VERSION ""

NS_ :

BS_:

BU_: VMCU TECU OBDScanT2 IC3 EMS ECUspare2 ECUspare1 DACU CIOM BBM

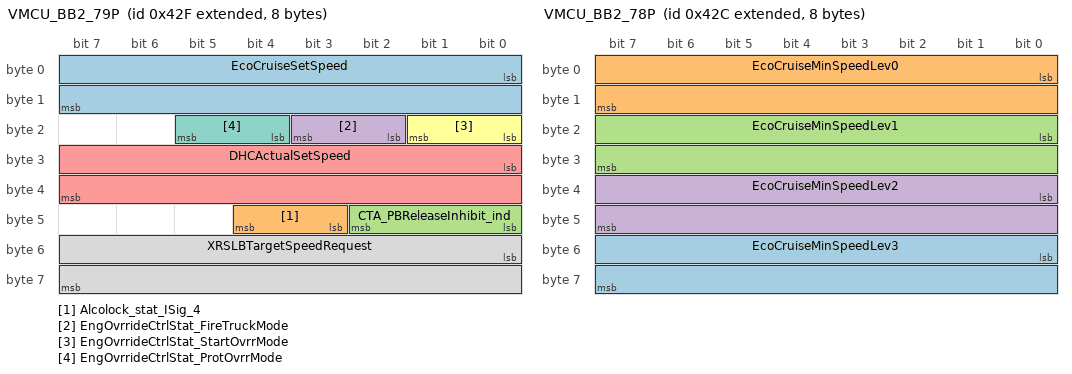
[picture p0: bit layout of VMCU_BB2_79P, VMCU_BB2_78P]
BO_ 2147484719 VMCU_BB2_79P: 8 VMCU
 SG_ EcoCruiseSetSpeed : 0|16@1+ (0.00390625,0) [0|255.99609375] "Km_per_h"  IC3
 SG_ Alcolock_stat_ISig_4 : 43|2@1+ (1,0) [0|0] ""  BBM
 SG_ CTA_PBReleaseInhibit_ind : 40|3@1+ (1,0) [0|0] ""  IC3,BBM
 SG_ EngOvrrideCtrlStat_FireTruckMode : 18|2@1+ (1,0) [0|0] ""  EMS
 SG_ DHCActualSetSpeed : 24|16@1+ (0.00390625,0) [0|255.99609375] "Km_per_h"  IC3
 SG_ EngOvrrideCtrlStat_StartOvrrMode : 16|2@1+ (1,0) [0|0] ""  EMS
 SG_ EngOvrrideCtrlStat_ProtOvrrMode : 20|2@1+ (1,0) [0|0] ""  EMS
 SG_ XRSLBTargetSpeedRequest : 48|16@1+ (0.00390625,0) [0|255.99609375] "Km_per_h"  TECU,EMS

BO_ 2147484716 VMCU_BB2_78P: 8 VMCU
 SG_ EcoCruiseMinSpeedLev3 : 48|16@1+ (0.00390625,0) [0|255.99609375] "Km_per_h"  IC3
 SG_ EcoCruiseMinSpeedLev0 : 0|16@1+ (0.00390625,0) [0|255.99609375] "Km_per_h"  IC3
 SG_ EcoCruiseMinSpeedLev1 : 16|16@1+ (0.00390625,0) [0|255.99609375] "Km_per_h"  IC3
 SG_ EcoCruiseMinSpeedLev2 : 32|16@1+ (0.00390625,0) [0|255.99609375] "Km_per_h"  IC3

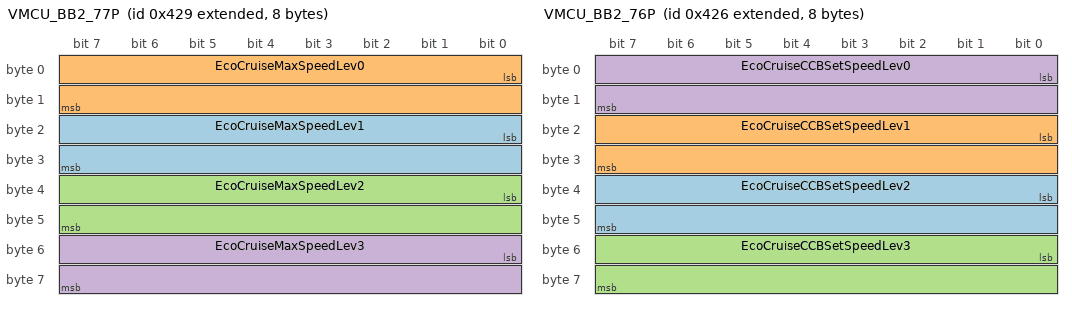
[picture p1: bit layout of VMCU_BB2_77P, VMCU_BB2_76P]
BO_ 2147484713 VMCU_BB2_77P: 8 VMCU
 SG_ EcoCruiseMaxSpeedLev1 : 16|16@1+ (0.00390625,0) [0|255.99609375] "Km_per_h"  IC3
 SG_ EcoCruiseMaxSpeedLev0 : 0|16@1+ (0.00390625,0) [0|255.99609375] "Km_per_h"  IC3
 SG_ EcoCruiseMaxSpeedLev2 : 32|16@1+ (0.00390625,0) [0|255.99609375] "Km_per_h"  IC3
 SG_ EcoCruiseMaxSpeedLev3 : 48|16@1+ (0.00390625,0) [0|255.99609375] "Km_per_h"  IC3

BO_ 2147484710 VMCU_BB2_76P: 8 VMCU
 SG_ EcoCruiseCCBSetSpeedLev2 : 32|16@1+ (0.00390625,0) [0|255.99609375] "Km_per_h"  IC3
 SG_ EcoCruiseCCBSetSpeedLev1 : 16|16@1+ (0.00390625,0) [0|255.99609375] "Km_per_h"  IC3
 SG_ EcoCruiseCCBSetSpeedLev3 : 48|16@1+ (0.00390625,0) [0|255.99609375] "Km_per_h"  IC3
 SG_ EcoCruiseCCBSetSpeedLev0 : 0|16@1+ (0.00390625,0) [0|255.99609375] "Km_per_h"  IC3

BO_ 2147485052 VMCU_BB2_75P: 8 VMCU
 SG_ EngineGreenAreaOutLNG_ISig_4 : 32|32@1+ (0.01,0) [0|42949672.95] "kg"  IC3
 SG_ EngineGreenAreaLNG_ISig_4 : 0|32@1+ (0.01,0) [0|42949672.95] "kg"  IC3

BO_ 2147484683 VMCU_BB2_74P: 8 VMCU
 SG_ BatteryTempAlert_rqst_ISig_4 : 4|3@1+ (1,0) [0|0] ""  IC3
 SG_ APM_TrailerCircPressureStatus_IS : 52|2@1+ (1,0) [0|0] ""  IC3
 SG_ BatteryCapacity_ISig_4 : 0|4@1+ (1,0) [0|0] ""  IC3
 SG_ Hazard_rqst_ISig_4 : 54|2@1+ (1,0) [0|0] ""  IC3
 SG_ CollisionSituationAliveStatus : 44|4@1+ (1,0) [0|15] "Count"  DACU
 SG_ BatterySOCact_ISig_4 : 8|8@1+ (0.5,0) [0|127.5] "Percent"  IC3
 SG_ Trailer1TPMLostCom_ISig_4 : 35|2@1+ (1,0) [0|0] ""  IC3
 SG_ BatterySOCactCriticalAlert_ISig_ : 16|8@1+ (0.5,0) [0|127.5] "Percent"  IC3
 SG_ BatteryTempAlertRawData_rqst_ISi : 32|3@1+ (1,0) [0|0] ""  IC3
 SG_ FPBRMMIStat_FPBRChangeAck_ISig_4 : 50|2@1+ (1,0) [0|0] ""  CIOM
 SG_ Trailer2TPMLostCom_UB_ISig_4 : 39|1@1+ (1,0) [0|0] ""  IC3
 SG_ LivBatteryCharging_stat_ISig_4 : 56|2@1+ (1,0) [0|0] ""  CIOM,IC3
 SG_ BatteryTemp_ISig_4 : 24|8@1+ (1,-45) [-45|210] "DegreeC"  IC3
 SG_ Trailer1TPMLostCom_UB_ISig_4 : 7|1@1+ (1,0) [0|0] ""  IC3
 SG_ FPBRMMIStat_FPBRStatusInd_ISig_4 : 48|2@1+ (1,0) [0|0] ""  CIOM
 SG_ Trailer2TPMLostCom_ISig_4 : 37|2@1+ (1,0) [0|0] ""  IC3
 SG_ CollisionSituationAliveRequest : 40|4@1+ (1,0) [0|15] "Count"  DACU

BO_ 2147484680 VMCU_BB2_73P: 8 VMCU
 SG_ TPMMateTrailerResp_ISig_4 : 32|3@1+ (1,0) [0|0] ""  IC3
 SG_ Trailer2TPMLeakageWarning_ISig_4 : 19|3@1+ (1,0) [0|0] ""  IC3
 SG_ TPMAutomaticMating_ISig_4 : 30|2@1+ (1,0) [0|0] ""  IC3
 SG_ Trailer2TPMPressureWarning_UB_IS : 55|1@1+ (1,0) [0|0] ""  IC3
 SG_ TruckTPMLeakageWarning_UB_ISig_4 : 56|1@1+ (1,0) [0|0] ""  IC3
 SG_ Trailer2TPMMatedStatus_ISig_4 : 14|2@1+ (1,0) [0|0] ""  IC3
 SG_ Trailer1TPMMatedStatus_ISig_4 : 22|2@1+ (1,0) [0|0] ""  IC3
 SG_ Trailer2TPMLeakageWarning_UB_ISi : 54|1@1+ (1,0) [0|0] ""  IC3
 SG_ Trailer1TPMLeakageWarning_UB_ISi : 52|1@1+ (1,0) [0|0] ""  IC3
 SG_ TruckTPMLeakageWarning_ISig_4 : 11|3@1+ (1,0) [0|0] ""  IC3
 SG_ Trailer1TPMPressureWarning_UB_IS : 53|1@1+ (1,0) [0|0] ""  IC3
 SG_ ExtraSideMarkers_FunctStat : 58|2@1+ (1,0) [0|0] ""  CIOM
 SG_ TruckTPMPressureWarning_UB_ISig_ : 57|1@1+ (1,0) [0|0] ""  IC3
 SG_ Trailer2TPMPressureWarning_ISig_ : 16|3@1+ (1,0) [0|0] ""  IC3
 SG_ Trailer1TPMPressureWarning_ISig_ : 24|3@1+ (1,0) [0|0] ""  IC3
 SG_ Trailer1TPMLeakageWarning_ISig_4 : 27|3@1+ (1,0) [0|0] ""  IC3
 SG_ LiftAxle1RequestResponse : 35|4@1+ (1,0) [0|0] ""  IC3
 SG_ TruckTPMPressureWarning_ISig_4 : 8|3@1+ (1,0) [0|0] ""  IC3
 SG_ XRSLIndication : 0|8@1+ (1,0) [0|255] "Km_per_h"  BBM,IC3
 SG_ TPMMateTrailerResp_UB_ISig_4 : 39|1@1+ (1,0) [0|0] ""  IC3

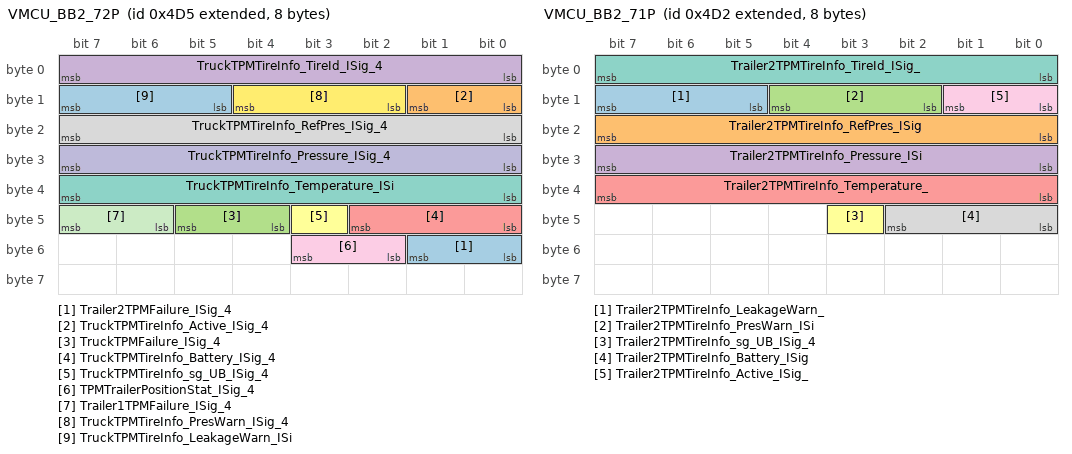
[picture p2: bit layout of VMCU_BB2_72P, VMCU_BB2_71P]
BO_ 2147484885 VMCU_BB2_72P: 8 VMCU
 SG_ Trailer2TPMFailure_ISig_4 : 48|2@1+ (1,0) [0|0] ""  IC3
 SG_ TruckTPMTireInfo_Active_ISig_4 : 8|2@1+ (1,0) [0|0] ""  IC3
 SG_ TruckTPMFailure_ISig_4 : 44|2@1+ (1,0) [0|0] ""  IC3
 SG_ TruckTPMTireInfo_TireId_ISig_4 : 0|8@1+ (1,0) [0|255] "NotApplicable"  IC3
 SG_ TruckTPMTireInfo_Battery_ISig_4 : 40|3@1+ (1,0) [0|0] ""  IC3
 SG_ TruckTPMTireInfo_sg_UB_ISig_4 : 43|1@1+ (1,0) [0|0] ""  IC3
 SG_ TruckTPMTireInfo_Temperature_ISi : 32|8@1+ (1,-50) [-50|205] "DegreeC"  IC3
 SG_ TruckTPMTireInfo_RefPres_ISig_4 : 16|8@1+ (10,0) [0|2550] "kPa"  IC3
 SG_ TPMTrailerPositionStat_ISig_4 : 50|2@1+ (1,0) [0|0] ""  IC3
 SG_ TruckTPMTireInfo_Pressure_ISig_4 : 24|8@1+ (10,0) [0|2550] "kPa"  IC3
 SG_ Trailer1TPMFailure_ISig_4 : 46|2@1+ (1,0) [0|0] ""  IC3
 SG_ TruckTPMTireInfo_PresWarn_ISig_4 : 10|3@1+ (1,0) [0|0] ""  IC3
 SG_ TruckTPMTireInfo_LeakageWarn_ISi : 13|3@1+ (1,0) [0|0] ""  IC3

BO_ 2147484882 VMCU_BB2_71P: 8 VMCU
 SG_ Trailer2TPMTireInfo_LeakageWarn_ : 13|3@1+ (1,0) [0|0] ""  IC3
 SG_ Trailer2TPMTireInfo_RefPres_ISig : 16|8@1+ (10,0) [0|2550] "kPa"  IC3
 SG_ Trailer2TPMTireInfo_PresWarn_ISi : 10|3@1+ (1,0) [0|0] ""  IC3
 SG_ Trailer2TPMTireInfo_Pressure_ISi : 24|8@1+ (10,0) [0|2550] "kPa"  IC3
 SG_ Trailer2TPMTireInfo_Temperature_ : 32|8@1+ (1,-50) [-50|205] "DegreeC"  IC3
 SG_ Trailer2TPMTireInfo_sg_UB_ISig_4 : 43|1@1+ (1,0) [0|0] ""  IC3
 SG_ Trailer2TPMTireInfo_TireId_ISig_ : 0|8@1+ (1,0) [0|255] "NotApplicable"  IC3
 SG_ Trailer2TPMTireInfo_Battery_ISig : 40|3@1+ (1,0) [0|0] ""  IC3
 SG_ Trailer2TPMTireInfo_Active_ISig_ : 8|2@1+ (1,0) [0|0] ""  IC3

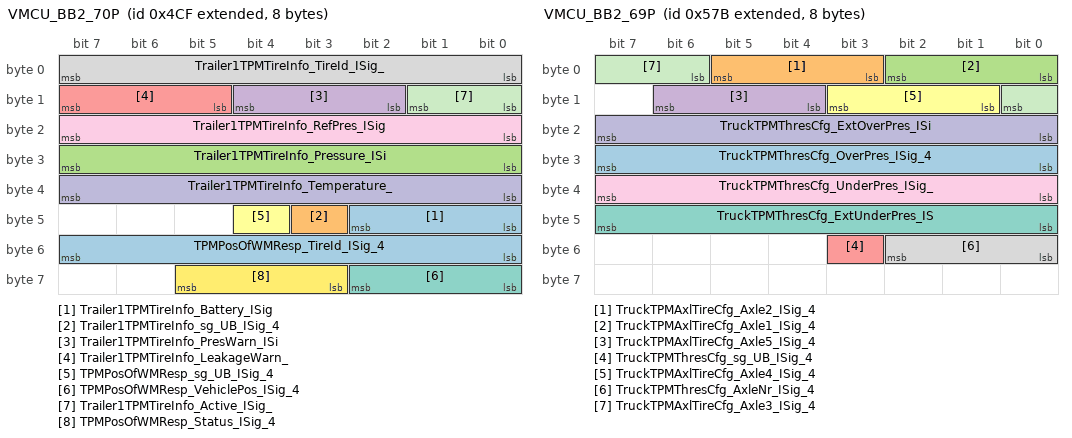
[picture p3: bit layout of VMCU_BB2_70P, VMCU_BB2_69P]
BO_ 2147484879 VMCU_BB2_70P: 8 VMCU
 SG_ Trailer1TPMTireInfo_Battery_ISig : 40|3@1+ (1,0) [0|0] ""  IC3
 SG_ Trailer1TPMTireInfo_sg_UB_ISig_4 : 43|1@1+ (1,0) [0|0] ""  IC3
 SG_ Trailer1TPMTireInfo_Pressure_ISi : 24|8@1+ (10,0) [0|2550] "kPa"  IC3
 SG_ Trailer1TPMTireInfo_PresWarn_ISi : 10|3@1+ (1,0) [0|0] ""  IC3
 SG_ Trailer1TPMTireInfo_LeakageWarn_ : 13|3@1+ (1,0) [0|0] ""  IC3
 SG_ TPMPosOfWMResp_sg_UB_ISig_4 : 44|1@1+ (1,0) [0|0] ""  IC3
 SG_ TPMPosOfWMResp_VehiclePos_ISig_4 : 56|3@1+ (1,0) [0|0] ""  IC3
 SG_ Trailer1TPMTireInfo_TireId_ISig_ : 0|8@1+ (1,0) [0|255] "NotApplicable"  IC3
 SG_ Trailer1TPMTireInfo_RefPres_ISig : 16|8@1+ (10,0) [0|2550] "kPa"  IC3
 SG_ Trailer1TPMTireInfo_Temperature_ : 32|8@1+ (1,-50) [-50|205] "DegreeC"  IC3
 SG_ Trailer1TPMTireInfo_Active_ISig_ : 8|2@1+ (1,0) [0|0] ""  IC3
 SG_ TPMPosOfWMResp_Status_ISig_4 : 59|3@1+ (1,0) [0|0] ""  IC3
 SG_ TPMPosOfWMResp_TireId_ISig_4 : 48|8@1+ (1,0) [0|255] "NotApplicable"  IC3

BO_ 2147485051 VMCU_BB2_69P: 8 VMCU
 SG_ TruckTPMThresCfg_OverPres_ISig_4 : 24|8@1+ (1,-125) [-125|130] "Percent"  IC3
 SG_ TruckTPMAxlTireCfg_Axle2_ISig_4 : 3|3@1+ (1,0) [0|0] ""  IC3
 SG_ TruckTPMAxlTireCfg_Axle1_ISig_4 : 0|3@1+ (1,0) [0|0] ""  IC3
 SG_ TruckTPMAxlTireCfg_Axle5_ISig_4 : 12|3@1+ (1,0) [0|0] ""  IC3
 SG_ TruckTPMThresCfg_sg_UB_ISig_4 : 51|1@1+ (1,0) [0|0] ""  IC3
 SG_ TruckTPMAxlTireCfg_Axle4_ISig_4 : 9|3@1+ (1,0) [0|0] ""  IC3
 SG_ TruckTPMThresCfg_ExtUnderPres_IS : 40|8@1+ (1,-125) [-125|130] "Percent"  IC3
 SG_ TruckTPMThresCfg_AxleNr_ISig_4 : 48|3@1+ (1,0) [0|0] ""  IC3
 SG_ TruckTPMThresCfg_UnderPres_ISig_ : 32|8@1+ (1,-125) [-125|130] "Percent"  IC3
 SG_ TruckTPMThresCfg_ExtOverPres_ISi : 16|8@1+ (1,-125) [-125|130] "Percent"  IC3
 SG_ TruckTPMAxlTireCfg_Axle3_ISig_4 : 6|3@1+ (1,0) [0|0] ""  IC3

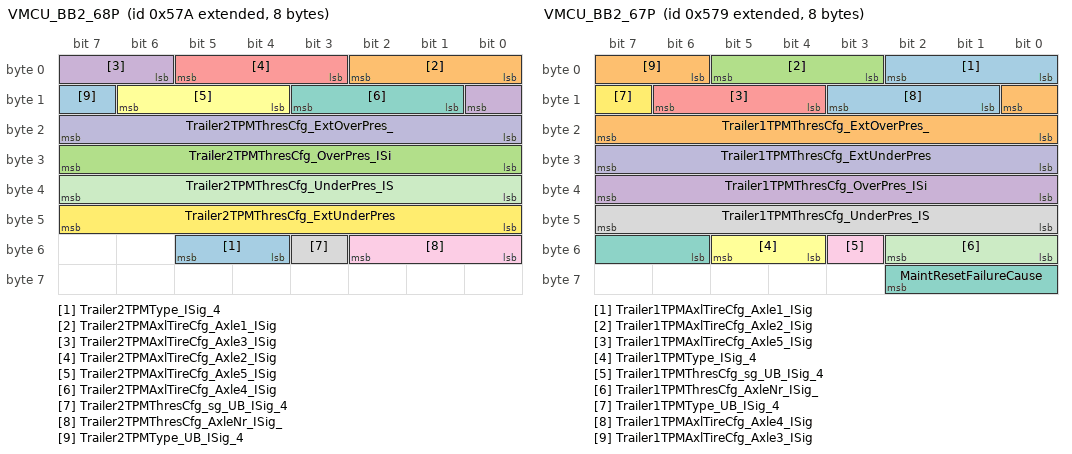
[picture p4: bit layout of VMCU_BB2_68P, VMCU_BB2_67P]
BO_ 2147485050 VMCU_BB2_68P: 8 VMCU
 SG_ Trailer2TPMType_ISig_4 : 52|2@1+ (1,0) [0|0] ""  IC3
 SG_ Trailer2TPMAxlTireCfg_Axle1_ISig : 0|3@1+ (1,0) [0|0] ""  IC3
 SG_ Trailer2TPMThresCfg_OverPres_ISi : 24|8@1+ (1,-125) [-125|130] "Percent"  IC3
 SG_ Trailer2TPMAxlTireCfg_Axle3_ISig : 6|3@1+ (1,0) [0|0] ""  IC3
 SG_ Trailer2TPMAxlTireCfg_Axle2_ISig : 3|3@1+ (1,0) [0|0] ""  IC3
 SG_ Trailer2TPMAxlTireCfg_Axle5_ISig : 12|3@1+ (1,0) [0|0] ""  IC3
 SG_ Trailer2TPMAxlTireCfg_Axle4_ISig : 9|3@1+ (1,0) [0|0] ""  IC3
 SG_ Trailer2TPMThresCfg_sg_UB_ISig_4 : 51|1@1+ (1,0) [0|0] ""  IC3
 SG_ Trailer2TPMThresCfg_AxleNr_ISig_ : 48|3@1+ (1,0) [0|0] ""  IC3
 SG_ Trailer2TPMThresCfg_ExtOverPres_ : 16|8@1+ (1,-125) [-125|130] "Percent"  IC3
 SG_ Trailer2TPMThresCfg_UnderPres_IS : 32|8@1+ (1,-125) [-125|130] "Percent"  IC3
 SG_ Trailer2TPMThresCfg_ExtUnderPres : 40|8@1+ (1,-125) [-125|130] "Percent"  IC3
 SG_ Trailer2TPMType_UB_ISig_4 : 15|1@1+ (1,0) [0|0] ""  IC3

BO_ 2147485049 VMCU_BB2_67P: 8 VMCU
 SG_ Trailer1TPMAxlTireCfg_Axle1_ISig : 0|3@1+ (1,0) [0|0] ""  IC3
 SG_ Trailer1TPMThresCfg_ExtOverPres_ : 16|8@1+ (1,-125) [-125|130] "Percent"  IC3
 SG_ Trailer1TPMAxlTireCfg_Axle2_ISig : 3|3@1+ (1,0) [0|0] ""  IC3
 SG_ Trailer1TPMThresCfg_OverPres_ISi : 32|8@1+ (1,-125) [-125|130] "Percent"  IC3
 SG_ Trailer1TPMAxlTireCfg_Axle5_ISig : 12|3@1+ (1,0) [0|0] ""  IC3
 SG_ Trailer1TPMType_ISig_4 : 52|2@1+ (1,0) [0|0] ""  IC3
 SG_ MaintResetFailureCause : 54|5@1+ (1,0) [0|0] ""  IC3
 SG_ Trailer1TPMThresCfg_UnderPres_IS : 40|8@1+ (1,-125) [-125|130] "Percent"  IC3
 SG_ Trailer1TPMThresCfg_sg_UB_ISig_4 : 51|1@1+ (1,0) [0|0] ""  IC3
 SG_ Trailer1TPMThresCfg_ExtUnderPres : 24|8@1+ (1,-125) [-125|130] "Percent"  IC3
 SG_ Trailer1TPMThresCfg_AxleNr_ISig_ : 48|3@1+ (1,0) [0|0] ""  IC3
 SG_ Trailer1TPMType_UB_ISig_4 : 15|1@1+ (1,0) [0|0] ""  IC3
 SG_ Trailer1TPMAxlTireCfg_Axle4_ISig : 9|3@1+ (1,0) [0|0] ""  IC3
 SG_ Trailer1TPMAxlTireCfg_Axle3_ISig : 6|3@1+ (1,0) [0|0] ""  IC3

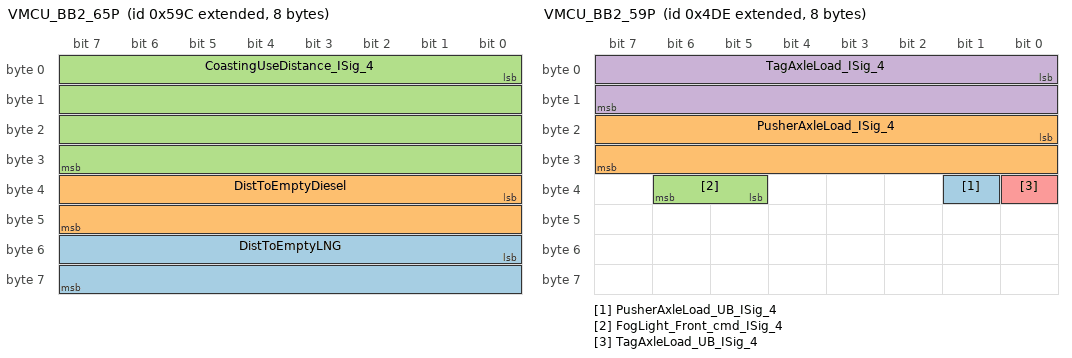
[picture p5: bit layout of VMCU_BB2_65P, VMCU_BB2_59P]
BO_ 2147485084 VMCU_BB2_65P: 8 VMCU
 SG_ DistToEmptyLNG : 48|16@1+ (1,0) [0|65535] "km"  IC3
 SG_ DistToEmptyDiesel : 32|16@1+ (1,0) [0|65535] "km"  IC3
 SG_ CoastingUseDistance_ISig_4 : 0|32@1+ (10,0) [0|42949672950] "m"  IC3

BO_ 2147485083 VMCU_BB2_64P: 8 VMCU
 SG_ EngSpeedOverThresholdTime_ISig_4 : 32|32@1+ (1,0) [0|4294967295] "s"  IC3
 SG_ EngLoadOverThresholdDistance_ISi : 0|32@1+ (10,0) [0|42949672950] "m"  IC3

BO_ 2147485082 VMCU_BB2_63P: 8 VMCU
 SG_ EngineGreenAreaFuel_ISig_4 : 32|32@1+ (0.01,0) [0|42949672.95] "l"  IC3
 SG_ LCCDistance_ISig_4 : 0|32@1+ (10,0) [0|42949672950] "m"  IC3

BO_ 2147485081 VMCU_BB2_62P: 8 VMCU
 SG_ StopCounter_ISig_4 : 0|32@1+ (1,0) [0|4294967295] ""  IC3
 SG_ OverspeedDistance_ISig_4 : 32|32@1+ (10,0) [0|42949672950] "m"  IC3

BO_ 2147485080 VMCU_BB2_61P: 8 VMCU
 SG_ RobotizedGboxPowerModeTime_ISig_ : 0|32@1+ (1,0) [0|4294967295] "s"  IC3
 SG_ TotalServiceBrakeCounter_ISig_4 : 32|32@1+ (1,0) [0|4294967295] ""  IC3

BO_ 2147485079 VMCU_BB2_60P: 8 VMCU
 SG_ RobotizedGboxManualModeTime_ISig : 32|32@1+ (1,0) [0|4294967295] "s"  IC3
 SG_ RobotizedGboxAutoModeTime_ISig_4 : 0|32@1+ (1,0) [0|4294967295] "s"  IC3

BO_ 2147484894 VMCU_BB2_59P: 8 VMCU
 SG_ PusherAxleLoad_UB_ISig_4 : 33|1@1+ (1,0) [0|0] ""  TECU,BBM,DACU,IC3
 SG_ PusherAxleLoad_ISig_4 : 16|16@1+ (0.5,0) [0|32767.5] "kg"  TECU,BBM,DACU
 SG_ FogLight_Front_cmd_ISig_4 : 37|2@1+ (1,0) [0|0] ""  BBM
 SG_ TagAxleLoad_ISig_4 : 0|16@1+ (0.5,0) [0|32767.5] "kg"  TECU,DACU,BBM
 SG_ TagAxleLoad_UB_ISig_4 : 32|1@1+ (1,0) [0|0] ""  BBM,IC3,DACU,TECU

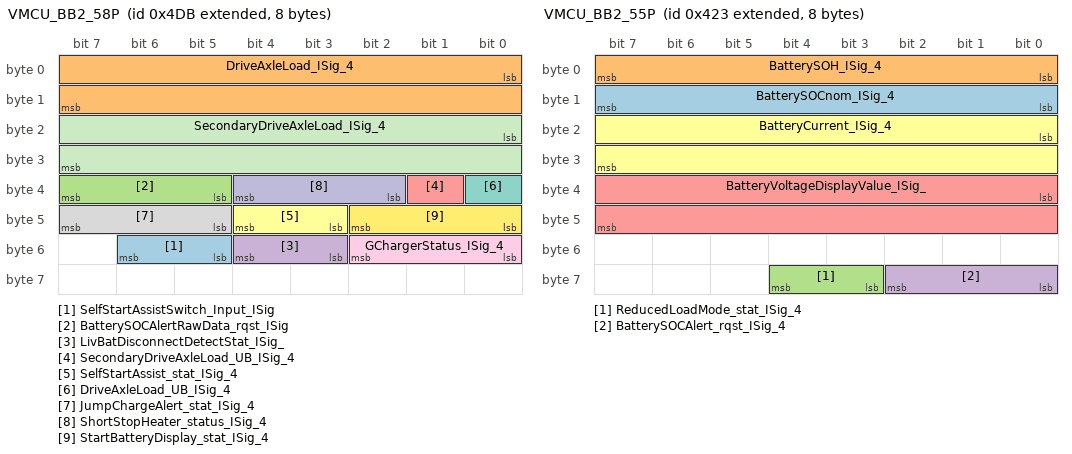
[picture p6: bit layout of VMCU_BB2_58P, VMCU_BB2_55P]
BO_ 2147484891 VMCU_BB2_58P: 8 VMCU
 SG_ SelfStartAssistSwitch_Input_ISig : 53|2@1+ (1,0) [0|0] ""  IC3
 SG_ DriveAxleLoad_ISig_4 : 0|16@1+ (0.5,0) [0|32767.5] "kg"  BBM,DACU,TECU
 SG_ BatterySOCAlertRawData_rqst_ISig : 37|3@1+ (1,0) [0|0] ""  BBM,CIOM
 SG_ LivBatDisconnectDetectStat_ISig_ : 51|2@1+ (1,0) [0|0] ""  IC3
 SG_ SecondaryDriveAxleLoad_UB_ISig_4 : 33|1@1+ (1,0) [0|0] ""  IC3,TECU,BBM,DACU
 SG_ SelfStartAssist_stat_ISig_4 : 43|2@1+ (1,0) [0|0] ""  EMS,IC3
 SG_ DriveAxleLoad_UB_ISig_4 : 32|1@1+ (1,0) [0|0] ""  BBM,IC3,TECU,DACU
 SG_ JumpChargeAlert_stat_ISig_4 : 45|3@1+ (1,0) [0|0] ""  IC3
 SG_ GChargerStatus_ISig_4 : 48|3@1+ (1,0) [0|0] ""  IC3
 SG_ ShortStopHeater_status_ISig_4 : 34|3@1+ (1,0) [0|0] ""  CIOM
 SG_ SecondaryDriveAxleLoad_ISig_4 : 16|16@1+ (0.5,0) [0|32767.5] "kg"  DACU,BBM,TECU
 SG_ StartBatteryDisplay_stat_ISig_4 : 40|3@1+ (1,0) [0|0] ""  IC3

BO_ 2147485057 VMCU_BB2_57P_HMIIOM_FCM: 8 IC3
 SG_ VMCU_BB2_57P_FCS_581 : 0|64@1+ (1,0) [0|0] ""  VMCU

BO_ 2147485056 VMCU_BB2_57P_HMIIOM: 15 VMCU
 SG_ MaintService_ServiceCalendarTime : 32|32@1+ (1,-2147483600) [-2147483600|2147483695] "s"  IC3
 SG_ MaintService_EngTimeID_ISig_4_58 : 112|8@1+ (1,0) [0|255] "ID"  IC3
 SG_ MaintService_DistID_ISig_4_580 : 96|8@1+ (1,0) [0|255] "ID"  IC3
 SG_ MaintService_ServiceDistance_ISi : 0|32@1+ (10,-21474836000) [-21474836000|21474836950] "m"  IC3
 SG_ MaintService_ServiceEngineTime_I : 64|32@1+ (1,-2147483600) [-2147483600|2147483695] "s"  IC3
 SG_ MaintService_CalDateID_ISig_4_58 : 104|8@1+ (1,0) [0|255] "ID"  IC3

BO_ 2147485047 VMCU_BB2_57P_FCM: 8 CIOM
 SG_ VMCU_BB2_57P_FCS_577 : 0|64@1+ (1,0) [0|0] ""  VMCU

BO_ 2147485046 VMCU_BB2_57P: 15 VMCU
 SG_ MaintService_ServiceEngineT_0000 : 64|32@1+ (1,-2147483600) [-2147483600|2147483695] "s"  CIOM
 SG_ MaintService_EngTimeID_ISig_4_57 : 112|8@1+ (1,0) [0|255] "ID"  CIOM
 SG_ MaintService_DistID_ISig_4_576 : 96|8@1+ (1,0) [0|255] "ID"  CIOM
 SG_ MaintService_ServiceDistanc_0000 : 0|32@1+ (10,-21474836000) [-21474836000|21474836950] "m"  CIOM
 SG_ MaintService_CalDateID_ISig_4_57 : 104|8@1+ (1,0) [0|255] "ID"  CIOM
 SG_ MaintService_ServiceCalenda_0000 : 32|32@1+ (1,-2147483600) [-2147483600|2147483695] "s"  CIOM

BO_ 2147485076 VMCU_BB2_56P: 8 VMCU
 SG_ EngTrueIdleSpeedTime_ISig_4 : 0|32@1+ (1,0) [0|4294967295] "s"  IC3
 SG_ EngineGreenAreaOutTime_ISig_4 : 32|32@1+ (1,0) [0|4294967295] "s"  IC3

BO_ 2147484707 VMCU_BB2_55P: 8 VMCU
 SG_ BatterySOCnom_ISig_4 : 8|8@1+ (0.5,0) [0|127.5] "Percent"  IC3
 SG_ BatterySOH_ISig_4 : 0|8@1+ (0.5,0) [0|127.5] "Percent"  IC3
 SG_ ReducedLoadMode_stat_ISig_4 : 59|2@1+ (1,0) [0|0] ""  CIOM
 SG_ BatterySOCAlert_rqst_ISig_4 : 56|3@1+ (1,0) [0|0] ""  IC3,BBM,CIOM
 SG_ BatteryVoltageDisplayValue_ISig_ : 32|16@1+ (0.05,0) [0|3276.75] "V"  IC3,BBM
 SG_ BatteryCurrent_ISig_4 : 16|16@1+ (0.05,-1600) [-1600|1676.75] "A"  EMS,IC3

BO_ 2147484573 VMCU_BB2_54P: 8 VMCU
 SG_ MaintOilQuality : 35|3@1+ (1,0) [0|0] ""  EMS
 SG_ ECSLimpHomeNotification_ISig_4 : 16|3@1+ (1,0) [0|0] ""  IC3
 SG_ MaintenanceResetStatus : 19|3@1+ (1,0) [0|0] ""  IC3
 SG_ FirstAxleLowerPrioSelected_ISig_ : 24|3@1+ (1,0) [0|0] ""  IC3
 SG_ MaintOilReset : 38|2@1+ (1,0) [0|0] ""  EMS
 SG_ RssInhibStartEngine_rqst : 6|2@1+ (1,0) [0|0] ""  IC3
 SG_ PositionLightRequest_status : 2|2@1+ (1,0) [0|0] ""  BBM,IC3
 SG_ ExtraBBTailLiftStatus_ISig_4 : 4|2@1+ (1,0) [0|0] ""  CIOM
 SG_ MaintenanceNotification_ISig_4 : 32|3@1+ (1,0) [0|0] ""  IC3
 SG_ ExtraBBSlidable5thWheelStatus : 0|2@1+ (1,0) [0|0] ""  BBM,CIOM
 SG_ ParkBrakeReleasePossible_stat : 10|2@1+ (1,0) [0|0] ""  TECU,IC3
 SG_ LoadDistributionALDChangeACK_ISi : 48|3@1+ (1,0) [0|0] ""  CIOM,IC3
 SG_ PoorAirPressureInfo_UB : 55|1@1+ (1,0) [0|0] ""  BBM,IC3
 SG_ ParkBrakeWorkshopMode_ISig_4 : 14|2@1+ (1,0) [0|0] ""  IC3
 SG_ ExtraBBContainerUnlockStatus : 46|2@1+ (1,0) [0|0] ""  BBM,CIOM
 SG_ MainBeamRequest_status_ISig_4 : 56|2@1+ (1,0) [0|0] ""  BBM,DACU
 SG_ ExtraBBCraneStatus_ISig_4 : 27|3@1+ (1,0) [0|0] ""  CIOM,BBM
 SG_ AirCompressorStatus : 58|2@1+ (1,0) [0|0] ""  EMS,BBM
 SG_ TrailerABSStatus_ISig_4 : 12|2@1+ (1,0) [0|0] ""  TECU,IC3,EMS,DACU
 SG_ RegenInhibitVehicleHeight_ISig_4 : 22|2@1+ (1,0) [0|0] ""  EMS
 SG_ PoorAirPressureInfo : 51|2@1+ (1,0) [0|0] ""  BBM,IC3
 SG_ FogLightRearRequest_stat : 8|2@1+ (1,0) [0|0] ""  BBM
 SG_ MainBeam_cmd_ISig_4 : 60|3@1+ (1,0) [0|0] ""  BBM
 SG_ FrontParkBrakeOverrideInd_ISig_4 : 53|2@1+ (1,0) [0|0] ""  IC3

BO_ 2147484497 VMCU_BB2_53P: 8 VMCU
 SG_ AuxSwitchBbLoad4_cmd : 14|2@1+ (1,0) [0|0] ""  BBM
 SG_ AuxSwitchBbLoad1_Status_ISig_4 : 0|2@1+ (1,0) [0|0] ""  CIOM,BBM
 SG_ BrakeLightConvoy_rqst_UB_ISig_4 : 45|1@1+ (1,0) [0|0] ""  BBM
 SG_ AuxSwitchBbLoad3_cmd : 12|2@1+ (1,0) [0|0] ""  BBM
 SG_ MainBeam_rqst : 40|3@1+ (1,0) [0|0] ""  IC3
 SG_ BatterySOCTrustLevel_ISig_4 : 56|8@1+ (0.5,0) [0|127.5] "Percent"  IC3
 SG_ AuxSwitchBbLoad4_Status_ISig_4 : 6|2@1+ (1,0) [0|0] ""  CIOM,BBM
 SG_ BrakeLightConvoy_rqst_ISig_4 : 30|2@1+ (1,0) [0|0] ""  BBM
 SG_ DoorWarningLight_cmd_ISig_4 : 38|2@1+ (1,0) [0|0] ""  CIOM
 SG_ BlackOutandConvoyMode_rqst_ISig_ : 35|3@1+ (1,0) [0|0] ""  IC3,DACU,BBM
 SG_ DirIndicatorRqstLights_stat : 32|3@1+ (1,0) [0|0] ""  BBM
 SG_ DippedBeamRequest_status : 24|2@1+ (1,0) [0|0] ""  BBM
 SG_ AuxSwitchBbLoad3_Status_ISig_4 : 4|2@1+ (1,0) [0|0] ""  CIOM,BBM
 SG_ DoorInstepLight_cmd_ISig_4 : 43|2@1+ (1,0) [0|0] ""  CIOM
 SG_ DRLRequest_status : 26|2@1+ (1,0) [0|0] ""  BBM
 SG_ AuxSwitchBbLoad6_Status_ISig_4 : 10|2@1+ (1,0) [0|0] ""  BBM,CIOM
 SG_ AuxSwitchBbLoad2_Status_ISig_4 : 2|2@1+ (1,0) [0|0] ""  CIOM,BBM
 SG_ AuxSwitchBbLoad5_cmd : 16|2@1+ (1,0) [0|0] ""  BBM
 SG_ PBReleaseInhibit_EPBState_ISig_4 : 48|3@1+ (1,0) [0|0] ""  BBM
 SG_ ExtStaticTrailerBrake_Stat_ISig_ : 46|2@1+ (1,0) [0|0] ""  IC3,BBM
 SG_ AuxSwitchBbLoad5_Status_ISig_4 : 8|2@1+ (1,0) [0|0] ""  CIOM,BBM
 SG_ DoubleFrontAxleSteeringWarning_I : 20|2@1+ (1,0) [0|0] ""  IC3
 SG_ AuxSwitchBbLoad6_cmd : 18|2@1+ (1,0) [0|0] ""  BBM
 SG_ AcceleratorPedalTestStatus : 51|3@1+ (1,0) [0|0] ""  IC3

CM_ SG_ 2147485052 EngineGreenAreaOutLNG_ISig_4 "4294967295 Not available
";
CM_ SG_ 2147484894 PusherAxleLoad_ISig_4 "65024 - 65279 Error ; 65280 - 65535 Not available";
CM_ SG_ 2147484894 TagAxleLoad_ISig_4 "65024 - 65279 Error ; 65280 - 65535 Not available";
CM_ SG_ 2147484891 DriveAxleLoad_ISig_4 "65024 - 65279 Error ; 65280 - 65535 Not available";
CM_ SG_ 2147484891 SecondaryDriveAxleLoad_ISig_4 "65024 - 65279 Error ; 65280 - 65535 Not available";
CM_ SG_ 2147485076 EngTrueIdleSpeedTime_ISig_4 "4294967295 Not available";
CM_ SG_ 2147485076 EngineGreenAreaOutTime_ISig_4 "4294967295 Not available";
CM_ SG_ 2147484707 BatterySOCnom_ISig_4 "254 Error ; 255 Not available";
CM_ SG_ 2147484707 BatterySOH_ISig_4 "254 Error ; 255 Not available";
CM_ SG_ 2147484707 BatteryVoltageDisplayValue_ISig_ "65024 - 65279 Error ; 65280 - 65535 Not available";
CM_ SG_ 2147484707 BatteryCurrent_ISig_4 "65024 - 65279 Error ; 65280 - 65535 Not available";
BA_DEF_ BO_  "GenMsgStartDelayTime" INT 0 0;
BA_DEF_ BO_  "GenMsgDelayTime" INT 0 0;
BA_DEF_ BO_  "GenMsgCycleTime" INT 0 0;
BA_DEF_ BO_  "GenMsgSendType" ENUM  "Cyclic","NotUsed","NotUsed","NotUsed","NotUsed","NotUsed","NotUsed","IfActive","NoMsgSendType","NotUsed";
BA_DEF_ SG_  "GenSigStartValue" INT 0 0;
BA_DEF_ SG_  "GenSigCycleTimeActive" INT 0 0;
BA_DEF_ SG_  "GenSigCycleTime" INT 0 0;
BA_DEF_ SG_  "GenSigSendType" ENUM  "Cyclic","OnWrite","OnWriteWithRepetition","OnChange","OnChangeWithRepetition","IfActive","IfActiveWithRepetition","NoSigSendType","NotUsed","NotUsed","NotUsed","NotUsed","NotUsed";
BA_DEF_ BO_  "VFrameFormat" ENUM  "StandardCAN","ExtendedCAN","reserved","J1939PG";
BA_DEF_ SG_  "SigType" ENUM  "Default","Range","RangeSigned","ASCII","Discrete","Control","ReferencePGN","DTC","StringDelimiter","StringLength","StringLengthControl";
BA_DEF_ SG_  "SeToolVersion_SIGNAL" STRING ;
BA_DEF_ SG_  "SeToolUniqueID_SIGNAL" STRING ;
BA_DEF_ SG_  "SeToolOwnerSigGroup_SIGNAL" STRING ;
BA_DEF_ SG_  "SeToolOwnerSigGroupID_SIGNAL" STRING ;
BA_DEF_ SG_  "SeToolName_SIGNAL" STRING ;
BA_DEF_ SG_  "SeToolItemID_SIGNAL" STRING ;
BA_DEF_ SG_  "SeToolAncestorID_SIGNAL" STRING ;
BA_DEF_ SG_  "Platform_VMCU1_Sig" ENUM  "No","Yes";
BA_DEF_ BO_  "NmAsrMessage" ENUM  "No","Yes";
BA_DEF_ SG_  "NeedsUpdateBit" ENUM  "No","Yes";
BA_DEF_ SG_  "MmAnSignal" ENUM  "No","Yes";
BA_DEF_ SG_  "GenSigMaxLatency" INT 0 65535;
BA_DEF_ SG_  "GenSigILSupport" ENUM  "Yes","No";
BA_DEF_ BO_  "GenMsgRequestable" INT 0 1;
BA_DEF_ BO_  "GenMsgILSupport" ENUM  "No","Yes";
BA_DEF_ BO_  "DiagUUDTResponse" ENUM  "No","Yes";
BA_DEF_ BO_  "DiagState" ENUM  "No","Yes";
BA_DEF_ BO_  "DiagResponse" ENUM  "No","Yes";
BA_DEF_ BO_  "DiagRequest" ENUM  "No","Yes";
BA_DEF_ BO_  "DiagConnection" HEX 0 65535;
BA_DEF_ BO_  "CanTpSTmin" INT 0 255;
BA_DEF_ BO_  "CanTpFcFrameId" HEX 0 2147483647;
BA_DEF_ BO_  "CanTpBs" INT 0 255;
BA_DEF_ SG_  "SystemSignalLongSymbol" STRING ;
BA_DEF_REL_ BU_SG_REL_  "GenSigTimeoutTime" INT 0 65535;
BA_DEF_REL_ BU_SG_REL_  "GenSigFirstTimeoutTime" INT 0 65535;
BA_DEF_DEF_  "GenMsgStartDelayTime" 0;
BA_DEF_DEF_  "GenMsgDelayTime" 0;
BA_DEF_DEF_  "GenMsgCycleTime" 0;
BA_DEF_DEF_  "GenMsgSendType" "Cyclic";
BA_DEF_DEF_  "GenSigStartValue" 0;
BA_DEF_DEF_  "GenSigCycleTimeActive" 0;
BA_DEF_DEF_  "GenSigCycleTime" 0;
BA_DEF_DEF_  "GenSigSendType" "Cyclic";
BA_DEF_DEF_  "VFrameFormat" "ExtendedCAN";
BA_DEF_DEF_  "SigType" "Default";
BA_DEF_DEF_  "SeToolVersion_SIGNAL" "";
BA_DEF_DEF_  "SeToolUniqueID_SIGNAL" "";
BA_DEF_DEF_  "SeToolOwnerSigGroup_SIGNAL" "";
BA_DEF_DEF_  "SeToolOwnerSigGroupID_SIGNAL" "";
BA_DEF_DEF_  "SeToolName_SIGNAL" "";
BA_DEF_DEF_  "SeToolItemID_SIGNAL" "";
BA_DEF_DEF_  "SeToolAncestorID_SIGNAL" "";
BA_DEF_DEF_  "Platform_VMCU1_Sig" "No";
BA_DEF_DEF_  "NmAsrMessage" "No";
BA_DEF_DEF_  "NeedsUpdateBit" "No";
BA_DEF_DEF_  "MmAnSignal" "No";
BA_DEF_DEF_  "GenSigMaxLatency" 0;
BA_DEF_DEF_  "GenSigILSupport" "Yes";
BA_DEF_DEF_  "GenMsgRequestable" 1;
BA_DEF_DEF_  "GenMsgILSupport" "Yes";
BA_DEF_DEF_  "DiagUUDTResponse" "No";
BA_DEF_DEF_  "DiagState" "No";
BA_DEF_DEF_  "DiagResponse" "No";
BA_DEF_DEF_  "DiagRequest" "No";
BA_DEF_DEF_  "DiagConnection" 0;
BA_DEF_DEF_  "CanTpSTmin" 0;
BA_DEF_DEF_  "CanTpFcFrameId" 2147483647;
BA_DEF_DEF_  "CanTpBs" 255;
BA_DEF_DEF_REL_ "GenSigTimeoutTime" 0;
BA_DEF_DEF_REL_ "GenSigFirstTimeoutTime" 0;
BA_DEF_DEF_  "SystemSignalLongSymbol" "";
BA_ "GenMsgCycleTime" BO_ 2147484719 150;
BA_ "GenMsgStartDelayTime" BO_ 2147484719 55;
BA_ "GenMsgCycleTime" BO_ 2147484716 150;
BA_ "GenMsgStartDelayTime" BO_ 2147484716 35;
BA_ "GenMsgCycleTime" BO_ 2147484713 150;
BA_ "GenMsgStartDelayTime" BO_ 2147484713 20;
BA_ "GenMsgCycleTime" BO_ 2147484710 150;
BA_ "GenMsgStartDelayTime" BO_ 2147484710 40;
BA_ "GenMsgCycleTime" BO_ 2147485052 1000;
BA_ "GenMsgStartDelayTime" BO_ 2147485052 360;
BA_ "GenMsgCycleTime" BO_ 2147484683 100;
BA_ "GenMsgStartDelayTime" BO_ 2147484683 20;
BA_ "GenMsgCycleTime" BO_ 2147484680 100;
BA_ "GenMsgStartDelayTime" BO_ 2147484680 80;
BA_ "GenMsgCycleTime" BO_ 2147484885 200;
BA_ "GenMsgStartDelayTime" BO_ 2147484885 100;
BA_ "GenMsgCycleTime" BO_ 2147484882 200;
BA_ "GenMsgStartDelayTime" BO_ 2147484882 120;
BA_ "GenMsgCycleTime" BO_ 2147484879 200;
BA_ "GenMsgStartDelayTime" BO_ 2147484879 140;
BA_ "GenMsgCycleTime" BO_ 2147485051 1000;
BA_ "GenMsgStartDelayTime" BO_ 2147485051 280;
BA_ "GenMsgCycleTime" BO_ 2147485050 1000;
BA_ "GenMsgStartDelayTime" BO_ 2147485050 320;
BA_ "GenMsgCycleTime" BO_ 2147485049 1000;
BA_ "GenMsgStartDelayTime" BO_ 2147485049 350;
BA_ "GenMsgCycleTime" BO_ 2147485084 1000;
BA_ "GenMsgStartDelayTime" BO_ 2147485084 345;
BA_ "GenMsgCycleTime" BO_ 2147485083 1000;
BA_ "GenMsgStartDelayTime" BO_ 2147485083 230;
BA_ "GenMsgCycleTime" BO_ 2147485082 1000;
BA_ "GenMsgStartDelayTime" BO_ 2147485082 155;
BA_ "GenMsgCycleTime" BO_ 2147485081 1000;
BA_ "GenMsgStartDelayTime" BO_ 2147485081 110;
BA_ "GenMsgCycleTime" BO_ 2147485080 1000;
BA_ "GenMsgStartDelayTime" BO_ 2147485080 720;
BA_ "GenMsgCycleTime" BO_ 2147485079 1000;
BA_ "GenMsgStartDelayTime" BO_ 2147485079 680;
BA_ "GenMsgCycleTime" BO_ 2147484894 250;
BA_ "GenMsgStartDelayTime" BO_ 2147484894 105;
BA_ "GenMsgCycleTime" BO_ 2147484891 250;
BA_ "GenMsgStartDelayTime" BO_ 2147484891 75;
BA_ "GenMsgILSupport" BO_ 2147485057 0;
BA_ "GenMsgSendType" BO_ 2147485057 8;
BA_ "CanTpFcFrameId" BO_ 2147485056 1409;
BA_ "GenMsgCycleTime" BO_ 2147485056 1000;
BA_ "GenMsgStartDelayTime" BO_ 2147485056 200;
BA_ "GenMsgILSupport" BO_ 2147485047 0;
BA_ "GenMsgSendType" BO_ 2147485047 8;
BA_ "CanTpFcFrameId" BO_ 2147485046 1399;
BA_ "GenMsgCycleTime" BO_ 2147485046 1000;
BA_ "GenMsgStartDelayTime" BO_ 2147485046 175;
BA_ "GenMsgCycleTime" BO_ 2147485076 1000;
BA_ "GenMsgStartDelayTime" BO_ 2147485076 170;
BA_ "GenMsgCycleTime" BO_ 2147484707 150;
BA_ "GenMsgStartDelayTime" BO_ 2147484707 65;
BA_ "GenMsgCycleTime" BO_ 2147484573 75;
BA_ "GenMsgStartDelayTime" BO_ 2147484573 20;
BA_ "GenMsgCycleTime" BO_ 2147484497 50;
BA_ "GenMsgStartDelayTime" BO_ 2147484497 15;
BA_ "GenSigCycleTime" SG_ 2147484719 EcoCruiseSetSpeed 100;
BA_ "GenSigCycleTimeActive" SG_ 2147484719 EcoCruiseSetSpeed 100;
BA_ "GenSigStartValue" SG_ 2147484719 EcoCruiseSetSpeed 65535;
BA_ "Platform_VMCU1_Sig" SG_ 2147484719 EcoCruiseSetSpeed 1;
BA_ "GenSigCycleTime" SG_ 2147484719 Alcolock_stat_ISig_4 100;
BA_ "GenSigCycleTimeActive" SG_ 2147484719 Alcolock_stat_ISig_4 100;
BA_ "GenSigStartValue" SG_ 2147484719 Alcolock_stat_ISig_4 3;
BA_ "Platform_VMCU1_Sig" SG_ 2147484719 Alcolock_stat_ISig_4 1;
BA_ "GenSigCycleTime" SG_ 2147484719 CTA_PBReleaseInhibit_ind 100;
BA_ "GenSigCycleTimeActive" SG_ 2147484719 CTA_PBReleaseInhibit_ind 100;
BA_ "GenSigStartValue" SG_ 2147484719 CTA_PBReleaseInhibit_ind 7;
BA_ "GenSigCycleTime" SG_ 2147484719 EngOvrrideCtrlStat_FireTruckMode 100;
BA_ "GenSigCycleTimeActive" SG_ 2147484719 EngOvrrideCtrlStat_FireTruckMode 100;
BA_ "GenSigStartValue" SG_ 2147484719 EngOvrrideCtrlStat_FireTruckMode 3;
BA_ "Platform_VMCU1_Sig" SG_ 2147484719 EngOvrrideCtrlStat_FireTruckMode 1;
BA_ "GenSigCycleTime" SG_ 2147484719 DHCActualSetSpeed 100;
BA_ "GenSigCycleTimeActive" SG_ 2147484719 DHCActualSetSpeed 100;
BA_ "GenSigStartValue" SG_ 2147484719 DHCActualSetSpeed 65535;
BA_ "GenSigCycleTime" SG_ 2147484719 EngOvrrideCtrlStat_StartOvrrMode 100;
BA_ "GenSigCycleTimeActive" SG_ 2147484719 EngOvrrideCtrlStat_StartOvrrMode 100;
BA_ "GenSigStartValue" SG_ 2147484719 EngOvrrideCtrlStat_StartOvrrMode 3;
BA_ "Platform_VMCU1_Sig" SG_ 2147484719 EngOvrrideCtrlStat_StartOvrrMode 1;
BA_ "GenSigCycleTime" SG_ 2147484719 EngOvrrideCtrlStat_ProtOvrrMode 100;
BA_ "GenSigCycleTimeActive" SG_ 2147484719 EngOvrrideCtrlStat_ProtOvrrMode 100;
BA_ "GenSigStartValue" SG_ 2147484719 EngOvrrideCtrlStat_ProtOvrrMode 3;
BA_ "Platform_VMCU1_Sig" SG_ 2147484719 EngOvrrideCtrlStat_ProtOvrrMode 1;
BA_ "GenSigCycleTime" SG_ 2147484719 XRSLBTargetSpeedRequest 100;
BA_ "GenSigCycleTimeActive" SG_ 2147484719 XRSLBTargetSpeedRequest 100;
BA_ "GenSigStartValue" SG_ 2147484719 XRSLBTargetSpeedRequest 65535;
BA_ "GenSigCycleTime" SG_ 2147484716 EcoCruiseMinSpeedLev3 100;
BA_ "GenSigCycleTimeActive" SG_ 2147484716 EcoCruiseMinSpeedLev3 100;
BA_ "GenSigStartValue" SG_ 2147484716 EcoCruiseMinSpeedLev3 65535;
BA_ "Platform_VMCU1_Sig" SG_ 2147484716 EcoCruiseMinSpeedLev3 1;
BA_ "GenSigCycleTime" SG_ 2147484716 EcoCruiseMinSpeedLev0 100;
BA_ "GenSigCycleTimeActive" SG_ 2147484716 EcoCruiseMinSpeedLev0 100;
BA_ "GenSigStartValue" SG_ 2147484716 EcoCruiseMinSpeedLev0 65535;
BA_ "Platform_VMCU1_Sig" SG_ 2147484716 EcoCruiseMinSpeedLev0 1;
BA_ "GenSigCycleTime" SG_ 2147484716 EcoCruiseMinSpeedLev1 100;
BA_ "GenSigCycleTimeActive" SG_ 2147484716 EcoCruiseMinSpeedLev1 100;
BA_ "GenSigStartValue" SG_ 2147484716 EcoCruiseMinSpeedLev1 65535;
BA_ "Platform_VMCU1_Sig" SG_ 2147484716 EcoCruiseMinSpeedLev1 1;
BA_ "GenSigCycleTime" SG_ 2147484716 EcoCruiseMinSpeedLev2 100;
BA_ "GenSigCycleTimeActive" SG_ 2147484716 EcoCruiseMinSpeedLev2 100;
BA_ "GenSigStartValue" SG_ 2147484716 EcoCruiseMinSpeedLev2 65535;
BA_ "Platform_VMCU1_Sig" SG_ 2147484716 EcoCruiseMinSpeedLev2 1;
BA_ "GenSigCycleTime" SG_ 2147484713 EcoCruiseMaxSpeedLev1 100;
BA_ "GenSigCycleTimeActive" SG_ 2147484713 EcoCruiseMaxSpeedLev1 100;
BA_ "GenSigStartValue" SG_ 2147484713 EcoCruiseMaxSpeedLev1 65535;
BA_ "Platform_VMCU1_Sig" SG_ 2147484713 EcoCruiseMaxSpeedLev1 1;
BA_ "GenSigCycleTime" SG_ 2147484713 EcoCruiseMaxSpeedLev0 100;
BA_ "GenSigCycleTimeActive" SG_ 2147484713 EcoCruiseMaxSpeedLev0 100;
BA_ "GenSigStartValue" SG_ 2147484713 EcoCruiseMaxSpeedLev0 65535;
BA_ "Platform_VMCU1_Sig" SG_ 2147484713 EcoCruiseMaxSpeedLev0 1;
BA_ "GenSigCycleTime" SG_ 2147484713 EcoCruiseMaxSpeedLev2 100;
BA_ "GenSigCycleTimeActive" SG_ 2147484713 EcoCruiseMaxSpeedLev2 100;
BA_ "GenSigStartValue" SG_ 2147484713 EcoCruiseMaxSpeedLev2 65535;
BA_ "Platform_VMCU1_Sig" SG_ 2147484713 EcoCruiseMaxSpeedLev2 1;
BA_ "GenSigCycleTime" SG_ 2147484713 EcoCruiseMaxSpeedLev3 100;
BA_ "GenSigCycleTimeActive" SG_ 2147484713 EcoCruiseMaxSpeedLev3 100;
BA_ "GenSigStartValue" SG_ 2147484713 EcoCruiseMaxSpeedLev3 65535;
BA_ "Platform_VMCU1_Sig" SG_ 2147484713 EcoCruiseMaxSpeedLev3 1;
BA_ "GenSigCycleTime" SG_ 2147484710 EcoCruiseCCBSetSpeedLev2 100;
BA_ "GenSigCycleTimeActive" SG_ 2147484710 EcoCruiseCCBSetSpeedLev2 100;
BA_ "GenSigStartValue" SG_ 2147484710 EcoCruiseCCBSetSpeedLev2 65535;
BA_ "Platform_VMCU1_Sig" SG_ 2147484710 EcoCruiseCCBSetSpeedLev2 1;
BA_ "GenSigCycleTime" SG_ 2147484710 EcoCruiseCCBSetSpeedLev1 100;
BA_ "GenSigCycleTimeActive" SG_ 2147484710 EcoCruiseCCBSetSpeedLev1 100;
BA_ "GenSigStartValue" SG_ 2147484710 EcoCruiseCCBSetSpeedLev1 65535;
BA_ "Platform_VMCU1_Sig" SG_ 2147484710 EcoCruiseCCBSetSpeedLev1 1;
BA_ "GenSigCycleTime" SG_ 2147484710 EcoCruiseCCBSetSpeedLev3 100;
BA_ "GenSigCycleTimeActive" SG_ 2147484710 EcoCruiseCCBSetSpeedLev3 100;
BA_ "GenSigStartValue" SG_ 2147484710 EcoCruiseCCBSetSpeedLev3 65535;
BA_ "Platform_VMCU1_Sig" SG_ 2147484710 EcoCruiseCCBSetSpeedLev3 1;
BA_ "GenSigCycleTime" SG_ 2147484710 EcoCruiseCCBSetSpeedLev0 100;
BA_ "GenSigCycleTimeActive" SG_ 2147484710 EcoCruiseCCBSetSpeedLev0 100;
BA_ "GenSigStartValue" SG_ 2147484710 EcoCruiseCCBSetSpeedLev0 65535;
BA_ "Platform_VMCU1_Sig" SG_ 2147484710 EcoCruiseCCBSetSpeedLev0 1;
BA_ "GenSigCycleTime" SG_ 2147485052 EngineGreenAreaOutLNG_ISig_4 100;
BA_ "GenSigCycleTimeActive" SG_ 2147485052 EngineGreenAreaOutLNG_ISig_4 100;
BA_ "GenSigStartValue" SG_ 2147485052 EngineGreenAreaOutLNG_ISig_4 4294967295;
BA_ "Platform_VMCU1_Sig" SG_ 2147485052 EngineGreenAreaOutLNG_ISig_4 1;
BA_ "GenSigCycleTime" SG_ 2147485052 EngineGreenAreaLNG_ISig_4 100;
BA_ "GenSigCycleTimeActive" SG_ 2147485052 EngineGreenAreaLNG_ISig_4 100;
BA_ "GenSigStartValue" SG_ 2147485052 EngineGreenAreaLNG_ISig_4 4294967295;
BA_ "Platform_VMCU1_Sig" SG_ 2147485052 EngineGreenAreaLNG_ISig_4 1;
BA_ "GenSigCycleTime" SG_ 2147484683 BatteryTempAlert_rqst_ISig_4 100;
BA_ "GenSigCycleTimeActive" SG_ 2147484683 BatteryTempAlert_rqst_ISig_4 100;
BA_ "GenSigStartValue" SG_ 2147484683 BatteryTempAlert_rqst_ISig_4 7;
BA_ "Platform_VMCU1_Sig" SG_ 2147484683 BatteryTempAlert_rqst_ISig_4 1;
BA_ "GenSigCycleTime" SG_ 2147484683 APM_TrailerCircPressureStatus_IS 100;
BA_ "GenSigCycleTimeActive" SG_ 2147484683 APM_TrailerCircPressureStatus_IS 100;
BA_ "GenSigStartValue" SG_ 2147484683 APM_TrailerCircPressureStatus_IS 3;
BA_ "SystemSignalLongSymbol" SG_ 2147484683 APM_TrailerCircPressureStatus_IS "APM_TrailerCircPressureStatus_ISig_4";
BA_ "GenSigCycleTime" SG_ 2147484683 BatteryCapacity_ISig_4 100;
BA_ "GenSigCycleTimeActive" SG_ 2147484683 BatteryCapacity_ISig_4 100;
BA_ "GenSigStartValue" SG_ 2147484683 BatteryCapacity_ISig_4 15;
BA_ "Platform_VMCU1_Sig" SG_ 2147484683 BatteryCapacity_ISig_4 1;
BA_ "GenSigCycleTime" SG_ 2147484683 Hazard_rqst_ISig_4 100;
BA_ "GenSigCycleTimeActive" SG_ 2147484683 Hazard_rqst_ISig_4 100;
BA_ "GenSigStartValue" SG_ 2147484683 Hazard_rqst_ISig_4 3;
BA_ "SeToolAncestorID_SIGNAL" SG_ 2147484683 Hazard_rqst_ISig_4 "x0000001D04134A95";
BA_ "SeToolItemID_SIGNAL" SG_ 2147484683 Hazard_rqst_ISig_4 "x0000001D04134A95";
BA_ "SeToolName_SIGNAL" SG_ 2147484683 Hazard_rqst_ISig_4 "Hazard_rqst";
BA_ "SeToolVersion_SIGNAL" SG_ 2147484683 Hazard_rqst_ISig_4 "1";
BA_ "GenSigCycleTime" SG_ 2147484683 CollisionSituationAliveStatus 100;
BA_ "GenSigCycleTimeActive" SG_ 2147484683 CollisionSituationAliveStatus 100;
BA_ "GenSigStartValue" SG_ 2147484683 CollisionSituationAliveStatus 15;
BA_ "Platform_VMCU1_Sig" SG_ 2147484683 CollisionSituationAliveStatus 1;
BA_ "GenSigCycleTime" SG_ 2147484683 BatterySOCact_ISig_4 100;
BA_ "GenSigCycleTimeActive" SG_ 2147484683 BatterySOCact_ISig_4 100;
BA_ "GenSigStartValue" SG_ 2147484683 BatterySOCact_ISig_4 255;
BA_ "Platform_VMCU1_Sig" SG_ 2147484683 BatterySOCact_ISig_4 1;
BA_ "GenSigCycleTime" SG_ 2147484683 Trailer1TPMLostCom_ISig_4 100;
BA_ "GenSigCycleTimeActive" SG_ 2147484683 Trailer1TPMLostCom_ISig_4 100;
BA_ "GenSigStartValue" SG_ 2147484683 Trailer1TPMLostCom_ISig_4 3;
BA_ "NeedsUpdateBit" SG_ 2147484683 Trailer1TPMLostCom_ISig_4 1;
BA_ "Platform_VMCU1_Sig" SG_ 2147484683 Trailer1TPMLostCom_ISig_4 1;
BA_ "GenSigCycleTime" SG_ 2147484683 BatterySOCactCriticalAlert_ISig_ 100;
BA_ "GenSigCycleTimeActive" SG_ 2147484683 BatterySOCactCriticalAlert_ISig_ 100;
BA_ "GenSigStartValue" SG_ 2147484683 BatterySOCactCriticalAlert_ISig_ 255;
BA_ "Platform_VMCU1_Sig" SG_ 2147484683 BatterySOCactCriticalAlert_ISig_ 1;
BA_ "SystemSignalLongSymbol" SG_ 2147484683 BatterySOCactCriticalAlert_ISig_ "BatterySOCactCriticalAlert_ISig_4";
BA_ "GenSigCycleTime" SG_ 2147484683 BatteryTempAlertRawData_rqst_ISi 100;
BA_ "GenSigCycleTimeActive" SG_ 2147484683 BatteryTempAlertRawData_rqst_ISi 100;
BA_ "GenSigStartValue" SG_ 2147484683 BatteryTempAlertRawData_rqst_ISi 7;
BA_ "Platform_VMCU1_Sig" SG_ 2147484683 BatteryTempAlertRawData_rqst_ISi 1;
BA_ "SystemSignalLongSymbol" SG_ 2147484683 BatteryTempAlertRawData_rqst_ISi "BatteryTempAlertRawData_rqst_ISig_4";
BA_ "GenSigCycleTime" SG_ 2147484683 FPBRMMIStat_FPBRChangeAck_ISig_4 100;
BA_ "GenSigCycleTimeActive" SG_ 2147484683 FPBRMMIStat_FPBRChangeAck_ISig_4 100;
BA_ "GenSigStartValue" SG_ 2147484683 FPBRMMIStat_FPBRChangeAck_ISig_4 3;
BA_ "Platform_VMCU1_Sig" SG_ 2147484683 FPBRMMIStat_FPBRChangeAck_ISig_4 1;
BA_ "GenSigSendType" SG_ 2147484683 Trailer2TPMLostCom_UB_ISig_4 7;
BA_ "GenSigCycleTime" SG_ 2147484683 Trailer2TPMLostCom_UB_ISig_4 100;
BA_ "GenSigCycleTimeActive" SG_ 2147484683 Trailer2TPMLostCom_UB_ISig_4 100;
BA_ "Platform_VMCU1_Sig" SG_ 2147484683 Trailer2TPMLostCom_UB_ISig_4 1;
BA_ "GenSigCycleTime" SG_ 2147484683 LivBatteryCharging_stat_ISig_4 100;
BA_ "GenSigCycleTimeActive" SG_ 2147484683 LivBatteryCharging_stat_ISig_4 100;
BA_ "GenSigStartValue" SG_ 2147484683 LivBatteryCharging_stat_ISig_4 3;
BA_ "GenSigCycleTime" SG_ 2147484683 BatteryTemp_ISig_4 100;
BA_ "GenSigCycleTimeActive" SG_ 2147484683 BatteryTemp_ISig_4 100;
BA_ "GenSigStartValue" SG_ 2147484683 BatteryTemp_ISig_4 255;
BA_ "Platform_VMCU1_Sig" SG_ 2147484683 BatteryTemp_ISig_4 1;
BA_ "GenSigSendType" SG_ 2147484683 Trailer1TPMLostCom_UB_ISig_4 7;
BA_ "GenSigCycleTime" SG_ 2147484683 Trailer1TPMLostCom_UB_ISig_4 100;
BA_ "GenSigCycleTimeActive" SG_ 2147484683 Trailer1TPMLostCom_UB_ISig_4 100;
BA_ "Platform_VMCU1_Sig" SG_ 2147484683 Trailer1TPMLostCom_UB_ISig_4 1;
BA_ "GenSigCycleTime" SG_ 2147484683 FPBRMMIStat_FPBRStatusInd_ISig_4 100;
BA_ "GenSigCycleTimeActive" SG_ 2147484683 FPBRMMIStat_FPBRStatusInd_ISig_4 100;
BA_ "GenSigStartValue" SG_ 2147484683 FPBRMMIStat_FPBRStatusInd_ISig_4 3;
BA_ "Platform_VMCU1_Sig" SG_ 2147484683 FPBRMMIStat_FPBRStatusInd_ISig_4 1;
BA_ "GenSigCycleTime" SG_ 2147484683 Trailer2TPMLostCom_ISig_4 100;
BA_ "GenSigCycleTimeActive" SG_ 2147484683 Trailer2TPMLostCom_ISig_4 100;
BA_ "GenSigStartValue" SG_ 2147484683 Trailer2TPMLostCom_ISig_4 3;
BA_ "NeedsUpdateBit" SG_ 2147484683 Trailer2TPMLostCom_ISig_4 1;
BA_ "Platform_VMCU1_Sig" SG_ 2147484683 Trailer2TPMLostCom_ISig_4 1;
BA_ "GenSigCycleTime" SG_ 2147484683 CollisionSituationAliveRequest 100;
BA_ "GenSigCycleTimeActive" SG_ 2147484683 CollisionSituationAliveRequest 100;
BA_ "GenSigStartValue" SG_ 2147484683 CollisionSituationAliveRequest 15;
BA_ "Platform_VMCU1_Sig" SG_ 2147484683 CollisionSituationAliveRequest 1;
BA_ "GenSigCycleTime" SG_ 2147484680 TPMMateTrailerResp_ISig_4 100;
BA_ "GenSigCycleTimeActive" SG_ 2147484680 TPMMateTrailerResp_ISig_4 100;
BA_ "GenSigStartValue" SG_ 2147484680 TPMMateTrailerResp_ISig_4 7;
BA_ "NeedsUpdateBit" SG_ 2147484680 TPMMateTrailerResp_ISig_4 1;
BA_ "Platform_VMCU1_Sig" SG_ 2147484680 TPMMateTrailerResp_ISig_4 1;
BA_ "GenSigCycleTime" SG_ 2147484680 Trailer2TPMLeakageWarning_ISig_4 100;
BA_ "GenSigCycleTimeActive" SG_ 2147484680 Trailer2TPMLeakageWarning_ISig_4 100;
BA_ "GenSigStartValue" SG_ 2147484680 Trailer2TPMLeakageWarning_ISig_4 7;
BA_ "NeedsUpdateBit" SG_ 2147484680 Trailer2TPMLeakageWarning_ISig_4 1;
BA_ "Platform_VMCU1_Sig" SG_ 2147484680 Trailer2TPMLeakageWarning_ISig_4 1;
BA_ "GenSigCycleTime" SG_ 2147484680 TPMAutomaticMating_ISig_4 100;
BA_ "GenSigCycleTimeActive" SG_ 2147484680 TPMAutomaticMating_ISig_4 100;
BA_ "GenSigStartValue" SG_ 2147484680 TPMAutomaticMating_ISig_4 3;
BA_ "Platform_VMCU1_Sig" SG_ 2147484680 TPMAutomaticMating_ISig_4 1;
BA_ "GenSigSendType" SG_ 2147484680 Trailer2TPMPressureWarning_UB_IS 7;
BA_ "GenSigCycleTime" SG_ 2147484680 Trailer2TPMPressureWarning_UB_IS 100;
BA_ "GenSigCycleTimeActive" SG_ 2147484680 Trailer2TPMPressureWarning_UB_IS 100;
BA_ "Platform_VMCU1_Sig" SG_ 2147484680 Trailer2TPMPressureWarning_UB_IS 1;
BA_ "SystemSignalLongSymbol" SG_ 2147484680 Trailer2TPMPressureWarning_UB_IS "Trailer2TPMPressureWarning_UB_ISig_4";
BA_ "GenSigSendType" SG_ 2147484680 TruckTPMLeakageWarning_UB_ISig_4 7;
BA_ "GenSigCycleTime" SG_ 2147484680 TruckTPMLeakageWarning_UB_ISig_4 100;
BA_ "GenSigCycleTimeActive" SG_ 2147484680 TruckTPMLeakageWarning_UB_ISig_4 100;
BA_ "Platform_VMCU1_Sig" SG_ 2147484680 TruckTPMLeakageWarning_UB_ISig_4 1;
BA_ "GenSigCycleTime" SG_ 2147484680 Trailer2TPMMatedStatus_ISig_4 100;
BA_ "GenSigCycleTimeActive" SG_ 2147484680 Trailer2TPMMatedStatus_ISig_4 100;
BA_ "GenSigStartValue" SG_ 2147484680 Trailer2TPMMatedStatus_ISig_4 3;
BA_ "Platform_VMCU1_Sig" SG_ 2147484680 Trailer2TPMMatedStatus_ISig_4 1;
BA_ "GenSigCycleTime" SG_ 2147484680 Trailer1TPMMatedStatus_ISig_4 100;
BA_ "GenSigCycleTimeActive" SG_ 2147484680 Trailer1TPMMatedStatus_ISig_4 100;
BA_ "GenSigStartValue" SG_ 2147484680 Trailer1TPMMatedStatus_ISig_4 3;
BA_ "Platform_VMCU1_Sig" SG_ 2147484680 Trailer1TPMMatedStatus_ISig_4 1;
BA_ "GenSigSendType" SG_ 2147484680 Trailer2TPMLeakageWarning_UB_ISi 7;
BA_ "GenSigCycleTime" SG_ 2147484680 Trailer2TPMLeakageWarning_UB_ISi 100;
BA_ "GenSigCycleTimeActive" SG_ 2147484680 Trailer2TPMLeakageWarning_UB_ISi 100;
BA_ "Platform_VMCU1_Sig" SG_ 2147484680 Trailer2TPMLeakageWarning_UB_ISi 1;
BA_ "SystemSignalLongSymbol" SG_ 2147484680 Trailer2TPMLeakageWarning_UB_ISi "Trailer2TPMLeakageWarning_UB_ISig_4";
BA_ "GenSigSendType" SG_ 2147484680 Trailer1TPMLeakageWarning_UB_ISi 7;
BA_ "GenSigCycleTime" SG_ 2147484680 Trailer1TPMLeakageWarning_UB_ISi 100;
BA_ "GenSigCycleTimeActive" SG_ 2147484680 Trailer1TPMLeakageWarning_UB_ISi 100;
BA_ "Platform_VMCU1_Sig" SG_ 2147484680 Trailer1TPMLeakageWarning_UB_ISi 1;
BA_ "SystemSignalLongSymbol" SG_ 2147484680 Trailer1TPMLeakageWarning_UB_ISi "Trailer1TPMLeakageWarning_UB_ISig_4";
BA_ "GenSigCycleTime" SG_ 2147484680 TruckTPMLeakageWarning_ISig_4 100;
BA_ "GenSigCycleTimeActive" SG_ 2147484680 TruckTPMLeakageWarning_ISig_4 100;
BA_ "GenSigStartValue" SG_ 2147484680 TruckTPMLeakageWarning_ISig_4 7;
BA_ "NeedsUpdateBit" SG_ 2147484680 TruckTPMLeakageWarning_ISig_4 1;
BA_ "Platform_VMCU1_Sig" SG_ 2147484680 TruckTPMLeakageWarning_ISig_4 1;
BA_ "GenSigSendType" SG_ 2147484680 Trailer1TPMPressureWarning_UB_IS 7;
BA_ "GenSigCycleTime" SG_ 2147484680 Trailer1TPMPressureWarning_UB_IS 100;
BA_ "GenSigCycleTimeActive" SG_ 2147484680 Trailer1TPMPressureWarning_UB_IS 100;
BA_ "Platform_VMCU1_Sig" SG_ 2147484680 Trailer1TPMPressureWarning_UB_IS 1;
BA_ "SystemSignalLongSymbol" SG_ 2147484680 Trailer1TPMPressureWarning_UB_IS "Trailer1TPMPressureWarning_UB_ISig_4";
BA_ "GenSigCycleTime" SG_ 2147484680 ExtraSideMarkers_FunctStat 100;
BA_ "GenSigCycleTimeActive" SG_ 2147484680 ExtraSideMarkers_FunctStat 100;
BA_ "GenSigStartValue" SG_ 2147484680 ExtraSideMarkers_FunctStat 3;
BA_ "Platform_VMCU1_Sig" SG_ 2147484680 ExtraSideMarkers_FunctStat 1;
BA_ "GenSigSendType" SG_ 2147484680 TruckTPMPressureWarning_UB_ISig_ 7;
BA_ "GenSigCycleTime" SG_ 2147484680 TruckTPMPressureWarning_UB_ISig_ 100;
BA_ "GenSigCycleTimeActive" SG_ 2147484680 TruckTPMPressureWarning_UB_ISig_ 100;
BA_ "Platform_VMCU1_Sig" SG_ 2147484680 TruckTPMPressureWarning_UB_ISig_ 1;
BA_ "SystemSignalLongSymbol" SG_ 2147484680 TruckTPMPressureWarning_UB_ISig_ "TruckTPMPressureWarning_UB_ISig_4";
BA_ "GenSigCycleTime" SG_ 2147484680 Trailer2TPMPressureWarning_ISig_ 100;
BA_ "GenSigCycleTimeActive" SG_ 2147484680 Trailer2TPMPressureWarning_ISig_ 100;
BA_ "GenSigStartValue" SG_ 2147484680 Trailer2TPMPressureWarning_ISig_ 7;
BA_ "NeedsUpdateBit" SG_ 2147484680 Trailer2TPMPressureWarning_ISig_ 1;
BA_ "Platform_VMCU1_Sig" SG_ 2147484680 Trailer2TPMPressureWarning_ISig_ 1;
BA_ "SystemSignalLongSymbol" SG_ 2147484680 Trailer2TPMPressureWarning_ISig_ "Trailer2TPMPressureWarning_ISig_4";
BA_ "GenSigCycleTime" SG_ 2147484680 Trailer1TPMPressureWarning_ISig_ 100;
BA_ "GenSigCycleTimeActive" SG_ 2147484680 Trailer1TPMPressureWarning_ISig_ 100;
BA_ "GenSigStartValue" SG_ 2147484680 Trailer1TPMPressureWarning_ISig_ 7;
BA_ "NeedsUpdateBit" SG_ 2147484680 Trailer1TPMPressureWarning_ISig_ 1;
BA_ "Platform_VMCU1_Sig" SG_ 2147484680 Trailer1TPMPressureWarning_ISig_ 1;
BA_ "SystemSignalLongSymbol" SG_ 2147484680 Trailer1TPMPressureWarning_ISig_ "Trailer1TPMPressureWarning_ISig_4";
BA_ "GenSigCycleTime" SG_ 2147484680 Trailer1TPMLeakageWarning_ISig_4 100;
BA_ "GenSigCycleTimeActive" SG_ 2147484680 Trailer1TPMLeakageWarning_ISig_4 100;
BA_ "GenSigStartValue" SG_ 2147484680 Trailer1TPMLeakageWarning_ISig_4 7;
BA_ "NeedsUpdateBit" SG_ 2147484680 Trailer1TPMLeakageWarning_ISig_4 1;
BA_ "Platform_VMCU1_Sig" SG_ 2147484680 Trailer1TPMLeakageWarning_ISig_4 1;
BA_ "GenSigCycleTime" SG_ 2147484680 LiftAxle1RequestResponse 100;
BA_ "GenSigCycleTimeActive" SG_ 2147484680 LiftAxle1RequestResponse 100;
BA_ "GenSigStartValue" SG_ 2147484680 LiftAxle1RequestResponse 15;
BA_ "Platform_VMCU1_Sig" SG_ 2147484680 LiftAxle1RequestResponse 1;
BA_ "GenSigCycleTime" SG_ 2147484680 TruckTPMPressureWarning_ISig_4 100;
BA_ "GenSigCycleTimeActive" SG_ 2147484680 TruckTPMPressureWarning_ISig_4 100;
BA_ "GenSigStartValue" SG_ 2147484680 TruckTPMPressureWarning_ISig_4 7;
BA_ "NeedsUpdateBit" SG_ 2147484680 TruckTPMPressureWarning_ISig_4 1;
BA_ "Platform_VMCU1_Sig" SG_ 2147484680 TruckTPMPressureWarning_ISig_4 1;
BA_ "GenSigCycleTime" SG_ 2147484680 XRSLIndication 100;
BA_ "GenSigCycleTimeActive" SG_ 2147484680 XRSLIndication 100;
BA_ "GenSigStartValue" SG_ 2147484680 XRSLIndication 255;
BA_ "Platform_VMCU1_Sig" SG_ 2147484680 XRSLIndication 1;
BA_ "GenSigSendType" SG_ 2147484680 TPMMateTrailerResp_UB_ISig_4 7;
BA_ "GenSigCycleTime" SG_ 2147484680 TPMMateTrailerResp_UB_ISig_4 100;
BA_ "GenSigCycleTimeActive" SG_ 2147484680 TPMMateTrailerResp_UB_ISig_4 100;
BA_ "Platform_VMCU1_Sig" SG_ 2147484680 TPMMateTrailerResp_UB_ISig_4 1;
BA_ "GenSigCycleTime" SG_ 2147484885 Trailer2TPMFailure_ISig_4 100;
BA_ "GenSigCycleTimeActive" SG_ 2147484885 Trailer2TPMFailure_ISig_4 100;
BA_ "GenSigStartValue" SG_ 2147484885 Trailer2TPMFailure_ISig_4 3;
BA_ "Platform_VMCU1_Sig" SG_ 2147484885 Trailer2TPMFailure_ISig_4 1;
BA_ "GenSigCycleTime" SG_ 2147484885 TruckTPMTireInfo_Active_ISig_4 100;
BA_ "GenSigCycleTimeActive" SG_ 2147484885 TruckTPMTireInfo_Active_ISig_4 100;
BA_ "GenSigStartValue" SG_ 2147484885 TruckTPMTireInfo_Active_ISig_4 3;
BA_ "NeedsUpdateBit" SG_ 2147484885 TruckTPMTireInfo_Active_ISig_4 1;
BA_ "Platform_VMCU1_Sig" SG_ 2147484885 TruckTPMTireInfo_Active_ISig_4 1;
BA_ "GenSigCycleTime" SG_ 2147484885 TruckTPMFailure_ISig_4 100;
BA_ "GenSigCycleTimeActive" SG_ 2147484885 TruckTPMFailure_ISig_4 100;
BA_ "GenSigStartValue" SG_ 2147484885 TruckTPMFailure_ISig_4 3;
BA_ "Platform_VMCU1_Sig" SG_ 2147484885 TruckTPMFailure_ISig_4 1;
BA_ "GenSigCycleTime" SG_ 2147484885 TruckTPMTireInfo_TireId_ISig_4 100;
BA_ "GenSigCycleTimeActive" SG_ 2147484885 TruckTPMTireInfo_TireId_ISig_4 100;
BA_ "NeedsUpdateBit" SG_ 2147484885 TruckTPMTireInfo_TireId_ISig_4 1;
BA_ "Platform_VMCU1_Sig" SG_ 2147484885 TruckTPMTireInfo_TireId_ISig_4 1;
BA_ "GenSigCycleTime" SG_ 2147484885 TruckTPMTireInfo_Battery_ISig_4 100;
BA_ "GenSigCycleTimeActive" SG_ 2147484885 TruckTPMTireInfo_Battery_ISig_4 100;
BA_ "GenSigStartValue" SG_ 2147484885 TruckTPMTireInfo_Battery_ISig_4 7;
BA_ "NeedsUpdateBit" SG_ 2147484885 TruckTPMTireInfo_Battery_ISig_4 1;
BA_ "Platform_VMCU1_Sig" SG_ 2147484885 TruckTPMTireInfo_Battery_ISig_4 1;
BA_ "GenSigSendType" SG_ 2147484885 TruckTPMTireInfo_sg_UB_ISig_4 7;
BA_ "GenSigCycleTime" SG_ 2147484885 TruckTPMTireInfo_sg_UB_ISig_4 100;
BA_ "GenSigCycleTimeActive" SG_ 2147484885 TruckTPMTireInfo_sg_UB_ISig_4 100;
BA_ "Platform_VMCU1_Sig" SG_ 2147484885 TruckTPMTireInfo_sg_UB_ISig_4 1;
BA_ "GenSigCycleTime" SG_ 2147484885 TruckTPMTireInfo_Temperature_ISi 100;
BA_ "GenSigCycleTimeActive" SG_ 2147484885 TruckTPMTireInfo_Temperature_ISi 100;
BA_ "GenSigStartValue" SG_ 2147484885 TruckTPMTireInfo_Temperature_ISi 255;
BA_ "NeedsUpdateBit" SG_ 2147484885 TruckTPMTireInfo_Temperature_ISi 1;
BA_ "Platform_VMCU1_Sig" SG_ 2147484885 TruckTPMTireInfo_Temperature_ISi 1;
BA_ "SystemSignalLongSymbol" SG_ 2147484885 TruckTPMTireInfo_Temperature_ISi "TruckTPMTireInfo_Temperature_ISig_4";
BA_ "GenSigCycleTime" SG_ 2147484885 TruckTPMTireInfo_RefPres_ISig_4 100;
BA_ "GenSigCycleTimeActive" SG_ 2147484885 TruckTPMTireInfo_RefPres_ISig_4 100;
BA_ "GenSigStartValue" SG_ 2147484885 TruckTPMTireInfo_RefPres_ISig_4 255;
BA_ "NeedsUpdateBit" SG_ 2147484885 TruckTPMTireInfo_RefPres_ISig_4 1;
BA_ "Platform_VMCU1_Sig" SG_ 2147484885 TruckTPMTireInfo_RefPres_ISig_4 1;
BA_ "GenSigCycleTime" SG_ 2147484885 TPMTrailerPositionStat_ISig_4 100;
BA_ "GenSigCycleTimeActive" SG_ 2147484885 TPMTrailerPositionStat_ISig_4 100;
BA_ "GenSigStartValue" SG_ 2147484885 TPMTrailerPositionStat_ISig_4 3;
BA_ "Platform_VMCU1_Sig" SG_ 2147484885 TPMTrailerPositionStat_ISig_4 1;
BA_ "GenSigCycleTime" SG_ 2147484885 TruckTPMTireInfo_Pressure_ISig_4 100;
BA_ "GenSigCycleTimeActive" SG_ 2147484885 TruckTPMTireInfo_Pressure_ISig_4 100;
BA_ "GenSigStartValue" SG_ 2147484885 TruckTPMTireInfo_Pressure_ISig_4 255;
BA_ "NeedsUpdateBit" SG_ 2147484885 TruckTPMTireInfo_Pressure_ISig_4 1;
BA_ "Platform_VMCU1_Sig" SG_ 2147484885 TruckTPMTireInfo_Pressure_ISig_4 1;
BA_ "GenSigCycleTime" SG_ 2147484885 Trailer1TPMFailure_ISig_4 100;
BA_ "GenSigCycleTimeActive" SG_ 2147484885 Trailer1TPMFailure_ISig_4 100;
BA_ "GenSigStartValue" SG_ 2147484885 Trailer1TPMFailure_ISig_4 3;
BA_ "Platform_VMCU1_Sig" SG_ 2147484885 Trailer1TPMFailure_ISig_4 1;
BA_ "GenSigCycleTime" SG_ 2147484885 TruckTPMTireInfo_PresWarn_ISig_4 100;
BA_ "GenSigCycleTimeActive" SG_ 2147484885 TruckTPMTireInfo_PresWarn_ISig_4 100;
BA_ "GenSigStartValue" SG_ 2147484885 TruckTPMTireInfo_PresWarn_ISig_4 7;
BA_ "NeedsUpdateBit" SG_ 2147484885 TruckTPMTireInfo_PresWarn_ISig_4 1;
BA_ "Platform_VMCU1_Sig" SG_ 2147484885 TruckTPMTireInfo_PresWarn_ISig_4 1;
BA_ "GenSigCycleTime" SG_ 2147484885 TruckTPMTireInfo_LeakageWarn_ISi 100;
BA_ "GenSigCycleTimeActive" SG_ 2147484885 TruckTPMTireInfo_LeakageWarn_ISi 100;
BA_ "GenSigStartValue" SG_ 2147484885 TruckTPMTireInfo_LeakageWarn_ISi 7;
BA_ "NeedsUpdateBit" SG_ 2147484885 TruckTPMTireInfo_LeakageWarn_ISi 1;
BA_ "Platform_VMCU1_Sig" SG_ 2147484885 TruckTPMTireInfo_LeakageWarn_ISi 1;
BA_ "SystemSignalLongSymbol" SG_ 2147484885 TruckTPMTireInfo_LeakageWarn_ISi "TruckTPMTireInfo_LeakageWarn_ISig_4";
BA_ "GenSigCycleTime" SG_ 2147484882 Trailer2TPMTireInfo_LeakageWarn_ 100;
BA_ "GenSigCycleTimeActive" SG_ 2147484882 Trailer2TPMTireInfo_LeakageWarn_ 100;
BA_ "GenSigStartValue" SG_ 2147484882 Trailer2TPMTireInfo_LeakageWarn_ 7;
BA_ "NeedsUpdateBit" SG_ 2147484882 Trailer2TPMTireInfo_LeakageWarn_ 1;
BA_ "Platform_VMCU1_Sig" SG_ 2147484882 Trailer2TPMTireInfo_LeakageWarn_ 1;
BA_ "SystemSignalLongSymbol" SG_ 2147484882 Trailer2TPMTireInfo_LeakageWarn_ "Trailer2TPMTireInfo_LeakageWarn_ISig_4";
BA_ "GenSigCycleTime" SG_ 2147484882 Trailer2TPMTireInfo_RefPres_ISig 100;
BA_ "GenSigCycleTimeActive" SG_ 2147484882 Trailer2TPMTireInfo_RefPres_ISig 100;
BA_ "GenSigStartValue" SG_ 2147484882 Trailer2TPMTireInfo_RefPres_ISig 255;
BA_ "NeedsUpdateBit" SG_ 2147484882 Trailer2TPMTireInfo_RefPres_ISig 1;
BA_ "Platform_VMCU1_Sig" SG_ 2147484882 Trailer2TPMTireInfo_RefPres_ISig 1;
BA_ "SystemSignalLongSymbol" SG_ 2147484882 Trailer2TPMTireInfo_RefPres_ISig "Trailer2TPMTireInfo_RefPres_ISig_4";
BA_ "GenSigCycleTime" SG_ 2147484882 Trailer2TPMTireInfo_PresWarn_ISi 100;
BA_ "GenSigCycleTimeActive" SG_ 2147484882 Trailer2TPMTireInfo_PresWarn_ISi 100;
BA_ "GenSigStartValue" SG_ 2147484882 Trailer2TPMTireInfo_PresWarn_ISi 7;
BA_ "NeedsUpdateBit" SG_ 2147484882 Trailer2TPMTireInfo_PresWarn_ISi 1;
BA_ "Platform_VMCU1_Sig" SG_ 2147484882 Trailer2TPMTireInfo_PresWarn_ISi 1;
BA_ "SystemSignalLongSymbol" SG_ 2147484882 Trailer2TPMTireInfo_PresWarn_ISi "Trailer2TPMTireInfo_PresWarn_ISig_4";
BA_ "GenSigCycleTime" SG_ 2147484882 Trailer2TPMTireInfo_Pressure_ISi 100;
BA_ "GenSigCycleTimeActive" SG_ 2147484882 Trailer2TPMTireInfo_Pressure_ISi 100;
BA_ "GenSigStartValue" SG_ 2147484882 Trailer2TPMTireInfo_Pressure_ISi 255;
BA_ "NeedsUpdateBit" SG_ 2147484882 Trailer2TPMTireInfo_Pressure_ISi 1;
BA_ "Platform_VMCU1_Sig" SG_ 2147484882 Trailer2TPMTireInfo_Pressure_ISi 1;
BA_ "SystemSignalLongSymbol" SG_ 2147484882 Trailer2TPMTireInfo_Pressure_ISi "Trailer2TPMTireInfo_Pressure_ISig_4";
BA_ "GenSigCycleTime" SG_ 2147484882 Trailer2TPMTireInfo_Temperature_ 100;
BA_ "GenSigCycleTimeActive" SG_ 2147484882 Trailer2TPMTireInfo_Temperature_ 100;
BA_ "GenSigStartValue" SG_ 2147484882 Trailer2TPMTireInfo_Temperature_ 255;
BA_ "NeedsUpdateBit" SG_ 2147484882 Trailer2TPMTireInfo_Temperature_ 1;
BA_ "Platform_VMCU1_Sig" SG_ 2147484882 Trailer2TPMTireInfo_Temperature_ 1;
BA_ "SystemSignalLongSymbol" SG_ 2147484882 Trailer2TPMTireInfo_Temperature_ "Trailer2TPMTireInfo_Temperature_ISig_4";
BA_ "GenSigSendType" SG_ 2147484882 Trailer2TPMTireInfo_sg_UB_ISig_4 7;
BA_ "GenSigCycleTime" SG_ 2147484882 Trailer2TPMTireInfo_sg_UB_ISig_4 100;
BA_ "GenSigCycleTimeActive" SG_ 2147484882 Trailer2TPMTireInfo_sg_UB_ISig_4 100;
BA_ "Platform_VMCU1_Sig" SG_ 2147484882 Trailer2TPMTireInfo_sg_UB_ISig_4 1;
BA_ "GenSigCycleTime" SG_ 2147484882 Trailer2TPMTireInfo_TireId_ISig_ 100;
BA_ "GenSigCycleTimeActive" SG_ 2147484882 Trailer2TPMTireInfo_TireId_ISig_ 100;
BA_ "NeedsUpdateBit" SG_ 2147484882 Trailer2TPMTireInfo_TireId_ISig_ 1;
BA_ "Platform_VMCU1_Sig" SG_ 2147484882 Trailer2TPMTireInfo_TireId_ISig_ 1;
BA_ "SystemSignalLongSymbol" SG_ 2147484882 Trailer2TPMTireInfo_TireId_ISig_ "Trailer2TPMTireInfo_TireId_ISig_4";
BA_ "GenSigCycleTime" SG_ 2147484882 Trailer2TPMTireInfo_Battery_ISig 100;
BA_ "GenSigCycleTimeActive" SG_ 2147484882 Trailer2TPMTireInfo_Battery_ISig 100;
BA_ "GenSigStartValue" SG_ 2147484882 Trailer2TPMTireInfo_Battery_ISig 7;
BA_ "NeedsUpdateBit" SG_ 2147484882 Trailer2TPMTireInfo_Battery_ISig 1;
BA_ "Platform_VMCU1_Sig" SG_ 2147484882 Trailer2TPMTireInfo_Battery_ISig 1;
BA_ "SystemSignalLongSymbol" SG_ 2147484882 Trailer2TPMTireInfo_Battery_ISig "Trailer2TPMTireInfo_Battery_ISig_4";
BA_ "GenSigCycleTime" SG_ 2147484882 Trailer2TPMTireInfo_Active_ISig_ 100;
BA_ "GenSigCycleTimeActive" SG_ 2147484882 Trailer2TPMTireInfo_Active_ISig_ 100;
BA_ "GenSigStartValue" SG_ 2147484882 Trailer2TPMTireInfo_Active_ISig_ 3;
BA_ "NeedsUpdateBit" SG_ 2147484882 Trailer2TPMTireInfo_Active_ISig_ 1;
BA_ "Platform_VMCU1_Sig" SG_ 2147484882 Trailer2TPMTireInfo_Active_ISig_ 1;
BA_ "SystemSignalLongSymbol" SG_ 2147484882 Trailer2TPMTireInfo_Active_ISig_ "Trailer2TPMTireInfo_Active_ISig_4";
BA_ "GenSigCycleTime" SG_ 2147484879 Trailer1TPMTireInfo_Battery_ISig 100;
BA_ "GenSigCycleTimeActive" SG_ 2147484879 Trailer1TPMTireInfo_Battery_ISig 100;
BA_ "GenSigStartValue" SG_ 2147484879 Trailer1TPMTireInfo_Battery_ISig 7;
BA_ "NeedsUpdateBit" SG_ 2147484879 Trailer1TPMTireInfo_Battery_ISig 1;
BA_ "Platform_VMCU1_Sig" SG_ 2147484879 Trailer1TPMTireInfo_Battery_ISig 1;
BA_ "SystemSignalLongSymbol" SG_ 2147484879 Trailer1TPMTireInfo_Battery_ISig "Trailer1TPMTireInfo_Battery_ISig_4";
BA_ "GenSigSendType" SG_ 2147484879 Trailer1TPMTireInfo_sg_UB_ISig_4 7;
BA_ "GenSigCycleTime" SG_ 2147484879 Trailer1TPMTireInfo_sg_UB_ISig_4 100;
BA_ "GenSigCycleTimeActive" SG_ 2147484879 Trailer1TPMTireInfo_sg_UB_ISig_4 100;
BA_ "Platform_VMCU1_Sig" SG_ 2147484879 Trailer1TPMTireInfo_sg_UB_ISig_4 1;
BA_ "GenSigCycleTime" SG_ 2147484879 Trailer1TPMTireInfo_Pressure_ISi 100;
BA_ "GenSigCycleTimeActive" SG_ 2147484879 Trailer1TPMTireInfo_Pressure_ISi 100;
BA_ "GenSigStartValue" SG_ 2147484879 Trailer1TPMTireInfo_Pressure_ISi 255;
BA_ "NeedsUpdateBit" SG_ 2147484879 Trailer1TPMTireInfo_Pressure_ISi 1;
BA_ "Platform_VMCU1_Sig" SG_ 2147484879 Trailer1TPMTireInfo_Pressure_ISi 1;
BA_ "SystemSignalLongSymbol" SG_ 2147484879 Trailer1TPMTireInfo_Pressure_ISi "Trailer1TPMTireInfo_Pressure_ISig_4";
BA_ "GenSigCycleTime" SG_ 2147484879 Trailer1TPMTireInfo_PresWarn_ISi 100;
BA_ "GenSigCycleTimeActive" SG_ 2147484879 Trailer1TPMTireInfo_PresWarn_ISi 100;
BA_ "GenSigStartValue" SG_ 2147484879 Trailer1TPMTireInfo_PresWarn_ISi 7;
BA_ "NeedsUpdateBit" SG_ 2147484879 Trailer1TPMTireInfo_PresWarn_ISi 1;
BA_ "Platform_VMCU1_Sig" SG_ 2147484879 Trailer1TPMTireInfo_PresWarn_ISi 1;
BA_ "SystemSignalLongSymbol" SG_ 2147484879 Trailer1TPMTireInfo_PresWarn_ISi "Trailer1TPMTireInfo_PresWarn_ISig_4";
BA_ "GenSigCycleTime" SG_ 2147484879 Trailer1TPMTireInfo_LeakageWarn_ 100;
BA_ "GenSigCycleTimeActive" SG_ 2147484879 Trailer1TPMTireInfo_LeakageWarn_ 100;
BA_ "GenSigStartValue" SG_ 2147484879 Trailer1TPMTireInfo_LeakageWarn_ 7;
BA_ "NeedsUpdateBit" SG_ 2147484879 Trailer1TPMTireInfo_LeakageWarn_ 1;
BA_ "Platform_VMCU1_Sig" SG_ 2147484879 Trailer1TPMTireInfo_LeakageWarn_ 1;
BA_ "SystemSignalLongSymbol" SG_ 2147484879 Trailer1TPMTireInfo_LeakageWarn_ "Trailer1TPMTireInfo_LeakageWarn_ISig_4";
BA_ "GenSigSendType" SG_ 2147484879 TPMPosOfWMResp_sg_UB_ISig_4 7;
BA_ "GenSigCycleTime" SG_ 2147484879 TPMPosOfWMResp_sg_UB_ISig_4 100;
BA_ "GenSigCycleTimeActive" SG_ 2147484879 TPMPosOfWMResp_sg_UB_ISig_4 100;
BA_ "Platform_VMCU1_Sig" SG_ 2147484879 TPMPosOfWMResp_sg_UB_ISig_4 1;
BA_ "GenSigCycleTime" SG_ 2147484879 TPMPosOfWMResp_VehiclePos_ISig_4 100;
BA_ "GenSigCycleTimeActive" SG_ 2147484879 TPMPosOfWMResp_VehiclePos_ISig_4 100;
BA_ "GenSigStartValue" SG_ 2147484879 TPMPosOfWMResp_VehiclePos_ISig_4 7;
BA_ "NeedsUpdateBit" SG_ 2147484879 TPMPosOfWMResp_VehiclePos_ISig_4 1;
BA_ "Platform_VMCU1_Sig" SG_ 2147484879 TPMPosOfWMResp_VehiclePos_ISig_4 1;
BA_ "GenSigCycleTime" SG_ 2147484879 Trailer1TPMTireInfo_TireId_ISig_ 100;
BA_ "GenSigCycleTimeActive" SG_ 2147484879 Trailer1TPMTireInfo_TireId_ISig_ 100;
BA_ "NeedsUpdateBit" SG_ 2147484879 Trailer1TPMTireInfo_TireId_ISig_ 1;
BA_ "Platform_VMCU1_Sig" SG_ 2147484879 Trailer1TPMTireInfo_TireId_ISig_ 1;
BA_ "SystemSignalLongSymbol" SG_ 2147484879 Trailer1TPMTireInfo_TireId_ISig_ "Trailer1TPMTireInfo_TireId_ISig_4";
BA_ "GenSigCycleTime" SG_ 2147484879 Trailer1TPMTireInfo_RefPres_ISig 100;
BA_ "GenSigCycleTimeActive" SG_ 2147484879 Trailer1TPMTireInfo_RefPres_ISig 100;
BA_ "GenSigStartValue" SG_ 2147484879 Trailer1TPMTireInfo_RefPres_ISig 255;
BA_ "NeedsUpdateBit" SG_ 2147484879 Trailer1TPMTireInfo_RefPres_ISig 1;
BA_ "Platform_VMCU1_Sig" SG_ 2147484879 Trailer1TPMTireInfo_RefPres_ISig 1;
BA_ "SystemSignalLongSymbol" SG_ 2147484879 Trailer1TPMTireInfo_RefPres_ISig "Trailer1TPMTireInfo_RefPres_ISig_4";
BA_ "GenSigCycleTime" SG_ 2147484879 Trailer1TPMTireInfo_Temperature_ 100;
BA_ "GenSigCycleTimeActive" SG_ 2147484879 Trailer1TPMTireInfo_Temperature_ 100;
BA_ "GenSigStartValue" SG_ 2147484879 Trailer1TPMTireInfo_Temperature_ 255;
BA_ "NeedsUpdateBit" SG_ 2147484879 Trailer1TPMTireInfo_Temperature_ 1;
BA_ "Platform_VMCU1_Sig" SG_ 2147484879 Trailer1TPMTireInfo_Temperature_ 1;
BA_ "SystemSignalLongSymbol" SG_ 2147484879 Trailer1TPMTireInfo_Temperature_ "Trailer1TPMTireInfo_Temperature_ISig_4";
BA_ "GenSigCycleTime" SG_ 2147484879 Trailer1TPMTireInfo_Active_ISig_ 100;
BA_ "GenSigCycleTimeActive" SG_ 2147484879 Trailer1TPMTireInfo_Active_ISig_ 100;
BA_ "GenSigStartValue" SG_ 2147484879 Trailer1TPMTireInfo_Active_ISig_ 3;
BA_ "NeedsUpdateBit" SG_ 2147484879 Trailer1TPMTireInfo_Active_ISig_ 1;
BA_ "Platform_VMCU1_Sig" SG_ 2147484879 Trailer1TPMTireInfo_Active_ISig_ 1;
BA_ "SystemSignalLongSymbol" SG_ 2147484879 Trailer1TPMTireInfo_Active_ISig_ "Trailer1TPMTireInfo_Active_ISig_4";
BA_ "GenSigCycleTime" SG_ 2147484879 TPMPosOfWMResp_Status_ISig_4 100;
BA_ "GenSigCycleTimeActive" SG_ 2147484879 TPMPosOfWMResp_Status_ISig_4 100;
BA_ "GenSigStartValue" SG_ 2147484879 TPMPosOfWMResp_Status_ISig_4 7;
BA_ "NeedsUpdateBit" SG_ 2147484879 TPMPosOfWMResp_Status_ISig_4 1;
BA_ "Platform_VMCU1_Sig" SG_ 2147484879 TPMPosOfWMResp_Status_ISig_4 1;
BA_ "GenSigCycleTime" SG_ 2147484879 TPMPosOfWMResp_TireId_ISig_4 100;
BA_ "GenSigCycleTimeActive" SG_ 2147484879 TPMPosOfWMResp_TireId_ISig_4 100;
BA_ "NeedsUpdateBit" SG_ 2147484879 TPMPosOfWMResp_TireId_ISig_4 1;
BA_ "Platform_VMCU1_Sig" SG_ 2147484879 TPMPosOfWMResp_TireId_ISig_4 1;
BA_ "GenSigCycleTime" SG_ 2147485051 TruckTPMThresCfg_OverPres_ISig_4 100;
BA_ "GenSigCycleTimeActive" SG_ 2147485051 TruckTPMThresCfg_OverPres_ISig_4 100;
BA_ "GenSigStartValue" SG_ 2147485051 TruckTPMThresCfg_OverPres_ISig_4 255;
BA_ "NeedsUpdateBit" SG_ 2147485051 TruckTPMThresCfg_OverPres_ISig_4 1;
BA_ "Platform_VMCU1_Sig" SG_ 2147485051 TruckTPMThresCfg_OverPres_ISig_4 1;
BA_ "GenSigCycleTime" SG_ 2147485051 TruckTPMAxlTireCfg_Axle2_ISig_4 100;
BA_ "GenSigCycleTimeActive" SG_ 2147485051 TruckTPMAxlTireCfg_Axle2_ISig_4 100;
BA_ "GenSigStartValue" SG_ 2147485051 TruckTPMAxlTireCfg_Axle2_ISig_4 7;
BA_ "Platform_VMCU1_Sig" SG_ 2147485051 TruckTPMAxlTireCfg_Axle2_ISig_4 1;
BA_ "GenSigCycleTime" SG_ 2147485051 TruckTPMAxlTireCfg_Axle1_ISig_4 100;
BA_ "GenSigCycleTimeActive" SG_ 2147485051 TruckTPMAxlTireCfg_Axle1_ISig_4 100;
BA_ "GenSigStartValue" SG_ 2147485051 TruckTPMAxlTireCfg_Axle1_ISig_4 7;
BA_ "Platform_VMCU1_Sig" SG_ 2147485051 TruckTPMAxlTireCfg_Axle1_ISig_4 1;
BA_ "GenSigCycleTime" SG_ 2147485051 TruckTPMAxlTireCfg_Axle5_ISig_4 100;
BA_ "GenSigCycleTimeActive" SG_ 2147485051 TruckTPMAxlTireCfg_Axle5_ISig_4 100;
BA_ "GenSigStartValue" SG_ 2147485051 TruckTPMAxlTireCfg_Axle5_ISig_4 7;
BA_ "Platform_VMCU1_Sig" SG_ 2147485051 TruckTPMAxlTireCfg_Axle5_ISig_4 1;
BA_ "GenSigSendType" SG_ 2147485051 TruckTPMThresCfg_sg_UB_ISig_4 7;
BA_ "GenSigCycleTime" SG_ 2147485051 TruckTPMThresCfg_sg_UB_ISig_4 100;
BA_ "GenSigCycleTimeActive" SG_ 2147485051 TruckTPMThresCfg_sg_UB_ISig_4 100;
BA_ "Platform_VMCU1_Sig" SG_ 2147485051 TruckTPMThresCfg_sg_UB_ISig_4 1;
BA_ "GenSigCycleTime" SG_ 2147485051 TruckTPMAxlTireCfg_Axle4_ISig_4 100;
BA_ "GenSigCycleTimeActive" SG_ 2147485051 TruckTPMAxlTireCfg_Axle4_ISig_4 100;
BA_ "GenSigStartValue" SG_ 2147485051 TruckTPMAxlTireCfg_Axle4_ISig_4 7;
BA_ "Platform_VMCU1_Sig" SG_ 2147485051 TruckTPMAxlTireCfg_Axle4_ISig_4 1;
BA_ "GenSigCycleTime" SG_ 2147485051 TruckTPMThresCfg_ExtUnderPres_IS 100;
BA_ "GenSigCycleTimeActive" SG_ 2147485051 TruckTPMThresCfg_ExtUnderPres_IS 100;
BA_ "GenSigStartValue" SG_ 2147485051 TruckTPMThresCfg_ExtUnderPres_IS 255;
BA_ "NeedsUpdateBit" SG_ 2147485051 TruckTPMThresCfg_ExtUnderPres_IS 1;
BA_ "Platform_VMCU1_Sig" SG_ 2147485051 TruckTPMThresCfg_ExtUnderPres_IS 1;
BA_ "SystemSignalLongSymbol" SG_ 2147485051 TruckTPMThresCfg_ExtUnderPres_IS "TruckTPMThresCfg_ExtUnderPres_ISig_4";
BA_ "GenSigCycleTime" SG_ 2147485051 TruckTPMThresCfg_AxleNr_ISig_4 100;
BA_ "GenSigCycleTimeActive" SG_ 2147485051 TruckTPMThresCfg_AxleNr_ISig_4 100;
BA_ "GenSigStartValue" SG_ 2147485051 TruckTPMThresCfg_AxleNr_ISig_4 7;
BA_ "NeedsUpdateBit" SG_ 2147485051 TruckTPMThresCfg_AxleNr_ISig_4 1;
BA_ "Platform_VMCU1_Sig" SG_ 2147485051 TruckTPMThresCfg_AxleNr_ISig_4 1;
BA_ "GenSigCycleTime" SG_ 2147485051 TruckTPMThresCfg_UnderPres_ISig_ 100;
BA_ "GenSigCycleTimeActive" SG_ 2147485051 TruckTPMThresCfg_UnderPres_ISig_ 100;
BA_ "GenSigStartValue" SG_ 2147485051 TruckTPMThresCfg_UnderPres_ISig_ 255;
BA_ "NeedsUpdateBit" SG_ 2147485051 TruckTPMThresCfg_UnderPres_ISig_ 1;
BA_ "Platform_VMCU1_Sig" SG_ 2147485051 TruckTPMThresCfg_UnderPres_ISig_ 1;
BA_ "SystemSignalLongSymbol" SG_ 2147485051 TruckTPMThresCfg_UnderPres_ISig_ "TruckTPMThresCfg_UnderPres_ISig_4";
BA_ "GenSigCycleTime" SG_ 2147485051 TruckTPMThresCfg_ExtOverPres_ISi 100;
BA_ "GenSigCycleTimeActive" SG_ 2147485051 TruckTPMThresCfg_ExtOverPres_ISi 100;
BA_ "GenSigStartValue" SG_ 2147485051 TruckTPMThresCfg_ExtOverPres_ISi 255;
BA_ "NeedsUpdateBit" SG_ 2147485051 TruckTPMThresCfg_ExtOverPres_ISi 1;
BA_ "Platform_VMCU1_Sig" SG_ 2147485051 TruckTPMThresCfg_ExtOverPres_ISi 1;
BA_ "SystemSignalLongSymbol" SG_ 2147485051 TruckTPMThresCfg_ExtOverPres_ISi "TruckTPMThresCfg_ExtOverPres_ISig_4";
BA_ "GenSigCycleTime" SG_ 2147485051 TruckTPMAxlTireCfg_Axle3_ISig_4 100;
BA_ "GenSigCycleTimeActive" SG_ 2147485051 TruckTPMAxlTireCfg_Axle3_ISig_4 100;
BA_ "GenSigStartValue" SG_ 2147485051 TruckTPMAxlTireCfg_Axle3_ISig_4 7;
BA_ "Platform_VMCU1_Sig" SG_ 2147485051 TruckTPMAxlTireCfg_Axle3_ISig_4 1;
BA_ "GenSigCycleTime" SG_ 2147485050 Trailer2TPMType_ISig_4 100;
BA_ "GenSigCycleTimeActive" SG_ 2147485050 Trailer2TPMType_ISig_4 100;
BA_ "GenSigStartValue" SG_ 2147485050 Trailer2TPMType_ISig_4 3;
BA_ "NeedsUpdateBit" SG_ 2147485050 Trailer2TPMType_ISig_4 1;
BA_ "Platform_VMCU1_Sig" SG_ 2147485050 Trailer2TPMType_ISig_4 1;
BA_ "GenSigCycleTime" SG_ 2147485050 Trailer2TPMAxlTireCfg_Axle1_ISig 100;
BA_ "GenSigCycleTimeActive" SG_ 2147485050 Trailer2TPMAxlTireCfg_Axle1_ISig 100;
BA_ "GenSigStartValue" SG_ 2147485050 Trailer2TPMAxlTireCfg_Axle1_ISig 7;
BA_ "Platform_VMCU1_Sig" SG_ 2147485050 Trailer2TPMAxlTireCfg_Axle1_ISig 1;
BA_ "SystemSignalLongSymbol" SG_ 2147485050 Trailer2TPMAxlTireCfg_Axle1_ISig "Trailer2TPMAxlTireCfg_Axle1_ISig_4";
BA_ "GenSigCycleTime" SG_ 2147485050 Trailer2TPMThresCfg_OverPres_ISi 100;
BA_ "GenSigCycleTimeActive" SG_ 2147485050 Trailer2TPMThresCfg_OverPres_ISi 100;
BA_ "GenSigStartValue" SG_ 2147485050 Trailer2TPMThresCfg_OverPres_ISi 255;
BA_ "NeedsUpdateBit" SG_ 2147485050 Trailer2TPMThresCfg_OverPres_ISi 1;
BA_ "Platform_VMCU1_Sig" SG_ 2147485050 Trailer2TPMThresCfg_OverPres_ISi 1;
BA_ "SystemSignalLongSymbol" SG_ 2147485050 Trailer2TPMThresCfg_OverPres_ISi "Trailer2TPMThresCfg_OverPres_ISig_4";
BA_ "GenSigCycleTime" SG_ 2147485050 Trailer2TPMAxlTireCfg_Axle3_ISig 100;
BA_ "GenSigCycleTimeActive" SG_ 2147485050 Trailer2TPMAxlTireCfg_Axle3_ISig 100;
BA_ "GenSigStartValue" SG_ 2147485050 Trailer2TPMAxlTireCfg_Axle3_ISig 7;
BA_ "Platform_VMCU1_Sig" SG_ 2147485050 Trailer2TPMAxlTireCfg_Axle3_ISig 1;
BA_ "SystemSignalLongSymbol" SG_ 2147485050 Trailer2TPMAxlTireCfg_Axle3_ISig "Trailer2TPMAxlTireCfg_Axle3_ISig_4";
BA_ "GenSigCycleTime" SG_ 2147485050 Trailer2TPMAxlTireCfg_Axle2_ISig 100;
BA_ "GenSigCycleTimeActive" SG_ 2147485050 Trailer2TPMAxlTireCfg_Axle2_ISig 100;
BA_ "GenSigStartValue" SG_ 2147485050 Trailer2TPMAxlTireCfg_Axle2_ISig 7;
BA_ "Platform_VMCU1_Sig" SG_ 2147485050 Trailer2TPMAxlTireCfg_Axle2_ISig 1;
BA_ "SystemSignalLongSymbol" SG_ 2147485050 Trailer2TPMAxlTireCfg_Axle2_ISig "Trailer2TPMAxlTireCfg_Axle2_ISig_4";
BA_ "GenSigCycleTime" SG_ 2147485050 Trailer2TPMAxlTireCfg_Axle5_ISig 100;
BA_ "GenSigCycleTimeActive" SG_ 2147485050 Trailer2TPMAxlTireCfg_Axle5_ISig 100;
BA_ "GenSigStartValue" SG_ 2147485050 Trailer2TPMAxlTireCfg_Axle5_ISig 7;
BA_ "Platform_VMCU1_Sig" SG_ 2147485050 Trailer2TPMAxlTireCfg_Axle5_ISig 1;
BA_ "SystemSignalLongSymbol" SG_ 2147485050 Trailer2TPMAxlTireCfg_Axle5_ISig "Trailer2TPMAxlTireCfg_Axle5_ISig_4";
BA_ "GenSigCycleTime" SG_ 2147485050 Trailer2TPMAxlTireCfg_Axle4_ISig 100;
BA_ "GenSigCycleTimeActive" SG_ 2147485050 Trailer2TPMAxlTireCfg_Axle4_ISig 100;
BA_ "GenSigStartValue" SG_ 2147485050 Trailer2TPMAxlTireCfg_Axle4_ISig 7;
BA_ "Platform_VMCU1_Sig" SG_ 2147485050 Trailer2TPMAxlTireCfg_Axle4_ISig 1;
BA_ "SystemSignalLongSymbol" SG_ 2147485050 Trailer2TPMAxlTireCfg_Axle4_ISig "Trailer2TPMAxlTireCfg_Axle4_ISig_4";
BA_ "GenSigSendType" SG_ 2147485050 Trailer2TPMThresCfg_sg_UB_ISig_4 7;
BA_ "GenSigCycleTime" SG_ 2147485050 Trailer2TPMThresCfg_sg_UB_ISig_4 100;
BA_ "GenSigCycleTimeActive" SG_ 2147485050 Trailer2TPMThresCfg_sg_UB_ISig_4 100;
BA_ "Platform_VMCU1_Sig" SG_ 2147485050 Trailer2TPMThresCfg_sg_UB_ISig_4 1;
BA_ "GenSigCycleTime" SG_ 2147485050 Trailer2TPMThresCfg_AxleNr_ISig_ 100;
BA_ "GenSigCycleTimeActive" SG_ 2147485050 Trailer2TPMThresCfg_AxleNr_ISig_ 100;
BA_ "GenSigStartValue" SG_ 2147485050 Trailer2TPMThresCfg_AxleNr_ISig_ 7;
BA_ "NeedsUpdateBit" SG_ 2147485050 Trailer2TPMThresCfg_AxleNr_ISig_ 1;
BA_ "Platform_VMCU1_Sig" SG_ 2147485050 Trailer2TPMThresCfg_AxleNr_ISig_ 1;
BA_ "SystemSignalLongSymbol" SG_ 2147485050 Trailer2TPMThresCfg_AxleNr_ISig_ "Trailer2TPMThresCfg_AxleNr_ISig_4";
BA_ "GenSigCycleTime" SG_ 2147485050 Trailer2TPMThresCfg_ExtOverPres_ 100;
BA_ "GenSigCycleTimeActive" SG_ 2147485050 Trailer2TPMThresCfg_ExtOverPres_ 100;
BA_ "GenSigStartValue" SG_ 2147485050 Trailer2TPMThresCfg_ExtOverPres_ 255;
BA_ "NeedsUpdateBit" SG_ 2147485050 Trailer2TPMThresCfg_ExtOverPres_ 1;
BA_ "Platform_VMCU1_Sig" SG_ 2147485050 Trailer2TPMThresCfg_ExtOverPres_ 1;
BA_ "SystemSignalLongSymbol" SG_ 2147485050 Trailer2TPMThresCfg_ExtOverPres_ "Trailer2TPMThresCfg_ExtOverPres_ISig_4";
BA_ "GenSigCycleTime" SG_ 2147485050 Trailer2TPMThresCfg_UnderPres_IS 100;
BA_ "GenSigCycleTimeActive" SG_ 2147485050 Trailer2TPMThresCfg_UnderPres_IS 100;
BA_ "GenSigStartValue" SG_ 2147485050 Trailer2TPMThresCfg_UnderPres_IS 255;
BA_ "NeedsUpdateBit" SG_ 2147485050 Trailer2TPMThresCfg_UnderPres_IS 1;
BA_ "Platform_VMCU1_Sig" SG_ 2147485050 Trailer2TPMThresCfg_UnderPres_IS 1;
BA_ "SystemSignalLongSymbol" SG_ 2147485050 Trailer2TPMThresCfg_UnderPres_IS "Trailer2TPMThresCfg_UnderPres_ISig_4";
BA_ "GenSigCycleTime" SG_ 2147485050 Trailer2TPMThresCfg_ExtUnderPres 100;
BA_ "GenSigCycleTimeActive" SG_ 2147485050 Trailer2TPMThresCfg_ExtUnderPres 100;
BA_ "GenSigStartValue" SG_ 2147485050 Trailer2TPMThresCfg_ExtUnderPres 255;
BA_ "NeedsUpdateBit" SG_ 2147485050 Trailer2TPMThresCfg_ExtUnderPres 1;
BA_ "Platform_VMCU1_Sig" SG_ 2147485050 Trailer2TPMThresCfg_ExtUnderPres 1;
BA_ "SystemSignalLongSymbol" SG_ 2147485050 Trailer2TPMThresCfg_ExtUnderPres "Trailer2TPMThresCfg_ExtUnderPres_ISig_4";
BA_ "GenSigSendType" SG_ 2147485050 Trailer2TPMType_UB_ISig_4 7;
BA_ "Platform_VMCU1_Sig" SG_ 2147485050 Trailer2TPMType_UB_ISig_4 1;
BA_ "GenSigCycleTime" SG_ 2147485049 Trailer1TPMAxlTireCfg_Axle1_ISig 100;
BA_ "GenSigCycleTimeActive" SG_ 2147485049 Trailer1TPMAxlTireCfg_Axle1_ISig 100;
BA_ "GenSigStartValue" SG_ 2147485049 Trailer1TPMAxlTireCfg_Axle1_ISig 7;
BA_ "Platform_VMCU1_Sig" SG_ 2147485049 Trailer1TPMAxlTireCfg_Axle1_ISig 1;
BA_ "SystemSignalLongSymbol" SG_ 2147485049 Trailer1TPMAxlTireCfg_Axle1_ISig "Trailer1TPMAxlTireCfg_Axle1_ISig_4";
BA_ "GenSigCycleTime" SG_ 2147485049 Trailer1TPMThresCfg_ExtOverPres_ 100;
BA_ "GenSigCycleTimeActive" SG_ 2147485049 Trailer1TPMThresCfg_ExtOverPres_ 100;
BA_ "GenSigStartValue" SG_ 2147485049 Trailer1TPMThresCfg_ExtOverPres_ 255;
BA_ "NeedsUpdateBit" SG_ 2147485049 Trailer1TPMThresCfg_ExtOverPres_ 1;
BA_ "Platform_VMCU1_Sig" SG_ 2147485049 Trailer1TPMThresCfg_ExtOverPres_ 1;
BA_ "SystemSignalLongSymbol" SG_ 2147485049 Trailer1TPMThresCfg_ExtOverPres_ "Trailer1TPMThresCfg_ExtOverPres_ISig_4";
BA_ "GenSigCycleTime" SG_ 2147485049 Trailer1TPMAxlTireCfg_Axle2_ISig 100;
BA_ "GenSigCycleTimeActive" SG_ 2147485049 Trailer1TPMAxlTireCfg_Axle2_ISig 100;
BA_ "GenSigStartValue" SG_ 2147485049 Trailer1TPMAxlTireCfg_Axle2_ISig 7;
BA_ "Platform_VMCU1_Sig" SG_ 2147485049 Trailer1TPMAxlTireCfg_Axle2_ISig 1;
BA_ "SystemSignalLongSymbol" SG_ 2147485049 Trailer1TPMAxlTireCfg_Axle2_ISig "Trailer1TPMAxlTireCfg_Axle2_ISig_4";
BA_ "GenSigCycleTime" SG_ 2147485049 Trailer1TPMThresCfg_OverPres_ISi 100;
BA_ "GenSigCycleTimeActive" SG_ 2147485049 Trailer1TPMThresCfg_OverPres_ISi 100;
BA_ "GenSigStartValue" SG_ 2147485049 Trailer1TPMThresCfg_OverPres_ISi 255;
BA_ "NeedsUpdateBit" SG_ 2147485049 Trailer1TPMThresCfg_OverPres_ISi 1;
BA_ "Platform_VMCU1_Sig" SG_ 2147485049 Trailer1TPMThresCfg_OverPres_ISi 1;
BA_ "SystemSignalLongSymbol" SG_ 2147485049 Trailer1TPMThresCfg_OverPres_ISi "Trailer1TPMThresCfg_OverPres_ISig_4";
BA_ "GenSigCycleTime" SG_ 2147485049 Trailer1TPMAxlTireCfg_Axle5_ISig 100;
BA_ "GenSigCycleTimeActive" SG_ 2147485049 Trailer1TPMAxlTireCfg_Axle5_ISig 100;
BA_ "GenSigStartValue" SG_ 2147485049 Trailer1TPMAxlTireCfg_Axle5_ISig 7;
BA_ "Platform_VMCU1_Sig" SG_ 2147485049 Trailer1TPMAxlTireCfg_Axle5_ISig 1;
BA_ "SystemSignalLongSymbol" SG_ 2147485049 Trailer1TPMAxlTireCfg_Axle5_ISig "Trailer1TPMAxlTireCfg_Axle5_ISig_4";
BA_ "GenSigCycleTime" SG_ 2147485049 Trailer1TPMType_ISig_4 100;
BA_ "GenSigCycleTimeActive" SG_ 2147485049 Trailer1TPMType_ISig_4 100;
BA_ "GenSigStartValue" SG_ 2147485049 Trailer1TPMType_ISig_4 3;
BA_ "NeedsUpdateBit" SG_ 2147485049 Trailer1TPMType_ISig_4 1;
BA_ "Platform_VMCU1_Sig" SG_ 2147485049 Trailer1TPMType_ISig_4 1;
BA_ "GenSigCycleTime" SG_ 2147485049 MaintResetFailureCause 100;
BA_ "GenSigCycleTimeActive" SG_ 2147485049 MaintResetFailureCause 100;
BA_ "GenSigStartValue" SG_ 2147485049 MaintResetFailureCause 31;
BA_ "GenSigCycleTime" SG_ 2147485049 Trailer1TPMThresCfg_UnderPres_IS 100;
BA_ "GenSigCycleTimeActive" SG_ 2147485049 Trailer1TPMThresCfg_UnderPres_IS 100;
BA_ "GenSigStartValue" SG_ 2147485049 Trailer1TPMThresCfg_UnderPres_IS 255;
BA_ "NeedsUpdateBit" SG_ 2147485049 Trailer1TPMThresCfg_UnderPres_IS 1;
BA_ "Platform_VMCU1_Sig" SG_ 2147485049 Trailer1TPMThresCfg_UnderPres_IS 1;
BA_ "SystemSignalLongSymbol" SG_ 2147485049 Trailer1TPMThresCfg_UnderPres_IS "Trailer1TPMThresCfg_UnderPres_ISig_4";
BA_ "GenSigSendType" SG_ 2147485049 Trailer1TPMThresCfg_sg_UB_ISig_4 7;
BA_ "GenSigCycleTime" SG_ 2147485049 Trailer1TPMThresCfg_sg_UB_ISig_4 100;
BA_ "GenSigCycleTimeActive" SG_ 2147485049 Trailer1TPMThresCfg_sg_UB_ISig_4 100;
BA_ "Platform_VMCU1_Sig" SG_ 2147485049 Trailer1TPMThresCfg_sg_UB_ISig_4 1;
BA_ "GenSigCycleTime" SG_ 2147485049 Trailer1TPMThresCfg_ExtUnderPres 100;
BA_ "GenSigCycleTimeActive" SG_ 2147485049 Trailer1TPMThresCfg_ExtUnderPres 100;
BA_ "GenSigStartValue" SG_ 2147485049 Trailer1TPMThresCfg_ExtUnderPres 255;
BA_ "NeedsUpdateBit" SG_ 2147485049 Trailer1TPMThresCfg_ExtUnderPres 1;
BA_ "Platform_VMCU1_Sig" SG_ 2147485049 Trailer1TPMThresCfg_ExtUnderPres 1;
BA_ "SystemSignalLongSymbol" SG_ 2147485049 Trailer1TPMThresCfg_ExtUnderPres "Trailer1TPMThresCfg_ExtUnderPres_ISig_4";
BA_ "GenSigCycleTime" SG_ 2147485049 Trailer1TPMThresCfg_AxleNr_ISig_ 100;
BA_ "GenSigCycleTimeActive" SG_ 2147485049 Trailer1TPMThresCfg_AxleNr_ISig_ 100;
BA_ "GenSigStartValue" SG_ 2147485049 Trailer1TPMThresCfg_AxleNr_ISig_ 7;
BA_ "NeedsUpdateBit" SG_ 2147485049 Trailer1TPMThresCfg_AxleNr_ISig_ 1;
BA_ "Platform_VMCU1_Sig" SG_ 2147485049 Trailer1TPMThresCfg_AxleNr_ISig_ 1;
BA_ "SystemSignalLongSymbol" SG_ 2147485049 Trailer1TPMThresCfg_AxleNr_ISig_ "Trailer1TPMThresCfg_AxleNr_ISig_4";
BA_ "GenSigSendType" SG_ 2147485049 Trailer1TPMType_UB_ISig_4 7;
BA_ "Platform_VMCU1_Sig" SG_ 2147485049 Trailer1TPMType_UB_ISig_4 1;
BA_ "GenSigCycleTime" SG_ 2147485049 Trailer1TPMAxlTireCfg_Axle4_ISig 100;
BA_ "GenSigCycleTimeActive" SG_ 2147485049 Trailer1TPMAxlTireCfg_Axle4_ISig 100;
BA_ "GenSigStartValue" SG_ 2147485049 Trailer1TPMAxlTireCfg_Axle4_ISig 7;
BA_ "Platform_VMCU1_Sig" SG_ 2147485049 Trailer1TPMAxlTireCfg_Axle4_ISig 1;
BA_ "SystemSignalLongSymbol" SG_ 2147485049 Trailer1TPMAxlTireCfg_Axle4_ISig "Trailer1TPMAxlTireCfg_Axle4_ISig_4";
BA_ "GenSigCycleTime" SG_ 2147485049 Trailer1TPMAxlTireCfg_Axle3_ISig 100;
BA_ "GenSigCycleTimeActive" SG_ 2147485049 Trailer1TPMAxlTireCfg_Axle3_ISig 100;
BA_ "GenSigStartValue" SG_ 2147485049 Trailer1TPMAxlTireCfg_Axle3_ISig 7;
BA_ "Platform_VMCU1_Sig" SG_ 2147485049 Trailer1TPMAxlTireCfg_Axle3_ISig 1;
BA_ "SystemSignalLongSymbol" SG_ 2147485049 Trailer1TPMAxlTireCfg_Axle3_ISig "Trailer1TPMAxlTireCfg_Axle3_ISig_4";
BA_ "GenSigCycleTime" SG_ 2147485084 DistToEmptyLNG 100;
BA_ "GenSigCycleTimeActive" SG_ 2147485084 DistToEmptyLNG 100;
BA_ "GenSigStartValue" SG_ 2147485084 DistToEmptyLNG 65535;
BA_ "Platform_VMCU1_Sig" SG_ 2147485084 DistToEmptyLNG 1;
BA_ "GenSigCycleTime" SG_ 2147485084 DistToEmptyDiesel 100;
BA_ "GenSigCycleTimeActive" SG_ 2147485084 DistToEmptyDiesel 100;
BA_ "GenSigStartValue" SG_ 2147485084 DistToEmptyDiesel 65535;
BA_ "Platform_VMCU1_Sig" SG_ 2147485084 DistToEmptyDiesel 1;
BA_ "GenSigCycleTime" SG_ 2147485084 CoastingUseDistance_ISig_4 100;
BA_ "GenSigCycleTimeActive" SG_ 2147485084 CoastingUseDistance_ISig_4 100;
BA_ "GenSigStartValue" SG_ 2147485084 CoastingUseDistance_ISig_4 4294967295;
BA_ "Platform_VMCU1_Sig" SG_ 2147485084 CoastingUseDistance_ISig_4 1;
BA_ "GenSigCycleTime" SG_ 2147485083 EngSpeedOverThresholdTime_ISig_4 100;
BA_ "GenSigCycleTimeActive" SG_ 2147485083 EngSpeedOverThresholdTime_ISig_4 100;
BA_ "GenSigStartValue" SG_ 2147485083 EngSpeedOverThresholdTime_ISig_4 4294967295;
BA_ "Platform_VMCU1_Sig" SG_ 2147485083 EngSpeedOverThresholdTime_ISig_4 1;
BA_ "GenSigCycleTime" SG_ 2147485083 EngLoadOverThresholdDistance_ISi 100;
BA_ "GenSigCycleTimeActive" SG_ 2147485083 EngLoadOverThresholdDistance_ISi 100;
BA_ "GenSigStartValue" SG_ 2147485083 EngLoadOverThresholdDistance_ISi 4294967295;
BA_ "Platform_VMCU1_Sig" SG_ 2147485083 EngLoadOverThresholdDistance_ISi 1;
BA_ "SystemSignalLongSymbol" SG_ 2147485083 EngLoadOverThresholdDistance_ISi "EngLoadOverThresholdDistance_ISig_4";
BA_ "GenSigCycleTime" SG_ 2147485082 EngineGreenAreaFuel_ISig_4 100;
BA_ "GenSigCycleTimeActive" SG_ 2147485082 EngineGreenAreaFuel_ISig_4 100;
BA_ "GenSigStartValue" SG_ 2147485082 EngineGreenAreaFuel_ISig_4 4294967295;
BA_ "Platform_VMCU1_Sig" SG_ 2147485082 EngineGreenAreaFuel_ISig_4 1;
BA_ "GenSigCycleTime" SG_ 2147485082 LCCDistance_ISig_4 100;
BA_ "GenSigCycleTimeActive" SG_ 2147485082 LCCDistance_ISig_4 100;
BA_ "GenSigStartValue" SG_ 2147485082 LCCDistance_ISig_4 4294967295;
BA_ "Platform_VMCU1_Sig" SG_ 2147485082 LCCDistance_ISig_4 1;
BA_ "GenSigCycleTime" SG_ 2147485081 StopCounter_ISig_4 100;
BA_ "GenSigCycleTimeActive" SG_ 2147485081 StopCounter_ISig_4 100;
BA_ "GenSigStartValue" SG_ 2147485081 StopCounter_ISig_4 4294967295;
BA_ "Platform_VMCU1_Sig" SG_ 2147485081 StopCounter_ISig_4 1;
BA_ "GenSigCycleTime" SG_ 2147485081 OverspeedDistance_ISig_4 100;
BA_ "GenSigCycleTimeActive" SG_ 2147485081 OverspeedDistance_ISig_4 100;
BA_ "GenSigStartValue" SG_ 2147485081 OverspeedDistance_ISig_4 4294967295;
BA_ "Platform_VMCU1_Sig" SG_ 2147485081 OverspeedDistance_ISig_4 1;
BA_ "GenSigCycleTime" SG_ 2147485080 RobotizedGboxPowerModeTime_ISig_ 100;
BA_ "GenSigCycleTimeActive" SG_ 2147485080 RobotizedGboxPowerModeTime_ISig_ 100;
BA_ "GenSigStartValue" SG_ 2147485080 RobotizedGboxPowerModeTime_ISig_ 4294967295;
BA_ "Platform_VMCU1_Sig" SG_ 2147485080 RobotizedGboxPowerModeTime_ISig_ 1;
BA_ "SystemSignalLongSymbol" SG_ 2147485080 RobotizedGboxPowerModeTime_ISig_ "RobotizedGboxPowerModeTime_ISig_4";
BA_ "GenSigCycleTime" SG_ 2147485080 TotalServiceBrakeCounter_ISig_4 100;
BA_ "GenSigCycleTimeActive" SG_ 2147485080 TotalServiceBrakeCounter_ISig_4 100;
BA_ "GenSigStartValue" SG_ 2147485080 TotalServiceBrakeCounter_ISig_4 4294967295;
BA_ "Platform_VMCU1_Sig" SG_ 2147485080 TotalServiceBrakeCounter_ISig_4 1;
BA_ "GenSigCycleTime" SG_ 2147485079 RobotizedGboxManualModeTime_ISig 100;
BA_ "GenSigCycleTimeActive" SG_ 2147485079 RobotizedGboxManualModeTime_ISig 100;
BA_ "GenSigStartValue" SG_ 2147485079 RobotizedGboxManualModeTime_ISig 4294967295;
BA_ "Platform_VMCU1_Sig" SG_ 2147485079 RobotizedGboxManualModeTime_ISig 1;
BA_ "SystemSignalLongSymbol" SG_ 2147485079 RobotizedGboxManualModeTime_ISig "RobotizedGboxManualModeTime_ISig_4";
BA_ "GenSigCycleTime" SG_ 2147485079 RobotizedGboxAutoModeTime_ISig_4 100;
BA_ "GenSigCycleTimeActive" SG_ 2147485079 RobotizedGboxAutoModeTime_ISig_4 100;
BA_ "GenSigStartValue" SG_ 2147485079 RobotizedGboxAutoModeTime_ISig_4 4294967295;
BA_ "Platform_VMCU1_Sig" SG_ 2147485079 RobotizedGboxAutoModeTime_ISig_4 1;
BA_ "GenSigSendType" SG_ 2147484894 PusherAxleLoad_UB_ISig_4 7;
BA_ "Platform_VMCU1_Sig" SG_ 2147484894 PusherAxleLoad_UB_ISig_4 1;
BA_ "GenSigCycleTime" SG_ 2147484894 PusherAxleLoad_ISig_4 100;
BA_ "GenSigCycleTimeActive" SG_ 2147484894 PusherAxleLoad_ISig_4 100;
BA_ "GenSigStartValue" SG_ 2147484894 PusherAxleLoad_ISig_4 65535;
BA_ "NeedsUpdateBit" SG_ 2147484894 PusherAxleLoad_ISig_4 1;
BA_ "Platform_VMCU1_Sig" SG_ 2147484894 PusherAxleLoad_ISig_4 1;
BA_ "SeToolAncestorID_SIGNAL" SG_ 2147484894 PusherAxleLoad_ISig_4 "x0000001D0412EB1E";
BA_ "SeToolItemID_SIGNAL" SG_ 2147484894 PusherAxleLoad_ISig_4 "x0000001D04274C69";
BA_ "SeToolName_SIGNAL" SG_ 2147484894 PusherAxleLoad_ISig_4 "PusherAxleLoad";
BA_ "SeToolVersion_SIGNAL" SG_ 2147484894 PusherAxleLoad_ISig_4 "3";
BA_ "GenSigCycleTime" SG_ 2147484894 FogLight_Front_cmd_ISig_4 100;
BA_ "GenSigCycleTimeActive" SG_ 2147484894 FogLight_Front_cmd_ISig_4 100;
BA_ "GenSigStartValue" SG_ 2147484894 FogLight_Front_cmd_ISig_4 3;
BA_ "Platform_VMCU1_Sig" SG_ 2147484894 FogLight_Front_cmd_ISig_4 1;
BA_ "SeToolAncestorID_SIGNAL" SG_ 2147484894 FogLight_Front_cmd_ISig_4 "x0000001D04135140";
BA_ "SeToolItemID_SIGNAL" SG_ 2147484894 FogLight_Front_cmd_ISig_4 "x0000001D04384FD1";
BA_ "SeToolName_SIGNAL" SG_ 2147484894 FogLight_Front_cmd_ISig_4 "FogLight_Front_cmd";
BA_ "SeToolVersion_SIGNAL" SG_ 2147484894 FogLight_Front_cmd_ISig_4 "2";
BA_ "GenSigCycleTime" SG_ 2147484894 TagAxleLoad_ISig_4 100;
BA_ "GenSigCycleTimeActive" SG_ 2147484894 TagAxleLoad_ISig_4 100;
BA_ "GenSigStartValue" SG_ 2147484894 TagAxleLoad_ISig_4 65535;
BA_ "NeedsUpdateBit" SG_ 2147484894 TagAxleLoad_ISig_4 1;
BA_ "Platform_VMCU1_Sig" SG_ 2147484894 TagAxleLoad_ISig_4 1;
BA_ "SeToolAncestorID_SIGNAL" SG_ 2147484894 TagAxleLoad_ISig_4 "x0000001D0412EB1E";
BA_ "SeToolItemID_SIGNAL" SG_ 2147484894 TagAxleLoad_ISig_4 "x0000001D04274C69";
BA_ "SeToolName_SIGNAL" SG_ 2147484894 TagAxleLoad_ISig_4 "TagAxleLoad";
BA_ "SeToolVersion_SIGNAL" SG_ 2147484894 TagAxleLoad_ISig_4 "3";
BA_ "GenSigSendType" SG_ 2147484894 TagAxleLoad_UB_ISig_4 7;
BA_ "Platform_VMCU1_Sig" SG_ 2147484894 TagAxleLoad_UB_ISig_4 1;
BA_ "GenSigCycleTime" SG_ 2147484891 SelfStartAssistSwitch_Input_ISig 100;
BA_ "GenSigCycleTimeActive" SG_ 2147484891 SelfStartAssistSwitch_Input_ISig 100;
BA_ "GenSigStartValue" SG_ 2147484891 SelfStartAssistSwitch_Input_ISig 3;
BA_ "SystemSignalLongSymbol" SG_ 2147484891 SelfStartAssistSwitch_Input_ISig "SelfStartAssistSwitch_Input_ISig_4";
BA_ "GenSigCycleTime" SG_ 2147484891 DriveAxleLoad_ISig_4 100;
BA_ "GenSigCycleTimeActive" SG_ 2147484891 DriveAxleLoad_ISig_4 100;
BA_ "GenSigStartValue" SG_ 2147484891 DriveAxleLoad_ISig_4 65535;
BA_ "NeedsUpdateBit" SG_ 2147484891 DriveAxleLoad_ISig_4 1;
BA_ "Platform_VMCU1_Sig" SG_ 2147484891 DriveAxleLoad_ISig_4 1;
BA_ "SeToolAncestorID_SIGNAL" SG_ 2147484891 DriveAxleLoad_ISig_4 "x0000001D0412EB1E";
BA_ "SeToolItemID_SIGNAL" SG_ 2147484891 DriveAxleLoad_ISig_4 "x0000001D04274C69";
BA_ "SeToolName_SIGNAL" SG_ 2147484891 DriveAxleLoad_ISig_4 "DriveAxleLoad";
BA_ "SeToolVersion_SIGNAL" SG_ 2147484891 DriveAxleLoad_ISig_4 "3";
BA_ "GenSigCycleTime" SG_ 2147484891 BatterySOCAlertRawData_rqst_ISig 100;
BA_ "GenSigCycleTimeActive" SG_ 2147484891 BatterySOCAlertRawData_rqst_ISig 100;
BA_ "GenSigStartValue" SG_ 2147484891 BatterySOCAlertRawData_rqst_ISig 7;
BA_ "Platform_VMCU1_Sig" SG_ 2147484891 BatterySOCAlertRawData_rqst_ISig 1;
BA_ "SystemSignalLongSymbol" SG_ 2147484891 BatterySOCAlertRawData_rqst_ISig "BatterySOCAlertRawData_rqst_ISig_4";
BA_ "GenSigCycleTime" SG_ 2147484891 LivBatDisconnectDetectStat_ISig_ 100;
BA_ "GenSigCycleTimeActive" SG_ 2147484891 LivBatDisconnectDetectStat_ISig_ 100;
BA_ "GenSigStartValue" SG_ 2147484891 LivBatDisconnectDetectStat_ISig_ 3;
BA_ "SystemSignalLongSymbol" SG_ 2147484891 LivBatDisconnectDetectStat_ISig_ "LivBatDisconnectDetectStat_ISig_4";
BA_ "GenSigSendType" SG_ 2147484891 SecondaryDriveAxleLoad_UB_ISig_4 7;
BA_ "Platform_VMCU1_Sig" SG_ 2147484891 SecondaryDriveAxleLoad_UB_ISig_4 1;
BA_ "GenSigCycleTime" SG_ 2147484891 SelfStartAssist_stat_ISig_4 100;
BA_ "GenSigCycleTimeActive" SG_ 2147484891 SelfStartAssist_stat_ISig_4 100;
BA_ "GenSigStartValue" SG_ 2147484891 SelfStartAssist_stat_ISig_4 3;
BA_ "Platform_VMCU1_Sig" SG_ 2147484891 SelfStartAssist_stat_ISig_4 1;
BA_ "GenSigSendType" SG_ 2147484891 DriveAxleLoad_UB_ISig_4 7;
BA_ "Platform_VMCU1_Sig" SG_ 2147484891 DriveAxleLoad_UB_ISig_4 1;
BA_ "GenSigCycleTime" SG_ 2147484891 JumpChargeAlert_stat_ISig_4 100;
BA_ "GenSigCycleTimeActive" SG_ 2147484891 JumpChargeAlert_stat_ISig_4 100;
BA_ "GenSigStartValue" SG_ 2147484891 JumpChargeAlert_stat_ISig_4 7;
BA_ "Platform_VMCU1_Sig" SG_ 2147484891 JumpChargeAlert_stat_ISig_4 1;
BA_ "GenSigCycleTime" SG_ 2147484891 GChargerStatus_ISig_4 100;
BA_ "GenSigCycleTimeActive" SG_ 2147484891 GChargerStatus_ISig_4 100;
BA_ "GenSigStartValue" SG_ 2147484891 GChargerStatus_ISig_4 7;
BA_ "GenSigCycleTime" SG_ 2147484891 ShortStopHeater_status_ISig_4 100;
BA_ "GenSigCycleTimeActive" SG_ 2147484891 ShortStopHeater_status_ISig_4 100;
BA_ "GenSigStartValue" SG_ 2147484891 ShortStopHeater_status_ISig_4 7;
BA_ "Platform_VMCU1_Sig" SG_ 2147484891 ShortStopHeater_status_ISig_4 1;
BA_ "GenSigCycleTime" SG_ 2147484891 SecondaryDriveAxleLoad_ISig_4 100;
BA_ "GenSigCycleTimeActive" SG_ 2147484891 SecondaryDriveAxleLoad_ISig_4 100;
BA_ "GenSigStartValue" SG_ 2147484891 SecondaryDriveAxleLoad_ISig_4 65535;
BA_ "NeedsUpdateBit" SG_ 2147484891 SecondaryDriveAxleLoad_ISig_4 1;
BA_ "Platform_VMCU1_Sig" SG_ 2147484891 SecondaryDriveAxleLoad_ISig_4 1;
BA_ "SeToolAncestorID_SIGNAL" SG_ 2147484891 SecondaryDriveAxleLoad_ISig_4 "x0000001D0412EB1E";
BA_ "SeToolItemID_SIGNAL" SG_ 2147484891 SecondaryDriveAxleLoad_ISig_4 "x0000001D04274C69";
BA_ "SeToolName_SIGNAL" SG_ 2147484891 SecondaryDriveAxleLoad_ISig_4 "SecondaryDriveAxleLoad";
BA_ "SeToolVersion_SIGNAL" SG_ 2147484891 SecondaryDriveAxleLoad_ISig_4 "3";
BA_ "GenSigCycleTime" SG_ 2147484891 StartBatteryDisplay_stat_ISig_4 100;
BA_ "GenSigCycleTimeActive" SG_ 2147484891 StartBatteryDisplay_stat_ISig_4 100;
BA_ "GenSigStartValue" SG_ 2147484891 StartBatteryDisplay_stat_ISig_4 7;
BA_ "Platform_VMCU1_Sig" SG_ 2147484891 StartBatteryDisplay_stat_ISig_4 1;
BA_ "GenSigSendType" SG_ 2147485057 VMCU_BB2_57P_FCS_581 7;
BA_ "Platform_VMCU1_Sig" SG_ 2147485057 VMCU_BB2_57P_FCS_581 1;
BA_ "GenSigCycleTime" SG_ 2147485056 MaintService_ServiceCalendarTime 100;
BA_ "GenSigCycleTimeActive" SG_ 2147485056 MaintService_ServiceCalendarTime 100;
BA_ "GenSigStartValue" SG_ 2147485056 MaintService_ServiceCalendarTime 4294967295;
BA_ "Platform_VMCU1_Sig" SG_ 2147485056 MaintService_ServiceCalendarTime 1;
BA_ "SystemSignalLongSymbol" SG_ 2147485056 MaintService_ServiceCalendarTime "MaintService_ServiceCalendarTime_ISig_4_580";
BA_ "GenSigCycleTime" SG_ 2147485056 MaintService_EngTimeID_ISig_4_58 100;
BA_ "GenSigCycleTimeActive" SG_ 2147485056 MaintService_EngTimeID_ISig_4_58 100;
BA_ "GenSigStartValue" SG_ 2147485056 MaintService_EngTimeID_ISig_4_58 255;
BA_ "Platform_VMCU1_Sig" SG_ 2147485056 MaintService_EngTimeID_ISig_4_58 1;
BA_ "SystemSignalLongSymbol" SG_ 2147485056 MaintService_EngTimeID_ISig_4_58 "MaintService_EngTimeID_ISig_4_580";
BA_ "GenSigCycleTime" SG_ 2147485056 MaintService_DistID_ISig_4_580 100;
BA_ "GenSigCycleTimeActive" SG_ 2147485056 MaintService_DistID_ISig_4_580 100;
BA_ "GenSigStartValue" SG_ 2147485056 MaintService_DistID_ISig_4_580 255;
BA_ "Platform_VMCU1_Sig" SG_ 2147485056 MaintService_DistID_ISig_4_580 1;
BA_ "GenSigCycleTime" SG_ 2147485056 MaintService_ServiceDistance_ISi 100;
BA_ "GenSigCycleTimeActive" SG_ 2147485056 MaintService_ServiceDistance_ISi 100;
BA_ "GenSigStartValue" SG_ 2147485056 MaintService_ServiceDistance_ISi 4294967295;
BA_ "Platform_VMCU1_Sig" SG_ 2147485056 MaintService_ServiceDistance_ISi 1;
BA_ "SystemSignalLongSymbol" SG_ 2147485056 MaintService_ServiceDistance_ISi "MaintService_ServiceDistance_ISig_4_580";
BA_ "GenSigCycleTime" SG_ 2147485056 MaintService_ServiceEngineTime_I 100;
BA_ "GenSigCycleTimeActive" SG_ 2147485056 MaintService_ServiceEngineTime_I 100;
BA_ "GenSigStartValue" SG_ 2147485056 MaintService_ServiceEngineTime_I 4294967295;
BA_ "Platform_VMCU1_Sig" SG_ 2147485056 MaintService_ServiceEngineTime_I 1;
BA_ "SystemSignalLongSymbol" SG_ 2147485056 MaintService_ServiceEngineTime_I "MaintService_ServiceEngineTime_ISig_4_580";
BA_ "GenSigCycleTime" SG_ 2147485056 MaintService_CalDateID_ISig_4_58 100;
BA_ "GenSigCycleTimeActive" SG_ 2147485056 MaintService_CalDateID_ISig_4_58 100;
BA_ "GenSigStartValue" SG_ 2147485056 MaintService_CalDateID_ISig_4_58 255;
BA_ "Platform_VMCU1_Sig" SG_ 2147485056 MaintService_CalDateID_ISig_4_58 1;
BA_ "SystemSignalLongSymbol" SG_ 2147485056 MaintService_CalDateID_ISig_4_58 "MaintService_CalDateID_ISig_4_580";
BA_ "GenSigSendType" SG_ 2147485047 VMCU_BB2_57P_FCS_577 7;
BA_ "Platform_VMCU1_Sig" SG_ 2147485047 VMCU_BB2_57P_FCS_577 1;
BA_ "GenSigCycleTime" SG_ 2147485046 MaintService_ServiceEngineT_0000 100;
BA_ "GenSigCycleTimeActive" SG_ 2147485046 MaintService_ServiceEngineT_0000 100;
BA_ "GenSigStartValue" SG_ 2147485046 MaintService_ServiceEngineT_0000 4294967295;
BA_ "Platform_VMCU1_Sig" SG_ 2147485046 MaintService_ServiceEngineT_0000 1;
BA_ "SystemSignalLongSymbol" SG_ 2147485046 MaintService_ServiceEngineT_0000 "MaintService_ServiceEngineTime_ISig_4_576";
BA_ "GenSigCycleTime" SG_ 2147485046 MaintService_EngTimeID_ISig_4_57 100;
BA_ "GenSigCycleTimeActive" SG_ 2147485046 MaintService_EngTimeID_ISig_4_57 100;
BA_ "GenSigStartValue" SG_ 2147485046 MaintService_EngTimeID_ISig_4_57 255;
BA_ "Platform_VMCU1_Sig" SG_ 2147485046 MaintService_EngTimeID_ISig_4_57 1;
BA_ "SystemSignalLongSymbol" SG_ 2147485046 MaintService_EngTimeID_ISig_4_57 "MaintService_EngTimeID_ISig_4_576";
BA_ "GenSigCycleTime" SG_ 2147485046 MaintService_DistID_ISig_4_576 100;
BA_ "GenSigCycleTimeActive" SG_ 2147485046 MaintService_DistID_ISig_4_576 100;
BA_ "GenSigStartValue" SG_ 2147485046 MaintService_DistID_ISig_4_576 255;
BA_ "Platform_VMCU1_Sig" SG_ 2147485046 MaintService_DistID_ISig_4_576 1;
BA_ "GenSigCycleTime" SG_ 2147485046 MaintService_ServiceDistanc_0000 100;
BA_ "GenSigCycleTimeActive" SG_ 2147485046 MaintService_ServiceDistanc_0000 100;
BA_ "GenSigStartValue" SG_ 2147485046 MaintService_ServiceDistanc_0000 4294967295;
BA_ "Platform_VMCU1_Sig" SG_ 2147485046 MaintService_ServiceDistanc_0000 1;
BA_ "SystemSignalLongSymbol" SG_ 2147485046 MaintService_ServiceDistanc_0000 "MaintService_ServiceDistance_ISig_4_576";
BA_ "GenSigCycleTime" SG_ 2147485046 MaintService_CalDateID_ISig_4_57 100;
BA_ "GenSigCycleTimeActive" SG_ 2147485046 MaintService_CalDateID_ISig_4_57 100;
BA_ "GenSigStartValue" SG_ 2147485046 MaintService_CalDateID_ISig_4_57 255;
BA_ "Platform_VMCU1_Sig" SG_ 2147485046 MaintService_CalDateID_ISig_4_57 1;
BA_ "SystemSignalLongSymbol" SG_ 2147485046 MaintService_CalDateID_ISig_4_57 "MaintService_CalDateID_ISig_4_576";
BA_ "GenSigCycleTime" SG_ 2147485046 MaintService_ServiceCalenda_0000 100;
BA_ "GenSigCycleTimeActive" SG_ 2147485046 MaintService_ServiceCalenda_0000 100;
BA_ "GenSigStartValue" SG_ 2147485046 MaintService_ServiceCalenda_0000 4294967295;
BA_ "Platform_VMCU1_Sig" SG_ 2147485046 MaintService_ServiceCalenda_0000 1;
BA_ "SystemSignalLongSymbol" SG_ 2147485046 MaintService_ServiceCalenda_0000 "MaintService_ServiceCalendarTime_ISig_4_576";
BA_ "GenSigCycleTime" SG_ 2147485076 EngTrueIdleSpeedTime_ISig_4 100;
BA_ "GenSigCycleTimeActive" SG_ 2147485076 EngTrueIdleSpeedTime_ISig_4 100;
BA_ "GenSigStartValue" SG_ 2147485076 EngTrueIdleSpeedTime_ISig_4 4294967295;
BA_ "GenSigMaxLatency" SG_ 2147485076 EngTrueIdleSpeedTime_ISig_4 1345;
BA_ "Platform_VMCU1_Sig" SG_ 2147485076 EngTrueIdleSpeedTime_ISig_4 1;
BA_ "GenSigCycleTime" SG_ 2147485076 EngineGreenAreaOutTime_ISig_4 100;
BA_ "GenSigCycleTimeActive" SG_ 2147485076 EngineGreenAreaOutTime_ISig_4 100;
BA_ "GenSigStartValue" SG_ 2147485076 EngineGreenAreaOutTime_ISig_4 4294967295;
BA_ "GenSigMaxLatency" SG_ 2147485076 EngineGreenAreaOutTime_ISig_4 1345;
BA_ "Platform_VMCU1_Sig" SG_ 2147485076 EngineGreenAreaOutTime_ISig_4 1;
BA_ "GenSigCycleTime" SG_ 2147484707 BatterySOCnom_ISig_4 100;
BA_ "GenSigCycleTimeActive" SG_ 2147484707 BatterySOCnom_ISig_4 100;
BA_ "GenSigStartValue" SG_ 2147484707 BatterySOCnom_ISig_4 255;
BA_ "GenSigMaxLatency" SG_ 2147484707 BatterySOCnom_ISig_4 187;
BA_ "Platform_VMCU1_Sig" SG_ 2147484707 BatterySOCnom_ISig_4 1;
BA_ "SeToolAncestorID_SIGNAL" SG_ 2147484707 BatterySOCnom_ISig_4 "x0000001D0431FB91";
BA_ "SeToolItemID_SIGNAL" SG_ 2147484707 BatterySOCnom_ISig_4 "x0000001D0431FB91";
BA_ "SeToolName_SIGNAL" SG_ 2147484707 BatterySOCnom_ISig_4 "BatterySOCnom";
BA_ "SeToolVersion_SIGNAL" SG_ 2147484707 BatterySOCnom_ISig_4 "1";
BA_ "GenSigCycleTime" SG_ 2147484707 BatterySOH_ISig_4 100;
BA_ "GenSigCycleTimeActive" SG_ 2147484707 BatterySOH_ISig_4 100;
BA_ "GenSigStartValue" SG_ 2147484707 BatterySOH_ISig_4 255;
BA_ "GenSigMaxLatency" SG_ 2147484707 BatterySOH_ISig_4 187;
BA_ "Platform_VMCU1_Sig" SG_ 2147484707 BatterySOH_ISig_4 1;
BA_ "SeToolAncestorID_SIGNAL" SG_ 2147484707 BatterySOH_ISig_4 "x0000001D041491DF";
BA_ "SeToolItemID_SIGNAL" SG_ 2147484707 BatterySOH_ISig_4 "x0000001D041491DF";
BA_ "SeToolName_SIGNAL" SG_ 2147484707 BatterySOH_ISig_4 "BatterySOH";
BA_ "SeToolVersion_SIGNAL" SG_ 2147484707 BatterySOH_ISig_4 "1";
BA_ "GenSigCycleTime" SG_ 2147484707 ReducedLoadMode_stat_ISig_4 100;
BA_ "GenSigCycleTimeActive" SG_ 2147484707 ReducedLoadMode_stat_ISig_4 100;
BA_ "GenSigStartValue" SG_ 2147484707 ReducedLoadMode_stat_ISig_4 3;
BA_ "Platform_VMCU1_Sig" SG_ 2147484707 ReducedLoadMode_stat_ISig_4 1;
BA_ "GenSigCycleTime" SG_ 2147484707 BatterySOCAlert_rqst_ISig_4 100;
BA_ "GenSigCycleTimeActive" SG_ 2147484707 BatterySOCAlert_rqst_ISig_4 100;
BA_ "GenSigStartValue" SG_ 2147484707 BatterySOCAlert_rqst_ISig_4 7;
BA_ "GenSigMaxLatency" SG_ 2147484707 BatterySOCAlert_rqst_ISig_4 187;
BA_ "Platform_VMCU1_Sig" SG_ 2147484707 BatterySOCAlert_rqst_ISig_4 1;
BA_ "GenSigCycleTime" SG_ 2147484707 BatteryVoltageDisplayValue_ISig_ 100;
BA_ "GenSigCycleTimeActive" SG_ 2147484707 BatteryVoltageDisplayValue_ISig_ 100;
BA_ "GenSigStartValue" SG_ 2147484707 BatteryVoltageDisplayValue_ISig_ 65535;
BA_ "GenSigMaxLatency" SG_ 2147484707 BatteryVoltageDisplayValue_ISig_ 187;
BA_ "Platform_VMCU1_Sig" SG_ 2147484707 BatteryVoltageDisplayValue_ISig_ 1;
BA_ "SystemSignalLongSymbol" SG_ 2147484707 BatteryVoltageDisplayValue_ISig_ "BatteryVoltageDisplayValue_ISig_4";
BA_ "GenSigCycleTime" SG_ 2147484707 BatteryCurrent_ISig_4 100;
BA_ "GenSigCycleTimeActive" SG_ 2147484707 BatteryCurrent_ISig_4 100;
BA_ "GenSigStartValue" SG_ 2147484707 BatteryCurrent_ISig_4 65535;
BA_ "GenSigMaxLatency" SG_ 2147484707 BatteryCurrent_ISig_4 187;
BA_ "Platform_VMCU1_Sig" SG_ 2147484707 BatteryCurrent_ISig_4 1;
BA_ "SeToolAncestorID_SIGNAL" SG_ 2147484707 BatteryCurrent_ISig_4 "x0000001D041491E4";
BA_ "SeToolItemID_SIGNAL" SG_ 2147484707 BatteryCurrent_ISig_4 "x0000001D042E2456";
BA_ "SeToolName_SIGNAL" SG_ 2147484707 BatteryCurrent_ISig_4 "BatteryCurrent";
BA_ "SeToolVersion_SIGNAL" SG_ 2147484707 BatteryCurrent_ISig_4 "2";
BA_ "GenSigCycleTime" SG_ 2147484573 MaintOilQuality 100;
BA_ "GenSigCycleTimeActive" SG_ 2147484573 MaintOilQuality 100;
BA_ "GenSigStartValue" SG_ 2147484573 MaintOilQuality 7;
BA_ "GenSigMaxLatency" SG_ 2147484573 MaintOilQuality 112;
BA_ "Platform_VMCU1_Sig" SG_ 2147484573 MaintOilQuality 1;
BA_ "GenSigCycleTime" SG_ 2147484573 ECSLimpHomeNotification_ISig_4 100;
BA_ "GenSigCycleTimeActive" SG_ 2147484573 ECSLimpHomeNotification_ISig_4 100;
BA_ "GenSigStartValue" SG_ 2147484573 ECSLimpHomeNotification_ISig_4 7;
BA_ "GenSigMaxLatency" SG_ 2147484573 ECSLimpHomeNotification_ISig_4 63;
BA_ "Platform_VMCU1_Sig" SG_ 2147484573 ECSLimpHomeNotification_ISig_4 1;
BA_ "GenSigCycleTime" SG_ 2147484573 MaintenanceResetStatus 100;
BA_ "GenSigCycleTimeActive" SG_ 2147484573 MaintenanceResetStatus 100;
BA_ "GenSigStartValue" SG_ 2147484573 MaintenanceResetStatus 7;
BA_ "Platform_VMCU1_Sig" SG_ 2147484573 MaintenanceResetStatus 1;
BA_ "GenSigCycleTime" SG_ 2147484573 FirstAxleLowerPrioSelected_ISig_ 100;
BA_ "GenSigCycleTimeActive" SG_ 2147484573 FirstAxleLowerPrioSelected_ISig_ 100;
BA_ "GenSigStartValue" SG_ 2147484573 FirstAxleLowerPrioSelected_ISig_ 7;
BA_ "SystemSignalLongSymbol" SG_ 2147484573 FirstAxleLowerPrioSelected_ISig_ "FirstAxleLowerPrioSelected_ISig_4";
BA_ "GenSigCycleTime" SG_ 2147484573 MaintOilReset 100;
BA_ "GenSigCycleTimeActive" SG_ 2147484573 MaintOilReset 100;
BA_ "GenSigStartValue" SG_ 2147484573 MaintOilReset 3;
BA_ "GenSigMaxLatency" SG_ 2147484573 MaintOilReset 112;
BA_ "Platform_VMCU1_Sig" SG_ 2147484573 MaintOilReset 1;
BA_ "GenSigCycleTime" SG_ 2147484573 RssInhibStartEngine_rqst 100;
BA_ "GenSigCycleTimeActive" SG_ 2147484573 RssInhibStartEngine_rqst 100;
BA_ "GenSigStartValue" SG_ 2147484573 RssInhibStartEngine_rqst 3;
BA_ "GenSigMaxLatency" SG_ 2147484573 RssInhibStartEngine_rqst 112;
BA_ "Platform_VMCU1_Sig" SG_ 2147484573 RssInhibStartEngine_rqst 1;
BA_ "GenSigCycleTime" SG_ 2147484573 PositionLightRequest_status 100;
BA_ "GenSigCycleTimeActive" SG_ 2147484573 PositionLightRequest_status 100;
BA_ "GenSigStartValue" SG_ 2147484573 PositionLightRequest_status 3;
BA_ "GenSigMaxLatency" SG_ 2147484573 PositionLightRequest_status 112;
BA_ "Platform_VMCU1_Sig" SG_ 2147484573 PositionLightRequest_status 1;
BA_ "GenSigCycleTime" SG_ 2147484573 ExtraBBTailLiftStatus_ISig_4 100;
BA_ "GenSigCycleTimeActive" SG_ 2147484573 ExtraBBTailLiftStatus_ISig_4 100;
BA_ "GenSigStartValue" SG_ 2147484573 ExtraBBTailLiftStatus_ISig_4 3;
BA_ "GenSigMaxLatency" SG_ 2147484573 ExtraBBTailLiftStatus_ISig_4 112;
BA_ "Platform_VMCU1_Sig" SG_ 2147484573 ExtraBBTailLiftStatus_ISig_4 1;
BA_ "GenSigCycleTime" SG_ 2147484573 MaintenanceNotification_ISig_4 100;
BA_ "GenSigCycleTimeActive" SG_ 2147484573 MaintenanceNotification_ISig_4 100;
BA_ "GenSigStartValue" SG_ 2147484573 MaintenanceNotification_ISig_4 7;
BA_ "GenSigMaxLatency" SG_ 2147484573 MaintenanceNotification_ISig_4 112;
BA_ "Platform_VMCU1_Sig" SG_ 2147484573 MaintenanceNotification_ISig_4 1;
BA_ "GenSigCycleTime" SG_ 2147484573 ExtraBBSlidable5thWheelStatus 100;
BA_ "GenSigCycleTimeActive" SG_ 2147484573 ExtraBBSlidable5thWheelStatus 100;
BA_ "GenSigStartValue" SG_ 2147484573 ExtraBBSlidable5thWheelStatus 3;
BA_ "GenSigMaxLatency" SG_ 2147484573 ExtraBBSlidable5thWheelStatus 112;
BA_ "Platform_VMCU1_Sig" SG_ 2147484573 ExtraBBSlidable5thWheelStatus 1;
BA_ "GenSigCycleTime" SG_ 2147484573 ParkBrakeReleasePossible_stat 100;
BA_ "GenSigCycleTimeActive" SG_ 2147484573 ParkBrakeReleasePossible_stat 100;
BA_ "GenSigStartValue" SG_ 2147484573 ParkBrakeReleasePossible_stat 3;
BA_ "GenSigMaxLatency" SG_ 2147484573 ParkBrakeReleasePossible_stat 112;
BA_ "Platform_VMCU1_Sig" SG_ 2147484573 ParkBrakeReleasePossible_stat 1;
BA_ "GenSigCycleTime" SG_ 2147484573 LoadDistributionALDChangeACK_ISi 100;
BA_ "GenSigCycleTimeActive" SG_ 2147484573 LoadDistributionALDChangeACK_ISi 100;
BA_ "GenSigStartValue" SG_ 2147484573 LoadDistributionALDChangeACK_ISi 7;
BA_ "GenSigMaxLatency" SG_ 2147484573 LoadDistributionALDChangeACK_ISi 112;
BA_ "Platform_VMCU1_Sig" SG_ 2147484573 LoadDistributionALDChangeACK_ISi 1;
BA_ "SystemSignalLongSymbol" SG_ 2147484573 LoadDistributionALDChangeACK_ISi "LoadDistributionALDChangeACK_ISig_4";
BA_ "GenSigSendType" SG_ 2147484573 PoorAirPressureInfo_UB 7;
BA_ "Platform_VMCU1_Sig" SG_ 2147484573 PoorAirPressureInfo_UB 1;
BA_ "GenSigCycleTime" SG_ 2147484573 ParkBrakeWorkshopMode_ISig_4 100;
BA_ "GenSigCycleTimeActive" SG_ 2147484573 ParkBrakeWorkshopMode_ISig_4 100;
BA_ "GenSigStartValue" SG_ 2147484573 ParkBrakeWorkshopMode_ISig_4 3;
BA_ "GenSigMaxLatency" SG_ 2147484573 ParkBrakeWorkshopMode_ISig_4 112;
BA_ "Platform_VMCU1_Sig" SG_ 2147484573 ParkBrakeWorkshopMode_ISig_4 1;
BA_ "GenSigCycleTime" SG_ 2147484573 ExtraBBContainerUnlockStatus 100;
BA_ "GenSigCycleTimeActive" SG_ 2147484573 ExtraBBContainerUnlockStatus 100;
BA_ "GenSigStartValue" SG_ 2147484573 ExtraBBContainerUnlockStatus 3;
BA_ "GenSigMaxLatency" SG_ 2147484573 ExtraBBContainerUnlockStatus 112;
BA_ "Platform_VMCU1_Sig" SG_ 2147484573 ExtraBBContainerUnlockStatus 1;
BA_ "GenSigCycleTime" SG_ 2147484573 MainBeamRequest_status_ISig_4 100;
BA_ "GenSigCycleTimeActive" SG_ 2147484573 MainBeamRequest_status_ISig_4 100;
BA_ "GenSigStartValue" SG_ 2147484573 MainBeamRequest_status_ISig_4 3;
BA_ "GenSigMaxLatency" SG_ 2147484573 MainBeamRequest_status_ISig_4 112;
BA_ "Platform_VMCU1_Sig" SG_ 2147484573 MainBeamRequest_status_ISig_4 1;
BA_ "GenSigCycleTime" SG_ 2147484573 ExtraBBCraneStatus_ISig_4 100;
BA_ "GenSigCycleTimeActive" SG_ 2147484573 ExtraBBCraneStatus_ISig_4 100;
BA_ "GenSigStartValue" SG_ 2147484573 ExtraBBCraneStatus_ISig_4 7;
BA_ "GenSigMaxLatency" SG_ 2147484573 ExtraBBCraneStatus_ISig_4 112;
BA_ "Platform_VMCU1_Sig" SG_ 2147484573 ExtraBBCraneStatus_ISig_4 1;
BA_ "GenSigCycleTime" SG_ 2147484573 AirCompressorStatus 100;
BA_ "GenSigCycleTimeActive" SG_ 2147484573 AirCompressorStatus 100;
BA_ "GenSigStartValue" SG_ 2147484573 AirCompressorStatus 3;
BA_ "Platform_VMCU1_Sig" SG_ 2147484573 AirCompressorStatus 1;
BA_ "GenSigCycleTime" SG_ 2147484573 TrailerABSStatus_ISig_4 100;
BA_ "GenSigCycleTimeActive" SG_ 2147484573 TrailerABSStatus_ISig_4 100;
BA_ "GenSigStartValue" SG_ 2147484573 TrailerABSStatus_ISig_4 3;
BA_ "GenSigMaxLatency" SG_ 2147484573 TrailerABSStatus_ISig_4 112;
BA_ "Platform_VMCU1_Sig" SG_ 2147484573 TrailerABSStatus_ISig_4 1;
BA_ "GenSigCycleTime" SG_ 2147484573 RegenInhibitVehicleHeight_ISig_4 100;
BA_ "GenSigCycleTimeActive" SG_ 2147484573 RegenInhibitVehicleHeight_ISig_4 100;
BA_ "GenSigStartValue" SG_ 2147484573 RegenInhibitVehicleHeight_ISig_4 3;
BA_ "Platform_VMCU1_Sig" SG_ 2147484573 RegenInhibitVehicleHeight_ISig_4 1;
BA_ "GenSigCycleTime" SG_ 2147484573 PoorAirPressureInfo 100;
BA_ "GenSigCycleTimeActive" SG_ 2147484573 PoorAirPressureInfo 100;
BA_ "GenSigStartValue" SG_ 2147484573 PoorAirPressureInfo 3;
BA_ "GenSigMaxLatency" SG_ 2147484573 PoorAirPressureInfo 112;
BA_ "NeedsUpdateBit" SG_ 2147484573 PoorAirPressureInfo 1;
BA_ "Platform_VMCU1_Sig" SG_ 2147484573 PoorAirPressureInfo 1;
BA_ "GenSigCycleTime" SG_ 2147484573 FogLightRearRequest_stat 100;
BA_ "GenSigCycleTimeActive" SG_ 2147484573 FogLightRearRequest_stat 100;
BA_ "GenSigStartValue" SG_ 2147484573 FogLightRearRequest_stat 3;
BA_ "GenSigMaxLatency" SG_ 2147484573 FogLightRearRequest_stat 112;
BA_ "Platform_VMCU1_Sig" SG_ 2147484573 FogLightRearRequest_stat 1;
BA_ "GenSigCycleTime" SG_ 2147484573 MainBeam_cmd_ISig_4 100;
BA_ "GenSigCycleTimeActive" SG_ 2147484573 MainBeam_cmd_ISig_4 100;
BA_ "GenSigStartValue" SG_ 2147484573 MainBeam_cmd_ISig_4 7;
BA_ "Platform_VMCU1_Sig" SG_ 2147484573 MainBeam_cmd_ISig_4 1;
BA_ "SeToolAncestorID_SIGNAL" SG_ 2147484573 MainBeam_cmd_ISig_4 "x0000001D04134EB4";
BA_ "SeToolItemID_SIGNAL" SG_ 2147484573 MainBeam_cmd_ISig_4 "x0000001D04383E5C";
BA_ "SeToolName_SIGNAL" SG_ 2147484573 MainBeam_cmd_ISig_4 "MainBeam_cmd";
BA_ "SeToolVersion_SIGNAL" SG_ 2147484573 MainBeam_cmd_ISig_4 "4";
BA_ "GenSigCycleTime" SG_ 2147484573 FrontParkBrakeOverrideInd_ISig_4 100;
BA_ "GenSigCycleTimeActive" SG_ 2147484573 FrontParkBrakeOverrideInd_ISig_4 100;
BA_ "GenSigStartValue" SG_ 2147484573 FrontParkBrakeOverrideInd_ISig_4 3;
BA_ "GenSigCycleTime" SG_ 2147484497 AuxSwitchBbLoad4_cmd 100;
BA_ "GenSigCycleTimeActive" SG_ 2147484497 AuxSwitchBbLoad4_cmd 100;
BA_ "GenSigStartValue" SG_ 2147484497 AuxSwitchBbLoad4_cmd 3;
BA_ "GenSigMaxLatency" SG_ 2147484497 AuxSwitchBbLoad4_cmd 63;
BA_ "Platform_VMCU1_Sig" SG_ 2147484497 AuxSwitchBbLoad4_cmd 1;
BA_ "GenSigCycleTime" SG_ 2147484497 AuxSwitchBbLoad1_Status_ISig_4 100;
BA_ "GenSigCycleTimeActive" SG_ 2147484497 AuxSwitchBbLoad1_Status_ISig_4 100;
BA_ "GenSigStartValue" SG_ 2147484497 AuxSwitchBbLoad1_Status_ISig_4 3;
BA_ "GenSigMaxLatency" SG_ 2147484497 AuxSwitchBbLoad1_Status_ISig_4 63;
BA_ "Platform_VMCU1_Sig" SG_ 2147484497 AuxSwitchBbLoad1_Status_ISig_4 1;
BA_ "GenSigSendType" SG_ 2147484497 BrakeLightConvoy_rqst_UB_ISig_4 7;
BA_ "Platform_VMCU1_Sig" SG_ 2147484497 BrakeLightConvoy_rqst_UB_ISig_4 1;
BA_ "GenSigCycleTime" SG_ 2147484497 AuxSwitchBbLoad3_cmd 100;
BA_ "GenSigCycleTimeActive" SG_ 2147484497 AuxSwitchBbLoad3_cmd 100;
BA_ "GenSigStartValue" SG_ 2147484497 AuxSwitchBbLoad3_cmd 3;
BA_ "GenSigMaxLatency" SG_ 2147484497 AuxSwitchBbLoad3_cmd 63;
BA_ "Platform_VMCU1_Sig" SG_ 2147484497 AuxSwitchBbLoad3_cmd 1;
BA_ "GenSigCycleTime" SG_ 2147484497 MainBeam_rqst 100;
BA_ "GenSigCycleTimeActive" SG_ 2147484497 MainBeam_rqst 100;
BA_ "GenSigStartValue" SG_ 2147484497 MainBeam_rqst 7;
BA_ "Platform_VMCU1_Sig" SG_ 2147484497 MainBeam_rqst 1;
BA_ "GenSigCycleTime" SG_ 2147484497 BatterySOCTrustLevel_ISig_4 100;
BA_ "GenSigCycleTimeActive" SG_ 2147484497 BatterySOCTrustLevel_ISig_4 100;
BA_ "GenSigStartValue" SG_ 2147484497 BatterySOCTrustLevel_ISig_4 255;
BA_ "Platform_VMCU1_Sig" SG_ 2147484497 BatterySOCTrustLevel_ISig_4 1;
BA_ "GenSigCycleTime" SG_ 2147484497 AuxSwitchBbLoad4_Status_ISig_4 100;
BA_ "GenSigCycleTimeActive" SG_ 2147484497 AuxSwitchBbLoad4_Status_ISig_4 100;
BA_ "GenSigStartValue" SG_ 2147484497 AuxSwitchBbLoad4_Status_ISig_4 3;
BA_ "GenSigMaxLatency" SG_ 2147484497 AuxSwitchBbLoad4_Status_ISig_4 63;
BA_ "Platform_VMCU1_Sig" SG_ 2147484497 AuxSwitchBbLoad4_Status_ISig_4 1;
BA_ "GenSigCycleTime" SG_ 2147484497 BrakeLightConvoy_rqst_ISig_4 100;
BA_ "GenSigCycleTimeActive" SG_ 2147484497 BrakeLightConvoy_rqst_ISig_4 100;
BA_ "GenSigStartValue" SG_ 2147484497 BrakeLightConvoy_rqst_ISig_4 3;
BA_ "NeedsUpdateBit" SG_ 2147484497 BrakeLightConvoy_rqst_ISig_4 1;
BA_ "Platform_VMCU1_Sig" SG_ 2147484497 BrakeLightConvoy_rqst_ISig_4 1;
BA_ "GenSigCycleTime" SG_ 2147484497 DoorWarningLight_cmd_ISig_4 100;
BA_ "GenSigCycleTimeActive" SG_ 2147484497 DoorWarningLight_cmd_ISig_4 100;
BA_ "GenSigStartValue" SG_ 2147484497 DoorWarningLight_cmd_ISig_4 3;
BA_ "Platform_VMCU1_Sig" SG_ 2147484497 DoorWarningLight_cmd_ISig_4 1;
BA_ "GenSigCycleTime" SG_ 2147484497 BlackOutandConvoyMode_rqst_ISig_ 100;
BA_ "GenSigCycleTimeActive" SG_ 2147484497 BlackOutandConvoyMode_rqst_ISig_ 100;
BA_ "GenSigStartValue" SG_ 2147484497 BlackOutandConvoyMode_rqst_ISig_ 7;
BA_ "Platform_VMCU1_Sig" SG_ 2147484497 BlackOutandConvoyMode_rqst_ISig_ 1;
BA_ "SystemSignalLongSymbol" SG_ 2147484497 BlackOutandConvoyMode_rqst_ISig_ "BlackOutandConvoyMode_rqst_ISig_4";
BA_ "GenSigCycleTime" SG_ 2147484497 DirIndicatorRqstLights_stat 100;
BA_ "GenSigCycleTimeActive" SG_ 2147484497 DirIndicatorRqstLights_stat 100;
BA_ "GenSigStartValue" SG_ 2147484497 DirIndicatorRqstLights_stat 7;
BA_ "GenSigMaxLatency" SG_ 2147484497 DirIndicatorRqstLights_stat 63;
BA_ "Platform_VMCU1_Sig" SG_ 2147484497 DirIndicatorRqstLights_stat 1;
BA_ "GenSigCycleTime" SG_ 2147484497 DippedBeamRequest_status 100;
BA_ "GenSigCycleTimeActive" SG_ 2147484497 DippedBeamRequest_status 100;
BA_ "GenSigStartValue" SG_ 2147484497 DippedBeamRequest_status 3;
BA_ "GenSigMaxLatency" SG_ 2147484497 DippedBeamRequest_status 63;
BA_ "Platform_VMCU1_Sig" SG_ 2147484497 DippedBeamRequest_status 1;
BA_ "GenSigCycleTime" SG_ 2147484497 AuxSwitchBbLoad3_Status_ISig_4 100;
BA_ "GenSigCycleTimeActive" SG_ 2147484497 AuxSwitchBbLoad3_Status_ISig_4 100;
BA_ "GenSigStartValue" SG_ 2147484497 AuxSwitchBbLoad3_Status_ISig_4 3;
BA_ "GenSigMaxLatency" SG_ 2147484497 AuxSwitchBbLoad3_Status_ISig_4 63;
BA_ "Platform_VMCU1_Sig" SG_ 2147484497 AuxSwitchBbLoad3_Status_ISig_4 1;
BA_ "GenSigCycleTime" SG_ 2147484497 DoorInstepLight_cmd_ISig_4 100;
BA_ "GenSigCycleTimeActive" SG_ 2147484497 DoorInstepLight_cmd_ISig_4 100;
BA_ "GenSigStartValue" SG_ 2147484497 DoorInstepLight_cmd_ISig_4 3;
BA_ "Platform_VMCU1_Sig" SG_ 2147484497 DoorInstepLight_cmd_ISig_4 1;
BA_ "GenSigCycleTime" SG_ 2147484497 DRLRequest_status 100;
BA_ "GenSigCycleTimeActive" SG_ 2147484497 DRLRequest_status 100;
BA_ "GenSigStartValue" SG_ 2147484497 DRLRequest_status 3;
BA_ "GenSigMaxLatency" SG_ 2147484497 DRLRequest_status 63;
BA_ "Platform_VMCU1_Sig" SG_ 2147484497 DRLRequest_status 1;
BA_ "GenSigCycleTime" SG_ 2147484497 AuxSwitchBbLoad6_Status_ISig_4 100;
BA_ "GenSigCycleTimeActive" SG_ 2147484497 AuxSwitchBbLoad6_Status_ISig_4 100;
BA_ "GenSigStartValue" SG_ 2147484497 AuxSwitchBbLoad6_Status_ISig_4 3;
BA_ "GenSigMaxLatency" SG_ 2147484497 AuxSwitchBbLoad6_Status_ISig_4 63;
BA_ "Platform_VMCU1_Sig" SG_ 2147484497 AuxSwitchBbLoad6_Status_ISig_4 1;
BA_ "GenSigCycleTime" SG_ 2147484497 AuxSwitchBbLoad2_Status_ISig_4 100;
BA_ "GenSigCycleTimeActive" SG_ 2147484497 AuxSwitchBbLoad2_Status_ISig_4 100;
BA_ "GenSigStartValue" SG_ 2147484497 AuxSwitchBbLoad2_Status_ISig_4 3;
BA_ "GenSigMaxLatency" SG_ 2147484497 AuxSwitchBbLoad2_Status_ISig_4 63;
BA_ "Platform_VMCU1_Sig" SG_ 2147484497 AuxSwitchBbLoad2_Status_ISig_4 1;
BA_ "GenSigCycleTime" SG_ 2147484497 AuxSwitchBbLoad5_cmd 100;
BA_ "GenSigCycleTimeActive" SG_ 2147484497 AuxSwitchBbLoad5_cmd 100;
BA_ "GenSigStartValue" SG_ 2147484497 AuxSwitchBbLoad5_cmd 3;
BA_ "GenSigMaxLatency" SG_ 2147484497 AuxSwitchBbLoad5_cmd 63;
BA_ "Platform_VMCU1_Sig" SG_ 2147484497 AuxSwitchBbLoad5_cmd 1;
BA_ "GenSigCycleTime" SG_ 2147484497 PBReleaseInhibit_EPBState_ISig_4 100;
BA_ "GenSigCycleTimeActive" SG_ 2147484497 PBReleaseInhibit_EPBState_ISig_4 100;
BA_ "GenSigStartValue" SG_ 2147484497 PBReleaseInhibit_EPBState_ISig_4 7;
BA_ "Platform_VMCU1_Sig" SG_ 2147484497 PBReleaseInhibit_EPBState_ISig_4 1;
BA_ "GenSigCycleTime" SG_ 2147484497 ExtStaticTrailerBrake_Stat_ISig_ 100;
BA_ "GenSigCycleTimeActive" SG_ 2147484497 ExtStaticTrailerBrake_Stat_ISig_ 100;
BA_ "GenSigStartValue" SG_ 2147484497 ExtStaticTrailerBrake_Stat_ISig_ 3;
BA_ "Platform_VMCU1_Sig" SG_ 2147484497 ExtStaticTrailerBrake_Stat_ISig_ 1;
BA_ "SystemSignalLongSymbol" SG_ 2147484497 ExtStaticTrailerBrake_Stat_ISig_ "ExtStaticTrailerBrake_Stat_ISig_4";
BA_ "GenSigCycleTime" SG_ 2147484497 AuxSwitchBbLoad5_Status_ISig_4 100;
BA_ "GenSigCycleTimeActive" SG_ 2147484497 AuxSwitchBbLoad5_Status_ISig_4 100;
BA_ "GenSigStartValue" SG_ 2147484497 AuxSwitchBbLoad5_Status_ISig_4 3;
BA_ "GenSigMaxLatency" SG_ 2147484497 AuxSwitchBbLoad5_Status_ISig_4 63;
BA_ "Platform_VMCU1_Sig" SG_ 2147484497 AuxSwitchBbLoad5_Status_ISig_4 1;
BA_ "GenSigCycleTime" SG_ 2147484497 DoubleFrontAxleSteeringWarning_I 100;
BA_ "GenSigCycleTimeActive" SG_ 2147484497 DoubleFrontAxleSteeringWarning_I 100;
BA_ "GenSigStartValue" SG_ 2147484497 DoubleFrontAxleSteeringWarning_I 3;
BA_ "SystemSignalLongSymbol" SG_ 2147484497 DoubleFrontAxleSteeringWarning_I "DoubleFrontAxleSteeringWarning_ISig_4";
BA_ "GenSigCycleTime" SG_ 2147484497 AuxSwitchBbLoad6_cmd 100;
BA_ "GenSigCycleTimeActive" SG_ 2147484497 AuxSwitchBbLoad6_cmd 100;
BA_ "GenSigStartValue" SG_ 2147484497 AuxSwitchBbLoad6_cmd 3;
BA_ "GenSigMaxLatency" SG_ 2147484497 AuxSwitchBbLoad6_cmd 63;
BA_ "Platform_VMCU1_Sig" SG_ 2147484497 AuxSwitchBbLoad6_cmd 1;
BA_ "GenSigCycleTime" SG_ 2147484497 AcceleratorPedalTestStatus 100;
BA_ "GenSigCycleTimeActive" SG_ 2147484497 AcceleratorPedalTestStatus 100;
BA_ "GenSigStartValue" SG_ 2147484497 AcceleratorPedalTestStatus 7;
BA_REL_ "GenSigFirstTimeoutTime" BU_SG_REL_ IC3 SG_ 2147484719 EcoCruiseSetSpeed 3600;
BA_REL_ "GenSigTimeoutTime" BU_SG_REL_ IC3 SG_ 2147484719 EcoCruiseSetSpeed 900;
BA_REL_ "GenSigFirstTimeoutTime" BU_SG_REL_ BBM SG_ 2147484719 Alcolock_stat_ISig_4 3600;
BA_REL_ "GenSigTimeoutTime" BU_SG_REL_ BBM SG_ 2147484719 Alcolock_stat_ISig_4 900;
BA_REL_ "GenSigFirstTimeoutTime" BU_SG_REL_ IC3 SG_ 2147484719 CTA_PBReleaseInhibit_ind 3000;
BA_REL_ "GenSigTimeoutTime" BU_SG_REL_ IC3 SG_ 2147484719 CTA_PBReleaseInhibit_ind 900;
BA_REL_ "GenSigFirstTimeoutTime" BU_SG_REL_ BBM SG_ 2147484719 CTA_PBReleaseInhibit_ind 3600;
BA_REL_ "GenSigTimeoutTime" BU_SG_REL_ BBM SG_ 2147484719 CTA_PBReleaseInhibit_ind 900;
BA_REL_ "GenSigFirstTimeoutTime" BU_SG_REL_ EMS SG_ 2147484719 EngOvrrideCtrlStat_FireTruckMode 3000;
BA_REL_ "GenSigTimeoutTime" BU_SG_REL_ EMS SG_ 2147484719 EngOvrrideCtrlStat_FireTruckMode 600;
BA_REL_ "GenSigFirstTimeoutTime" BU_SG_REL_ IC3 SG_ 2147484719 DHCActualSetSpeed 3000;
BA_REL_ "GenSigTimeoutTime" BU_SG_REL_ IC3 SG_ 2147484719 DHCActualSetSpeed 900;
BA_REL_ "GenSigFirstTimeoutTime" BU_SG_REL_ EMS SG_ 2147484719 EngOvrrideCtrlStat_StartOvrrMode 3000;
BA_REL_ "GenSigTimeoutTime" BU_SG_REL_ EMS SG_ 2147484719 EngOvrrideCtrlStat_StartOvrrMode 600;
BA_REL_ "GenSigFirstTimeoutTime" BU_SG_REL_ EMS SG_ 2147484719 EngOvrrideCtrlStat_ProtOvrrMode 3000;
BA_REL_ "GenSigTimeoutTime" BU_SG_REL_ EMS SG_ 2147484719 EngOvrrideCtrlStat_ProtOvrrMode 600;
BA_REL_ "GenSigFirstTimeoutTime" BU_SG_REL_ TECU SG_ 2147484719 XRSLBTargetSpeedRequest 3600;
BA_REL_ "GenSigTimeoutTime" BU_SG_REL_ TECU SG_ 2147484719 XRSLBTargetSpeedRequest 900;
BA_REL_ "GenSigFirstTimeoutTime" BU_SG_REL_ EMS SG_ 2147484719 XRSLBTargetSpeedRequest 3000;
BA_REL_ "GenSigTimeoutTime" BU_SG_REL_ EMS SG_ 2147484719 XRSLBTargetSpeedRequest 600;
BA_REL_ "GenSigFirstTimeoutTime" BU_SG_REL_ IC3 SG_ 2147484716 EcoCruiseMinSpeedLev3 3600;
BA_REL_ "GenSigTimeoutTime" BU_SG_REL_ IC3 SG_ 2147484716 EcoCruiseMinSpeedLev3 900;
BA_REL_ "GenSigFirstTimeoutTime" BU_SG_REL_ IC3 SG_ 2147484716 EcoCruiseMinSpeedLev0 3600;
BA_REL_ "GenSigTimeoutTime" BU_SG_REL_ IC3 SG_ 2147484716 EcoCruiseMinSpeedLev0 900;
BA_REL_ "GenSigFirstTimeoutTime" BU_SG_REL_ IC3 SG_ 2147484716 EcoCruiseMinSpeedLev1 3600;
BA_REL_ "GenSigTimeoutTime" BU_SG_REL_ IC3 SG_ 2147484716 EcoCruiseMinSpeedLev1 900;
BA_REL_ "GenSigFirstTimeoutTime" BU_SG_REL_ IC3 SG_ 2147484716 EcoCruiseMinSpeedLev2 3600;
BA_REL_ "GenSigTimeoutTime" BU_SG_REL_ IC3 SG_ 2147484716 EcoCruiseMinSpeedLev2 900;
BA_REL_ "GenSigFirstTimeoutTime" BU_SG_REL_ IC3 SG_ 2147484713 EcoCruiseMaxSpeedLev1 3600;
BA_REL_ "GenSigTimeoutTime" BU_SG_REL_ IC3 SG_ 2147484713 EcoCruiseMaxSpeedLev1 900;
BA_REL_ "GenSigFirstTimeoutTime" BU_SG_REL_ IC3 SG_ 2147484713 EcoCruiseMaxSpeedLev0 3600;
BA_REL_ "GenSigTimeoutTime" BU_SG_REL_ IC3 SG_ 2147484713 EcoCruiseMaxSpeedLev0 900;
BA_REL_ "GenSigFirstTimeoutTime" BU_SG_REL_ IC3 SG_ 2147484713 EcoCruiseMaxSpeedLev2 3600;
BA_REL_ "GenSigTimeoutTime" BU_SG_REL_ IC3 SG_ 2147484713 EcoCruiseMaxSpeedLev2 900;
BA_REL_ "GenSigFirstTimeoutTime" BU_SG_REL_ IC3 SG_ 2147484713 EcoCruiseMaxSpeedLev3 3600;
BA_REL_ "GenSigTimeoutTime" BU_SG_REL_ IC3 SG_ 2147484713 EcoCruiseMaxSpeedLev3 900;
BA_REL_ "GenSigFirstTimeoutTime" BU_SG_REL_ IC3 SG_ 2147484710 EcoCruiseCCBSetSpeedLev2 3600;
BA_REL_ "GenSigTimeoutTime" BU_SG_REL_ IC3 SG_ 2147484710 EcoCruiseCCBSetSpeedLev2 900;
BA_REL_ "GenSigFirstTimeoutTime" BU_SG_REL_ IC3 SG_ 2147484710 EcoCruiseCCBSetSpeedLev1 3600;
BA_REL_ "GenSigTimeoutTime" BU_SG_REL_ IC3 SG_ 2147484710 EcoCruiseCCBSetSpeedLev1 900;
BA_REL_ "GenSigFirstTimeoutTime" BU_SG_REL_ IC3 SG_ 2147484710 EcoCruiseCCBSetSpeedLev3 3600;
BA_REL_ "GenSigTimeoutTime" BU_SG_REL_ IC3 SG_ 2147484710 EcoCruiseCCBSetSpeedLev3 900;
BA_REL_ "GenSigFirstTimeoutTime" BU_SG_REL_ IC3 SG_ 2147484710 EcoCruiseCCBSetSpeedLev0 3600;
BA_REL_ "GenSigTimeoutTime" BU_SG_REL_ IC3 SG_ 2147484710 EcoCruiseCCBSetSpeedLev0 900;
BA_REL_ "GenSigFirstTimeoutTime" BU_SG_REL_ IC3 SG_ 2147485052 EngineGreenAreaOutLNG_ISig_4 24000;
BA_REL_ "GenSigTimeoutTime" BU_SG_REL_ IC3 SG_ 2147485052 EngineGreenAreaOutLNG_ISig_4 6000;
BA_REL_ "GenSigFirstTimeoutTime" BU_SG_REL_ IC3 SG_ 2147485052 EngineGreenAreaLNG_ISig_4 24000;
BA_REL_ "GenSigTimeoutTime" BU_SG_REL_ IC3 SG_ 2147485052 EngineGreenAreaLNG_ISig_4 6000;
BA_REL_ "GenSigFirstTimeoutTime" BU_SG_REL_ IC3 SG_ 2147484683 BatteryTempAlert_rqst_ISig_4 3000;
BA_REL_ "GenSigTimeoutTime" BU_SG_REL_ IC3 SG_ 2147484683 BatteryTempAlert_rqst_ISig_4 600;
BA_REL_ "GenSigFirstTimeoutTime" BU_SG_REL_ IC3 SG_ 2147484683 APM_TrailerCircPressureStatus_IS 3000;
BA_REL_ "GenSigTimeoutTime" BU_SG_REL_ IC3 SG_ 2147484683 APM_TrailerCircPressureStatus_IS 600;
BA_REL_ "GenSigFirstTimeoutTime" BU_SG_REL_ IC3 SG_ 2147484683 BatteryCapacity_ISig_4 3000;
BA_REL_ "GenSigTimeoutTime" BU_SG_REL_ IC3 SG_ 2147484683 BatteryCapacity_ISig_4 600;
BA_REL_ "GenSigFirstTimeoutTime" BU_SG_REL_ IC3 SG_ 2147484683 Hazard_rqst_ISig_4 3000;
BA_REL_ "GenSigTimeoutTime" BU_SG_REL_ IC3 SG_ 2147484683 Hazard_rqst_ISig_4 600;
BA_REL_ "GenSigFirstTimeoutTime" BU_SG_REL_ DACU SG_ 2147484683 CollisionSituationAliveStatus 3000;
BA_REL_ "GenSigTimeoutTime" BU_SG_REL_ DACU SG_ 2147484683 CollisionSituationAliveStatus 600;
BA_REL_ "GenSigFirstTimeoutTime" BU_SG_REL_ IC3 SG_ 2147484683 BatterySOCact_ISig_4 3000;
BA_REL_ "GenSigTimeoutTime" BU_SG_REL_ IC3 SG_ 2147484683 BatterySOCact_ISig_4 600;
BA_REL_ "GenSigFirstTimeoutTime" BU_SG_REL_ IC3 SG_ 2147484683 Trailer1TPMLostCom_ISig_4 4800;
BA_REL_ "GenSigTimeoutTime" BU_SG_REL_ IC3 SG_ 2147484683 Trailer1TPMLostCom_ISig_4 1200;
BA_REL_ "GenSigFirstTimeoutTime" BU_SG_REL_ IC3 SG_ 2147484683 BatterySOCactCriticalAlert_ISig_ 3000;
BA_REL_ "GenSigTimeoutTime" BU_SG_REL_ IC3 SG_ 2147484683 BatterySOCactCriticalAlert_ISig_ 600;
BA_REL_ "GenSigFirstTimeoutTime" BU_SG_REL_ IC3 SG_ 2147484683 BatteryTempAlertRawData_rqst_ISi 3000;
BA_REL_ "GenSigTimeoutTime" BU_SG_REL_ IC3 SG_ 2147484683 BatteryTempAlertRawData_rqst_ISi 600;
BA_REL_ "GenSigFirstTimeoutTime" BU_SG_REL_ CIOM SG_ 2147484683 FPBRMMIStat_FPBRChangeAck_ISig_4 3000;
BA_REL_ "GenSigTimeoutTime" BU_SG_REL_ CIOM SG_ 2147484683 FPBRMMIStat_FPBRChangeAck_ISig_4 600;
BA_REL_ "GenSigFirstTimeoutTime" BU_SG_REL_ CIOM SG_ 2147484683 LivBatteryCharging_stat_ISig_4 3000;
BA_REL_ "GenSigTimeoutTime" BU_SG_REL_ CIOM SG_ 2147484683 LivBatteryCharging_stat_ISig_4 600;
BA_REL_ "GenSigFirstTimeoutTime" BU_SG_REL_ IC3 SG_ 2147484683 LivBatteryCharging_stat_ISig_4 3000;
BA_REL_ "GenSigTimeoutTime" BU_SG_REL_ IC3 SG_ 2147484683 LivBatteryCharging_stat_ISig_4 600;
BA_REL_ "GenSigFirstTimeoutTime" BU_SG_REL_ IC3 SG_ 2147484683 BatteryTemp_ISig_4 3000;
BA_REL_ "GenSigTimeoutTime" BU_SG_REL_ IC3 SG_ 2147484683 BatteryTemp_ISig_4 600;
BA_REL_ "GenSigFirstTimeoutTime" BU_SG_REL_ CIOM SG_ 2147484683 FPBRMMIStat_FPBRStatusInd_ISig_4 3000;
BA_REL_ "GenSigTimeoutTime" BU_SG_REL_ CIOM SG_ 2147484683 FPBRMMIStat_FPBRStatusInd_ISig_4 600;
BA_REL_ "GenSigFirstTimeoutTime" BU_SG_REL_ IC3 SG_ 2147484683 Trailer2TPMLostCom_ISig_4 4800;
BA_REL_ "GenSigTimeoutTime" BU_SG_REL_ IC3 SG_ 2147484683 Trailer2TPMLostCom_ISig_4 1200;
BA_REL_ "GenSigFirstTimeoutTime" BU_SG_REL_ DACU SG_ 2147484683 CollisionSituationAliveRequest 3000;
BA_REL_ "GenSigTimeoutTime" BU_SG_REL_ DACU SG_ 2147484683 CollisionSituationAliveRequest 600;
BA_REL_ "GenSigFirstTimeoutTime" BU_SG_REL_ IC3 SG_ 2147484680 TPMMateTrailerResp_ISig_4 3000;
BA_REL_ "GenSigTimeoutTime" BU_SG_REL_ IC3 SG_ 2147484680 TPMMateTrailerResp_ISig_4 600;
BA_REL_ "GenSigFirstTimeoutTime" BU_SG_REL_ IC3 SG_ 2147484680 Trailer2TPMLeakageWarning_ISig_4 3000;
BA_REL_ "GenSigTimeoutTime" BU_SG_REL_ IC3 SG_ 2147484680 Trailer2TPMLeakageWarning_ISig_4 600;
BA_REL_ "GenSigFirstTimeoutTime" BU_SG_REL_ IC3 SG_ 2147484680 TPMAutomaticMating_ISig_4 3000;
BA_REL_ "GenSigTimeoutTime" BU_SG_REL_ IC3 SG_ 2147484680 TPMAutomaticMating_ISig_4 600;
BA_REL_ "GenSigFirstTimeoutTime" BU_SG_REL_ IC3 SG_ 2147484680 Trailer2TPMMatedStatus_ISig_4 3000;
BA_REL_ "GenSigTimeoutTime" BU_SG_REL_ IC3 SG_ 2147484680 Trailer2TPMMatedStatus_ISig_4 600;
BA_REL_ "GenSigFirstTimeoutTime" BU_SG_REL_ IC3 SG_ 2147484680 Trailer1TPMMatedStatus_ISig_4 3000;
BA_REL_ "GenSigTimeoutTime" BU_SG_REL_ IC3 SG_ 2147484680 Trailer1TPMMatedStatus_ISig_4 600;
BA_REL_ "GenSigFirstTimeoutTime" BU_SG_REL_ IC3 SG_ 2147484680 TruckTPMLeakageWarning_ISig_4 3000;
BA_REL_ "GenSigTimeoutTime" BU_SG_REL_ IC3 SG_ 2147484680 TruckTPMLeakageWarning_ISig_4 600;
BA_REL_ "GenSigFirstTimeoutTime" BU_SG_REL_ CIOM SG_ 2147484680 ExtraSideMarkers_FunctStat 3000;
BA_REL_ "GenSigTimeoutTime" BU_SG_REL_ CIOM SG_ 2147484680 ExtraSideMarkers_FunctStat 600;
BA_REL_ "GenSigFirstTimeoutTime" BU_SG_REL_ IC3 SG_ 2147484680 Trailer2TPMPressureWarning_ISig_ 3000;
BA_REL_ "GenSigTimeoutTime" BU_SG_REL_ IC3 SG_ 2147484680 Trailer2TPMPressureWarning_ISig_ 600;
BA_REL_ "GenSigFirstTimeoutTime" BU_SG_REL_ IC3 SG_ 2147484680 Trailer1TPMPressureWarning_ISig_ 3000;
BA_REL_ "GenSigTimeoutTime" BU_SG_REL_ IC3 SG_ 2147484680 Trailer1TPMPressureWarning_ISig_ 600;
BA_REL_ "GenSigFirstTimeoutTime" BU_SG_REL_ IC3 SG_ 2147484680 Trailer1TPMLeakageWarning_ISig_4 3000;
BA_REL_ "GenSigTimeoutTime" BU_SG_REL_ IC3 SG_ 2147484680 Trailer1TPMLeakageWarning_ISig_4 600;
BA_REL_ "GenSigFirstTimeoutTime" BU_SG_REL_ IC3 SG_ 2147484680 LiftAxle1RequestResponse 3000;
BA_REL_ "GenSigTimeoutTime" BU_SG_REL_ IC3 SG_ 2147484680 LiftAxle1RequestResponse 600;
BA_REL_ "GenSigFirstTimeoutTime" BU_SG_REL_ IC3 SG_ 2147484680 TruckTPMPressureWarning_ISig_4 3000;
BA_REL_ "GenSigTimeoutTime" BU_SG_REL_ IC3 SG_ 2147484680 TruckTPMPressureWarning_ISig_4 600;
BA_REL_ "GenSigFirstTimeoutTime" BU_SG_REL_ BBM SG_ 2147484680 XRSLIndication 3000;
BA_REL_ "GenSigTimeoutTime" BU_SG_REL_ BBM SG_ 2147484680 XRSLIndication 600;
BA_REL_ "GenSigFirstTimeoutTime" BU_SG_REL_ IC3 SG_ 2147484680 XRSLIndication 3000;
BA_REL_ "GenSigTimeoutTime" BU_SG_REL_ IC3 SG_ 2147484680 XRSLIndication 600;
BA_REL_ "GenSigFirstTimeoutTime" BU_SG_REL_ IC3 SG_ 2147484885 Trailer2TPMFailure_ISig_4 4800;
BA_REL_ "GenSigTimeoutTime" BU_SG_REL_ IC3 SG_ 2147484885 Trailer2TPMFailure_ISig_4 1200;
BA_REL_ "GenSigFirstTimeoutTime" BU_SG_REL_ IC3 SG_ 2147484885 TruckTPMTireInfo_Active_ISig_4 4800;
BA_REL_ "GenSigTimeoutTime" BU_SG_REL_ IC3 SG_ 2147484885 TruckTPMTireInfo_Active_ISig_4 1200;
BA_REL_ "GenSigFirstTimeoutTime" BU_SG_REL_ IC3 SG_ 2147484885 TruckTPMFailure_ISig_4 4800;
BA_REL_ "GenSigTimeoutTime" BU_SG_REL_ IC3 SG_ 2147484885 TruckTPMFailure_ISig_4 1200;
BA_REL_ "GenSigFirstTimeoutTime" BU_SG_REL_ IC3 SG_ 2147484885 TruckTPMTireInfo_TireId_ISig_4 4800;
BA_REL_ "GenSigTimeoutTime" BU_SG_REL_ IC3 SG_ 2147484885 TruckTPMTireInfo_TireId_ISig_4 1200;
BA_REL_ "GenSigFirstTimeoutTime" BU_SG_REL_ IC3 SG_ 2147484885 TruckTPMTireInfo_Battery_ISig_4 4800;
BA_REL_ "GenSigTimeoutTime" BU_SG_REL_ IC3 SG_ 2147484885 TruckTPMTireInfo_Battery_ISig_4 1200;
BA_REL_ "GenSigFirstTimeoutTime" BU_SG_REL_ IC3 SG_ 2147484885 TruckTPMTireInfo_Temperature_ISi 4800;
BA_REL_ "GenSigTimeoutTime" BU_SG_REL_ IC3 SG_ 2147484885 TruckTPMTireInfo_Temperature_ISi 1200;
BA_REL_ "GenSigFirstTimeoutTime" BU_SG_REL_ IC3 SG_ 2147484885 TruckTPMTireInfo_RefPres_ISig_4 4800;
BA_REL_ "GenSigTimeoutTime" BU_SG_REL_ IC3 SG_ 2147484885 TruckTPMTireInfo_RefPres_ISig_4 1200;
BA_REL_ "GenSigFirstTimeoutTime" BU_SG_REL_ IC3 SG_ 2147484885 TPMTrailerPositionStat_ISig_4 4800;
BA_REL_ "GenSigTimeoutTime" BU_SG_REL_ IC3 SG_ 2147484885 TPMTrailerPositionStat_ISig_4 1200;
BA_REL_ "GenSigFirstTimeoutTime" BU_SG_REL_ IC3 SG_ 2147484885 TruckTPMTireInfo_Pressure_ISig_4 4800;
BA_REL_ "GenSigTimeoutTime" BU_SG_REL_ IC3 SG_ 2147484885 TruckTPMTireInfo_Pressure_ISig_4 1200;
BA_REL_ "GenSigFirstTimeoutTime" BU_SG_REL_ IC3 SG_ 2147484885 Trailer1TPMFailure_ISig_4 4800;
BA_REL_ "GenSigTimeoutTime" BU_SG_REL_ IC3 SG_ 2147484885 Trailer1TPMFailure_ISig_4 1200;
BA_REL_ "GenSigFirstTimeoutTime" BU_SG_REL_ IC3 SG_ 2147484885 TruckTPMTireInfo_PresWarn_ISig_4 4800;
BA_REL_ "GenSigTimeoutTime" BU_SG_REL_ IC3 SG_ 2147484885 TruckTPMTireInfo_PresWarn_ISig_4 1200;
BA_REL_ "GenSigFirstTimeoutTime" BU_SG_REL_ IC3 SG_ 2147484885 TruckTPMTireInfo_LeakageWarn_ISi 4800;
BA_REL_ "GenSigTimeoutTime" BU_SG_REL_ IC3 SG_ 2147484885 TruckTPMTireInfo_LeakageWarn_ISi 1200;
BA_REL_ "GenSigFirstTimeoutTime" BU_SG_REL_ IC3 SG_ 2147484882 Trailer2TPMTireInfo_LeakageWarn_ 4800;
BA_REL_ "GenSigTimeoutTime" BU_SG_REL_ IC3 SG_ 2147484882 Trailer2TPMTireInfo_LeakageWarn_ 1200;
BA_REL_ "GenSigFirstTimeoutTime" BU_SG_REL_ IC3 SG_ 2147484882 Trailer2TPMTireInfo_RefPres_ISig 4800;
BA_REL_ "GenSigTimeoutTime" BU_SG_REL_ IC3 SG_ 2147484882 Trailer2TPMTireInfo_RefPres_ISig 1200;
BA_REL_ "GenSigFirstTimeoutTime" BU_SG_REL_ IC3 SG_ 2147484882 Trailer2TPMTireInfo_PresWarn_ISi 4800;
BA_REL_ "GenSigTimeoutTime" BU_SG_REL_ IC3 SG_ 2147484882 Trailer2TPMTireInfo_PresWarn_ISi 1200;
BA_REL_ "GenSigFirstTimeoutTime" BU_SG_REL_ IC3 SG_ 2147484882 Trailer2TPMTireInfo_Pressure_ISi 4800;
BA_REL_ "GenSigTimeoutTime" BU_SG_REL_ IC3 SG_ 2147484882 Trailer2TPMTireInfo_Pressure_ISi 1200;
BA_REL_ "GenSigFirstTimeoutTime" BU_SG_REL_ IC3 SG_ 2147484882 Trailer2TPMTireInfo_Temperature_ 4800;
BA_REL_ "GenSigTimeoutTime" BU_SG_REL_ IC3 SG_ 2147484882 Trailer2TPMTireInfo_Temperature_ 1200;
BA_REL_ "GenSigFirstTimeoutTime" BU_SG_REL_ IC3 SG_ 2147484882 Trailer2TPMTireInfo_TireId_ISig_ 4800;
BA_REL_ "GenSigTimeoutTime" BU_SG_REL_ IC3 SG_ 2147484882 Trailer2TPMTireInfo_TireId_ISig_ 1200;
BA_REL_ "GenSigFirstTimeoutTime" BU_SG_REL_ IC3 SG_ 2147484882 Trailer2TPMTireInfo_Battery_ISig 4800;
BA_REL_ "GenSigTimeoutTime" BU_SG_REL_ IC3 SG_ 2147484882 Trailer2TPMTireInfo_Battery_ISig 1200;
BA_REL_ "GenSigFirstTimeoutTime" BU_SG_REL_ IC3 SG_ 2147484882 Trailer2TPMTireInfo_Active_ISig_ 4800;
BA_REL_ "GenSigTimeoutTime" BU_SG_REL_ IC3 SG_ 2147484882 Trailer2TPMTireInfo_Active_ISig_ 1200;
BA_REL_ "GenSigFirstTimeoutTime" BU_SG_REL_ IC3 SG_ 2147484879 Trailer1TPMTireInfo_Battery_ISig 4800;
BA_REL_ "GenSigTimeoutTime" BU_SG_REL_ IC3 SG_ 2147484879 Trailer1TPMTireInfo_Battery_ISig 1200;
BA_REL_ "GenSigFirstTimeoutTime" BU_SG_REL_ IC3 SG_ 2147484879 Trailer1TPMTireInfo_Pressure_ISi 4800;
BA_REL_ "GenSigTimeoutTime" BU_SG_REL_ IC3 SG_ 2147484879 Trailer1TPMTireInfo_Pressure_ISi 1200;
BA_REL_ "GenSigFirstTimeoutTime" BU_SG_REL_ IC3 SG_ 2147484879 Trailer1TPMTireInfo_PresWarn_ISi 4800;
BA_REL_ "GenSigTimeoutTime" BU_SG_REL_ IC3 SG_ 2147484879 Trailer1TPMTireInfo_PresWarn_ISi 1200;
BA_REL_ "GenSigFirstTimeoutTime" BU_SG_REL_ IC3 SG_ 2147484879 Trailer1TPMTireInfo_LeakageWarn_ 4800;
BA_REL_ "GenSigTimeoutTime" BU_SG_REL_ IC3 SG_ 2147484879 Trailer1TPMTireInfo_LeakageWarn_ 1200;
BA_REL_ "GenSigFirstTimeoutTime" BU_SG_REL_ IC3 SG_ 2147484879 TPMPosOfWMResp_VehiclePos_ISig_4 4800;
BA_REL_ "GenSigTimeoutTime" BU_SG_REL_ IC3 SG_ 2147484879 TPMPosOfWMResp_VehiclePos_ISig_4 1200;
BA_REL_ "GenSigFirstTimeoutTime" BU_SG_REL_ IC3 SG_ 2147484879 Trailer1TPMTireInfo_TireId_ISig_ 4800;
BA_REL_ "GenSigTimeoutTime" BU_SG_REL_ IC3 SG_ 2147484879 Trailer1TPMTireInfo_TireId_ISig_ 1200;
BA_REL_ "GenSigFirstTimeoutTime" BU_SG_REL_ IC3 SG_ 2147484879 Trailer1TPMTireInfo_RefPres_ISig 4800;
BA_REL_ "GenSigTimeoutTime" BU_SG_REL_ IC3 SG_ 2147484879 Trailer1TPMTireInfo_RefPres_ISig 1200;
BA_REL_ "GenSigFirstTimeoutTime" BU_SG_REL_ IC3 SG_ 2147484879 Trailer1TPMTireInfo_Temperature_ 4800;
BA_REL_ "GenSigTimeoutTime" BU_SG_REL_ IC3 SG_ 2147484879 Trailer1TPMTireInfo_Temperature_ 1200;
BA_REL_ "GenSigFirstTimeoutTime" BU_SG_REL_ IC3 SG_ 2147484879 Trailer1TPMTireInfo_Active_ISig_ 4800;
BA_REL_ "GenSigTimeoutTime" BU_SG_REL_ IC3 SG_ 2147484879 Trailer1TPMTireInfo_Active_ISig_ 1200;
BA_REL_ "GenSigFirstTimeoutTime" BU_SG_REL_ IC3 SG_ 2147484879 TPMPosOfWMResp_Status_ISig_4 4800;
BA_REL_ "GenSigTimeoutTime" BU_SG_REL_ IC3 SG_ 2147484879 TPMPosOfWMResp_Status_ISig_4 1200;
BA_REL_ "GenSigFirstTimeoutTime" BU_SG_REL_ IC3 SG_ 2147484879 TPMPosOfWMResp_TireId_ISig_4 4800;
BA_REL_ "GenSigTimeoutTime" BU_SG_REL_ IC3 SG_ 2147484879 TPMPosOfWMResp_TireId_ISig_4 1200;
BA_REL_ "GenSigFirstTimeoutTime" BU_SG_REL_ IC3 SG_ 2147485051 TruckTPMThresCfg_OverPres_ISig_4 24000;
BA_REL_ "GenSigTimeoutTime" BU_SG_REL_ IC3 SG_ 2147485051 TruckTPMThresCfg_OverPres_ISig_4 6000;
BA_REL_ "GenSigFirstTimeoutTime" BU_SG_REL_ IC3 SG_ 2147485051 TruckTPMAxlTireCfg_Axle2_ISig_4 24000;
BA_REL_ "GenSigTimeoutTime" BU_SG_REL_ IC3 SG_ 2147485051 TruckTPMAxlTireCfg_Axle2_ISig_4 6000;
BA_REL_ "GenSigFirstTimeoutTime" BU_SG_REL_ IC3 SG_ 2147485051 TruckTPMAxlTireCfg_Axle1_ISig_4 24000;
BA_REL_ "GenSigTimeoutTime" BU_SG_REL_ IC3 SG_ 2147485051 TruckTPMAxlTireCfg_Axle1_ISig_4 6000;
BA_REL_ "GenSigFirstTimeoutTime" BU_SG_REL_ IC3 SG_ 2147485051 TruckTPMAxlTireCfg_Axle5_ISig_4 24000;
BA_REL_ "GenSigTimeoutTime" BU_SG_REL_ IC3 SG_ 2147485051 TruckTPMAxlTireCfg_Axle5_ISig_4 6000;
BA_REL_ "GenSigFirstTimeoutTime" BU_SG_REL_ IC3 SG_ 2147485051 TruckTPMAxlTireCfg_Axle4_ISig_4 24000;
BA_REL_ "GenSigTimeoutTime" BU_SG_REL_ IC3 SG_ 2147485051 TruckTPMAxlTireCfg_Axle4_ISig_4 6000;
BA_REL_ "GenSigFirstTimeoutTime" BU_SG_REL_ IC3 SG_ 2147485051 TruckTPMThresCfg_ExtUnderPres_IS 24000;
BA_REL_ "GenSigTimeoutTime" BU_SG_REL_ IC3 SG_ 2147485051 TruckTPMThresCfg_ExtUnderPres_IS 6000;
BA_REL_ "GenSigFirstTimeoutTime" BU_SG_REL_ IC3 SG_ 2147485051 TruckTPMThresCfg_AxleNr_ISig_4 24000;
BA_REL_ "GenSigTimeoutTime" BU_SG_REL_ IC3 SG_ 2147485051 TruckTPMThresCfg_AxleNr_ISig_4 6000;
BA_REL_ "GenSigFirstTimeoutTime" BU_SG_REL_ IC3 SG_ 2147485051 TruckTPMThresCfg_UnderPres_ISig_ 24000;
BA_REL_ "GenSigTimeoutTime" BU_SG_REL_ IC3 SG_ 2147485051 TruckTPMThresCfg_UnderPres_ISig_ 6000;
BA_REL_ "GenSigFirstTimeoutTime" BU_SG_REL_ IC3 SG_ 2147485051 TruckTPMThresCfg_ExtOverPres_ISi 24000;
BA_REL_ "GenSigTimeoutTime" BU_SG_REL_ IC3 SG_ 2147485051 TruckTPMThresCfg_ExtOverPres_ISi 6000;
BA_REL_ "GenSigFirstTimeoutTime" BU_SG_REL_ IC3 SG_ 2147485051 TruckTPMAxlTireCfg_Axle3_ISig_4 24000;
BA_REL_ "GenSigTimeoutTime" BU_SG_REL_ IC3 SG_ 2147485051 TruckTPMAxlTireCfg_Axle3_ISig_4 6000;
BA_REL_ "GenSigFirstTimeoutTime" BU_SG_REL_ IC3 SG_ 2147485050 Trailer2TPMType_ISig_4 24000;
BA_REL_ "GenSigTimeoutTime" BU_SG_REL_ IC3 SG_ 2147485050 Trailer2TPMType_ISig_4 6000;
BA_REL_ "GenSigFirstTimeoutTime" BU_SG_REL_ IC3 SG_ 2147485050 Trailer2TPMAxlTireCfg_Axle1_ISig 24000;
BA_REL_ "GenSigTimeoutTime" BU_SG_REL_ IC3 SG_ 2147485050 Trailer2TPMAxlTireCfg_Axle1_ISig 6000;
BA_REL_ "GenSigFirstTimeoutTime" BU_SG_REL_ IC3 SG_ 2147485050 Trailer2TPMThresCfg_OverPres_ISi 24000;
BA_REL_ "GenSigTimeoutTime" BU_SG_REL_ IC3 SG_ 2147485050 Trailer2TPMThresCfg_OverPres_ISi 6000;
BA_REL_ "GenSigFirstTimeoutTime" BU_SG_REL_ IC3 SG_ 2147485050 Trailer2TPMAxlTireCfg_Axle3_ISig 24000;
BA_REL_ "GenSigTimeoutTime" BU_SG_REL_ IC3 SG_ 2147485050 Trailer2TPMAxlTireCfg_Axle3_ISig 6000;
BA_REL_ "GenSigFirstTimeoutTime" BU_SG_REL_ IC3 SG_ 2147485050 Trailer2TPMAxlTireCfg_Axle2_ISig 24000;
BA_REL_ "GenSigTimeoutTime" BU_SG_REL_ IC3 SG_ 2147485050 Trailer2TPMAxlTireCfg_Axle2_ISig 6000;
BA_REL_ "GenSigFirstTimeoutTime" BU_SG_REL_ IC3 SG_ 2147485050 Trailer2TPMAxlTireCfg_Axle5_ISig 24000;
BA_REL_ "GenSigTimeoutTime" BU_SG_REL_ IC3 SG_ 2147485050 Trailer2TPMAxlTireCfg_Axle5_ISig 6000;
BA_REL_ "GenSigFirstTimeoutTime" BU_SG_REL_ IC3 SG_ 2147485050 Trailer2TPMAxlTireCfg_Axle4_ISig 24000;
BA_REL_ "GenSigTimeoutTime" BU_SG_REL_ IC3 SG_ 2147485050 Trailer2TPMAxlTireCfg_Axle4_ISig 6000;
BA_REL_ "GenSigFirstTimeoutTime" BU_SG_REL_ IC3 SG_ 2147485050 Trailer2TPMThresCfg_AxleNr_ISig_ 24000;
BA_REL_ "GenSigTimeoutTime" BU_SG_REL_ IC3 SG_ 2147485050 Trailer2TPMThresCfg_AxleNr_ISig_ 6000;
BA_REL_ "GenSigFirstTimeoutTime" BU_SG_REL_ IC3 SG_ 2147485050 Trailer2TPMThresCfg_ExtOverPres_ 24000;
BA_REL_ "GenSigTimeoutTime" BU_SG_REL_ IC3 SG_ 2147485050 Trailer2TPMThresCfg_ExtOverPres_ 6000;
BA_REL_ "GenSigFirstTimeoutTime" BU_SG_REL_ IC3 SG_ 2147485050 Trailer2TPMThresCfg_UnderPres_IS 24000;
BA_REL_ "GenSigTimeoutTime" BU_SG_REL_ IC3 SG_ 2147485050 Trailer2TPMThresCfg_UnderPres_IS 6000;
BA_REL_ "GenSigFirstTimeoutTime" BU_SG_REL_ IC3 SG_ 2147485050 Trailer2TPMThresCfg_ExtUnderPres 24000;
BA_REL_ "GenSigTimeoutTime" BU_SG_REL_ IC3 SG_ 2147485050 Trailer2TPMThresCfg_ExtUnderPres 6000;
BA_REL_ "GenSigFirstTimeoutTime" BU_SG_REL_ IC3 SG_ 2147485049 Trailer1TPMAxlTireCfg_Axle1_ISig 24000;
BA_REL_ "GenSigTimeoutTime" BU_SG_REL_ IC3 SG_ 2147485049 Trailer1TPMAxlTireCfg_Axle1_ISig 6000;
BA_REL_ "GenSigFirstTimeoutTime" BU_SG_REL_ IC3 SG_ 2147485049 Trailer1TPMThresCfg_ExtOverPres_ 24000;
BA_REL_ "GenSigTimeoutTime" BU_SG_REL_ IC3 SG_ 2147485049 Trailer1TPMThresCfg_ExtOverPres_ 6000;
BA_REL_ "GenSigFirstTimeoutTime" BU_SG_REL_ IC3 SG_ 2147485049 Trailer1TPMAxlTireCfg_Axle2_ISig 24000;
BA_REL_ "GenSigTimeoutTime" BU_SG_REL_ IC3 SG_ 2147485049 Trailer1TPMAxlTireCfg_Axle2_ISig 6000;
BA_REL_ "GenSigFirstTimeoutTime" BU_SG_REL_ IC3 SG_ 2147485049 Trailer1TPMThresCfg_OverPres_ISi 24000;
BA_REL_ "GenSigTimeoutTime" BU_SG_REL_ IC3 SG_ 2147485049 Trailer1TPMThresCfg_OverPres_ISi 6000;
BA_REL_ "GenSigFirstTimeoutTime" BU_SG_REL_ IC3 SG_ 2147485049 Trailer1TPMAxlTireCfg_Axle5_ISig 24000;
BA_REL_ "GenSigTimeoutTime" BU_SG_REL_ IC3 SG_ 2147485049 Trailer1TPMAxlTireCfg_Axle5_ISig 6000;
BA_REL_ "GenSigFirstTimeoutTime" BU_SG_REL_ IC3 SG_ 2147485049 Trailer1TPMType_ISig_4 24000;
BA_REL_ "GenSigTimeoutTime" BU_SG_REL_ IC3 SG_ 2147485049 Trailer1TPMType_ISig_4 6000;
BA_REL_ "GenSigFirstTimeoutTime" BU_SG_REL_ IC3 SG_ 2147485049 MaintResetFailureCause 24000;
BA_REL_ "GenSigTimeoutTime" BU_SG_REL_ IC3 SG_ 2147485049 MaintResetFailureCause 6000;
BA_REL_ "GenSigFirstTimeoutTime" BU_SG_REL_ IC3 SG_ 2147485049 Trailer1TPMThresCfg_UnderPres_IS 24000;
BA_REL_ "GenSigTimeoutTime" BU_SG_REL_ IC3 SG_ 2147485049 Trailer1TPMThresCfg_UnderPres_IS 6000;
BA_REL_ "GenSigFirstTimeoutTime" BU_SG_REL_ IC3 SG_ 2147485049 Trailer1TPMThresCfg_ExtUnderPres 24000;
BA_REL_ "GenSigTimeoutTime" BU_SG_REL_ IC3 SG_ 2147485049 Trailer1TPMThresCfg_ExtUnderPres 6000;
BA_REL_ "GenSigFirstTimeoutTime" BU_SG_REL_ IC3 SG_ 2147485049 Trailer1TPMThresCfg_AxleNr_ISig_ 24000;
BA_REL_ "GenSigTimeoutTime" BU_SG_REL_ IC3 SG_ 2147485049 Trailer1TPMThresCfg_AxleNr_ISig_ 6000;
BA_REL_ "GenSigFirstTimeoutTime" BU_SG_REL_ IC3 SG_ 2147485049 Trailer1TPMAxlTireCfg_Axle4_ISig 24000;
BA_REL_ "GenSigTimeoutTime" BU_SG_REL_ IC3 SG_ 2147485049 Trailer1TPMAxlTireCfg_Axle4_ISig 6000;
BA_REL_ "GenSigFirstTimeoutTime" BU_SG_REL_ IC3 SG_ 2147485049 Trailer1TPMAxlTireCfg_Axle3_ISig 24000;
BA_REL_ "GenSigTimeoutTime" BU_SG_REL_ IC3 SG_ 2147485049 Trailer1TPMAxlTireCfg_Axle3_ISig 6000;
BA_REL_ "GenSigFirstTimeoutTime" BU_SG_REL_ IC3 SG_ 2147485084 DistToEmptyLNG 24000;
BA_REL_ "GenSigTimeoutTime" BU_SG_REL_ IC3 SG_ 2147485084 DistToEmptyLNG 6000;
BA_REL_ "GenSigFirstTimeoutTime" BU_SG_REL_ IC3 SG_ 2147485084 DistToEmptyDiesel 24000;
BA_REL_ "GenSigTimeoutTime" BU_SG_REL_ IC3 SG_ 2147485084 DistToEmptyDiesel 6000;
BA_REL_ "GenSigFirstTimeoutTime" BU_SG_REL_ IC3 SG_ 2147485084 CoastingUseDistance_ISig_4 24000;
BA_REL_ "GenSigTimeoutTime" BU_SG_REL_ IC3 SG_ 2147485084 CoastingUseDistance_ISig_4 6000;
BA_REL_ "GenSigFirstTimeoutTime" BU_SG_REL_ IC3 SG_ 2147485083 EngSpeedOverThresholdTime_ISig_4 24000;
BA_REL_ "GenSigTimeoutTime" BU_SG_REL_ IC3 SG_ 2147485083 EngSpeedOverThresholdTime_ISig_4 6000;
BA_REL_ "GenSigFirstTimeoutTime" BU_SG_REL_ IC3 SG_ 2147485083 EngLoadOverThresholdDistance_ISi 24000;
BA_REL_ "GenSigTimeoutTime" BU_SG_REL_ IC3 SG_ 2147485083 EngLoadOverThresholdDistance_ISi 6000;
BA_REL_ "GenSigFirstTimeoutTime" BU_SG_REL_ IC3 SG_ 2147485082 EngineGreenAreaFuel_ISig_4 24000;
BA_REL_ "GenSigTimeoutTime" BU_SG_REL_ IC3 SG_ 2147485082 EngineGreenAreaFuel_ISig_4 6000;
BA_REL_ "GenSigFirstTimeoutTime" BU_SG_REL_ IC3 SG_ 2147485082 LCCDistance_ISig_4 24000;
BA_REL_ "GenSigTimeoutTime" BU_SG_REL_ IC3 SG_ 2147485082 LCCDistance_ISig_4 6000;
BA_REL_ "GenSigFirstTimeoutTime" BU_SG_REL_ IC3 SG_ 2147485081 StopCounter_ISig_4 24000;
BA_REL_ "GenSigTimeoutTime" BU_SG_REL_ IC3 SG_ 2147485081 StopCounter_ISig_4 6000;
BA_REL_ "GenSigFirstTimeoutTime" BU_SG_REL_ IC3 SG_ 2147485081 OverspeedDistance_ISig_4 24000;
BA_REL_ "GenSigTimeoutTime" BU_SG_REL_ IC3 SG_ 2147485081 OverspeedDistance_ISig_4 6000;
BA_REL_ "GenSigFirstTimeoutTime" BU_SG_REL_ IC3 SG_ 2147485080 RobotizedGboxPowerModeTime_ISig_ 24000;
BA_REL_ "GenSigTimeoutTime" BU_SG_REL_ IC3 SG_ 2147485080 RobotizedGboxPowerModeTime_ISig_ 6000;
BA_REL_ "GenSigFirstTimeoutTime" BU_SG_REL_ IC3 SG_ 2147485080 TotalServiceBrakeCounter_ISig_4 24000;
BA_REL_ "GenSigTimeoutTime" BU_SG_REL_ IC3 SG_ 2147485080 TotalServiceBrakeCounter_ISig_4 6000;
BA_REL_ "GenSigFirstTimeoutTime" BU_SG_REL_ IC3 SG_ 2147485079 RobotizedGboxManualModeTime_ISig 24000;
BA_REL_ "GenSigTimeoutTime" BU_SG_REL_ IC3 SG_ 2147485079 RobotizedGboxManualModeTime_ISig 6000;
BA_REL_ "GenSigFirstTimeoutTime" BU_SG_REL_ IC3 SG_ 2147485079 RobotizedGboxAutoModeTime_ISig_4 24000;
BA_REL_ "GenSigTimeoutTime" BU_SG_REL_ IC3 SG_ 2147485079 RobotizedGboxAutoModeTime_ISig_4 6000;
BA_REL_ "GenSigFirstTimeoutTime" BU_SG_REL_ TECU SG_ 2147484894 PusherAxleLoad_ISig_4 6000;
BA_REL_ "GenSigTimeoutTime" BU_SG_REL_ TECU SG_ 2147484894 PusherAxleLoad_ISig_4 1500;
BA_REL_ "GenSigFirstTimeoutTime" BU_SG_REL_ BBM SG_ 2147484894 PusherAxleLoad_ISig_4 6000;
BA_REL_ "GenSigTimeoutTime" BU_SG_REL_ BBM SG_ 2147484894 PusherAxleLoad_ISig_4 1500;
BA_REL_ "GenSigFirstTimeoutTime" BU_SG_REL_ DACU SG_ 2147484894 PusherAxleLoad_ISig_4 6000;
BA_REL_ "GenSigTimeoutTime" BU_SG_REL_ DACU SG_ 2147484894 PusherAxleLoad_ISig_4 1500;
BA_REL_ "GenSigFirstTimeoutTime" BU_SG_REL_ BBM SG_ 2147484894 FogLight_Front_cmd_ISig_4 6000;
BA_REL_ "GenSigTimeoutTime" BU_SG_REL_ BBM SG_ 2147484894 FogLight_Front_cmd_ISig_4 1500;
BA_REL_ "GenSigFirstTimeoutTime" BU_SG_REL_ TECU SG_ 2147484894 TagAxleLoad_ISig_4 6000;
BA_REL_ "GenSigTimeoutTime" BU_SG_REL_ TECU SG_ 2147484894 TagAxleLoad_ISig_4 1500;
BA_REL_ "GenSigFirstTimeoutTime" BU_SG_REL_ DACU SG_ 2147484894 TagAxleLoad_ISig_4 6000;
BA_REL_ "GenSigTimeoutTime" BU_SG_REL_ DACU SG_ 2147484894 TagAxleLoad_ISig_4 1500;
BA_REL_ "GenSigFirstTimeoutTime" BU_SG_REL_ BBM SG_ 2147484894 TagAxleLoad_ISig_4 6000;
BA_REL_ "GenSigTimeoutTime" BU_SG_REL_ BBM SG_ 2147484894 TagAxleLoad_ISig_4 1500;
BA_REL_ "GenSigFirstTimeoutTime" BU_SG_REL_ IC3 SG_ 2147484891 SelfStartAssistSwitch_Input_ISig 6000;
BA_REL_ "GenSigTimeoutTime" BU_SG_REL_ IC3 SG_ 2147484891 SelfStartAssistSwitch_Input_ISig 1500;
BA_REL_ "GenSigFirstTimeoutTime" BU_SG_REL_ BBM SG_ 2147484891 DriveAxleLoad_ISig_4 6000;
BA_REL_ "GenSigTimeoutTime" BU_SG_REL_ BBM SG_ 2147484891 DriveAxleLoad_ISig_4 1500;
BA_REL_ "GenSigFirstTimeoutTime" BU_SG_REL_ DACU SG_ 2147484891 DriveAxleLoad_ISig_4 6000;
BA_REL_ "GenSigTimeoutTime" BU_SG_REL_ DACU SG_ 2147484891 DriveAxleLoad_ISig_4 1500;
BA_REL_ "GenSigFirstTimeoutTime" BU_SG_REL_ TECU SG_ 2147484891 DriveAxleLoad_ISig_4 6000;
BA_REL_ "GenSigTimeoutTime" BU_SG_REL_ TECU SG_ 2147484891 DriveAxleLoad_ISig_4 1500;
BA_REL_ "GenSigFirstTimeoutTime" BU_SG_REL_ BBM SG_ 2147484891 BatterySOCAlertRawData_rqst_ISig 6000;
BA_REL_ "GenSigTimeoutTime" BU_SG_REL_ BBM SG_ 2147484891 BatterySOCAlertRawData_rqst_ISig 1500;
BA_REL_ "GenSigFirstTimeoutTime" BU_SG_REL_ CIOM SG_ 2147484891 BatterySOCAlertRawData_rqst_ISig 6000;
BA_REL_ "GenSigTimeoutTime" BU_SG_REL_ CIOM SG_ 2147484891 BatterySOCAlertRawData_rqst_ISig 1500;
BA_REL_ "GenSigFirstTimeoutTime" BU_SG_REL_ IC3 SG_ 2147484891 LivBatDisconnectDetectStat_ISig_ 6000;
BA_REL_ "GenSigTimeoutTime" BU_SG_REL_ IC3 SG_ 2147484891 LivBatDisconnectDetectStat_ISig_ 1500;
BA_REL_ "GenSigFirstTimeoutTime" BU_SG_REL_ EMS SG_ 2147484891 SelfStartAssist_stat_ISig_4 6000;
BA_REL_ "GenSigTimeoutTime" BU_SG_REL_ EMS SG_ 2147484891 SelfStartAssist_stat_ISig_4 1500;
BA_REL_ "GenSigFirstTimeoutTime" BU_SG_REL_ IC3 SG_ 2147484891 SelfStartAssist_stat_ISig_4 6000;
BA_REL_ "GenSigTimeoutTime" BU_SG_REL_ IC3 SG_ 2147484891 SelfStartAssist_stat_ISig_4 1500;
BA_REL_ "GenSigFirstTimeoutTime" BU_SG_REL_ IC3 SG_ 2147484891 JumpChargeAlert_stat_ISig_4 6000;
BA_REL_ "GenSigTimeoutTime" BU_SG_REL_ IC3 SG_ 2147484891 JumpChargeAlert_stat_ISig_4 1500;
BA_REL_ "GenSigFirstTimeoutTime" BU_SG_REL_ IC3 SG_ 2147484891 GChargerStatus_ISig_4 6000;
BA_REL_ "GenSigTimeoutTime" BU_SG_REL_ IC3 SG_ 2147484891 GChargerStatus_ISig_4 1500;
BA_REL_ "GenSigFirstTimeoutTime" BU_SG_REL_ CIOM SG_ 2147484891 ShortStopHeater_status_ISig_4 6000;
BA_REL_ "GenSigTimeoutTime" BU_SG_REL_ CIOM SG_ 2147484891 ShortStopHeater_status_ISig_4 1500;
BA_REL_ "GenSigFirstTimeoutTime" BU_SG_REL_ DACU SG_ 2147484891 SecondaryDriveAxleLoad_ISig_4 6000;
BA_REL_ "GenSigTimeoutTime" BU_SG_REL_ DACU SG_ 2147484891 SecondaryDriveAxleLoad_ISig_4 1500;
BA_REL_ "GenSigFirstTimeoutTime" BU_SG_REL_ BBM SG_ 2147484891 SecondaryDriveAxleLoad_ISig_4 6000;
BA_REL_ "GenSigTimeoutTime" BU_SG_REL_ BBM SG_ 2147484891 SecondaryDriveAxleLoad_ISig_4 1500;
BA_REL_ "GenSigFirstTimeoutTime" BU_SG_REL_ TECU SG_ 2147484891 SecondaryDriveAxleLoad_ISig_4 6000;
BA_REL_ "GenSigTimeoutTime" BU_SG_REL_ TECU SG_ 2147484891 SecondaryDriveAxleLoad_ISig_4 1500;
BA_REL_ "GenSigFirstTimeoutTime" BU_SG_REL_ IC3 SG_ 2147484891 StartBatteryDisplay_stat_ISig_4 6000;
BA_REL_ "GenSigTimeoutTime" BU_SG_REL_ IC3 SG_ 2147484891 StartBatteryDisplay_stat_ISig_4 1500;
BA_REL_ "GenSigFirstTimeoutTime" BU_SG_REL_ IC3 SG_ 2147485056 MaintService_ServiceCalendarTime 24000;
BA_REL_ "GenSigTimeoutTime" BU_SG_REL_ IC3 SG_ 2147485056 MaintService_ServiceCalendarTime 6000;
BA_REL_ "GenSigFirstTimeoutTime" BU_SG_REL_ IC3 SG_ 2147485056 MaintService_EngTimeID_ISig_4_58 24000;
BA_REL_ "GenSigTimeoutTime" BU_SG_REL_ IC3 SG_ 2147485056 MaintService_EngTimeID_ISig_4_58 6000;
BA_REL_ "GenSigFirstTimeoutTime" BU_SG_REL_ IC3 SG_ 2147485056 MaintService_DistID_ISig_4_580 24000;
BA_REL_ "GenSigTimeoutTime" BU_SG_REL_ IC3 SG_ 2147485056 MaintService_DistID_ISig_4_580 6000;
BA_REL_ "GenSigFirstTimeoutTime" BU_SG_REL_ IC3 SG_ 2147485056 MaintService_ServiceDistance_ISi 24000;
BA_REL_ "GenSigTimeoutTime" BU_SG_REL_ IC3 SG_ 2147485056 MaintService_ServiceDistance_ISi 6000;
BA_REL_ "GenSigFirstTimeoutTime" BU_SG_REL_ IC3 SG_ 2147485056 MaintService_ServiceEngineTime_I 24000;
BA_REL_ "GenSigTimeoutTime" BU_SG_REL_ IC3 SG_ 2147485056 MaintService_ServiceEngineTime_I 6000;
BA_REL_ "GenSigFirstTimeoutTime" BU_SG_REL_ IC3 SG_ 2147485056 MaintService_CalDateID_ISig_4_58 24000;
BA_REL_ "GenSigTimeoutTime" BU_SG_REL_ IC3 SG_ 2147485056 MaintService_CalDateID_ISig_4_58 6000;
BA_REL_ "GenSigFirstTimeoutTime" BU_SG_REL_ CIOM SG_ 2147485046 MaintService_ServiceEngineT_0000 24000;
BA_REL_ "GenSigTimeoutTime" BU_SG_REL_ CIOM SG_ 2147485046 MaintService_ServiceEngineT_0000 6000;
BA_REL_ "GenSigFirstTimeoutTime" BU_SG_REL_ CIOM SG_ 2147485046 MaintService_EngTimeID_ISig_4_57 24000;
BA_REL_ "GenSigTimeoutTime" BU_SG_REL_ CIOM SG_ 2147485046 MaintService_EngTimeID_ISig_4_57 6000;
BA_REL_ "GenSigFirstTimeoutTime" BU_SG_REL_ CIOM SG_ 2147485046 MaintService_DistID_ISig_4_576 24000;
BA_REL_ "GenSigTimeoutTime" BU_SG_REL_ CIOM SG_ 2147485046 MaintService_DistID_ISig_4_576 6000;
BA_REL_ "GenSigFirstTimeoutTime" BU_SG_REL_ CIOM SG_ 2147485046 MaintService_ServiceDistanc_0000 24000;
BA_REL_ "GenSigTimeoutTime" BU_SG_REL_ CIOM SG_ 2147485046 MaintService_ServiceDistanc_0000 6000;
BA_REL_ "GenSigFirstTimeoutTime" BU_SG_REL_ CIOM SG_ 2147485046 MaintService_CalDateID_ISig_4_57 24000;
BA_REL_ "GenSigTimeoutTime" BU_SG_REL_ CIOM SG_ 2147485046 MaintService_CalDateID_ISig_4_57 6000;
BA_REL_ "GenSigFirstTimeoutTime" BU_SG_REL_ CIOM SG_ 2147485046 MaintService_ServiceCalenda_0000 24000;
BA_REL_ "GenSigTimeoutTime" BU_SG_REL_ CIOM SG_ 2147485046 MaintService_ServiceCalenda_0000 6000;
BA_REL_ "GenSigFirstTimeoutTime" BU_SG_REL_ IC3 SG_ 2147485076 EngTrueIdleSpeedTime_ISig_4 24000;
BA_REL_ "GenSigTimeoutTime" BU_SG_REL_ IC3 SG_ 2147485076 EngTrueIdleSpeedTime_ISig_4 6000;
BA_REL_ "GenSigFirstTimeoutTime" BU_SG_REL_ IC3 SG_ 2147485076 EngineGreenAreaOutTime_ISig_4 24000;
BA_REL_ "GenSigTimeoutTime" BU_SG_REL_ IC3 SG_ 2147485076 EngineGreenAreaOutTime_ISig_4 6000;
BA_REL_ "GenSigFirstTimeoutTime" BU_SG_REL_ IC3 SG_ 2147484707 BatterySOCnom_ISig_4 3600;
BA_REL_ "GenSigTimeoutTime" BU_SG_REL_ IC3 SG_ 2147484707 BatterySOCnom_ISig_4 900;
BA_REL_ "GenSigFirstTimeoutTime" BU_SG_REL_ IC3 SG_ 2147484707 BatterySOH_ISig_4 3600;
BA_REL_ "GenSigTimeoutTime" BU_SG_REL_ IC3 SG_ 2147484707 BatterySOH_ISig_4 900;
BA_REL_ "GenSigFirstTimeoutTime" BU_SG_REL_ CIOM SG_ 2147484707 ReducedLoadMode_stat_ISig_4 3600;
BA_REL_ "GenSigTimeoutTime" BU_SG_REL_ CIOM SG_ 2147484707 ReducedLoadMode_stat_ISig_4 900;
BA_REL_ "GenSigFirstTimeoutTime" BU_SG_REL_ IC3 SG_ 2147484707 BatterySOCAlert_rqst_ISig_4 3600;
BA_REL_ "GenSigTimeoutTime" BU_SG_REL_ IC3 SG_ 2147484707 BatterySOCAlert_rqst_ISig_4 900;
BA_REL_ "GenSigFirstTimeoutTime" BU_SG_REL_ BBM SG_ 2147484707 BatterySOCAlert_rqst_ISig_4 3600;
BA_REL_ "GenSigTimeoutTime" BU_SG_REL_ BBM SG_ 2147484707 BatterySOCAlert_rqst_ISig_4 900;
BA_REL_ "GenSigFirstTimeoutTime" BU_SG_REL_ CIOM SG_ 2147484707 BatterySOCAlert_rqst_ISig_4 3600;
BA_REL_ "GenSigTimeoutTime" BU_SG_REL_ CIOM SG_ 2147484707 BatterySOCAlert_rqst_ISig_4 900;
BA_REL_ "GenSigFirstTimeoutTime" BU_SG_REL_ IC3 SG_ 2147484707 BatteryVoltageDisplayValue_ISig_ 3600;
BA_REL_ "GenSigTimeoutTime" BU_SG_REL_ IC3 SG_ 2147484707 BatteryVoltageDisplayValue_ISig_ 900;
BA_REL_ "GenSigFirstTimeoutTime" BU_SG_REL_ BBM SG_ 2147484707 BatteryVoltageDisplayValue_ISig_ 3600;
BA_REL_ "GenSigTimeoutTime" BU_SG_REL_ BBM SG_ 2147484707 BatteryVoltageDisplayValue_ISig_ 900;
BA_REL_ "GenSigFirstTimeoutTime" BU_SG_REL_ EMS SG_ 2147484707 BatteryCurrent_ISig_4 3600;
BA_REL_ "GenSigTimeoutTime" BU_SG_REL_ EMS SG_ 2147484707 BatteryCurrent_ISig_4 900;
BA_REL_ "GenSigFirstTimeoutTime" BU_SG_REL_ IC3 SG_ 2147484707 BatteryCurrent_ISig_4 3600;
BA_REL_ "GenSigTimeoutTime" BU_SG_REL_ IC3 SG_ 2147484707 BatteryCurrent_ISig_4 900;
BA_REL_ "GenSigFirstTimeoutTime" BU_SG_REL_ EMS SG_ 2147484573 MaintOilQuality 3000;
BA_REL_ "GenSigTimeoutTime" BU_SG_REL_ EMS SG_ 2147484573 MaintOilQuality 450;
BA_REL_ "GenSigFirstTimeoutTime" BU_SG_REL_ IC3 SG_ 2147484573 ECSLimpHomeNotification_ISig_4 3000;
BA_REL_ "GenSigTimeoutTime" BU_SG_REL_ IC3 SG_ 2147484573 ECSLimpHomeNotification_ISig_4 450;
BA_REL_ "GenSigFirstTimeoutTime" BU_SG_REL_ IC3 SG_ 2147484573 MaintenanceResetStatus 3000;
BA_REL_ "GenSigTimeoutTime" BU_SG_REL_ IC3 SG_ 2147484573 MaintenanceResetStatus 450;
BA_REL_ "GenSigFirstTimeoutTime" BU_SG_REL_ IC3 SG_ 2147484573 FirstAxleLowerPrioSelected_ISig_ 3000;
BA_REL_ "GenSigTimeoutTime" BU_SG_REL_ IC3 SG_ 2147484573 FirstAxleLowerPrioSelected_ISig_ 450;
BA_REL_ "GenSigFirstTimeoutTime" BU_SG_REL_ EMS SG_ 2147484573 MaintOilReset 3000;
BA_REL_ "GenSigTimeoutTime" BU_SG_REL_ EMS SG_ 2147484573 MaintOilReset 450;
BA_REL_ "GenSigFirstTimeoutTime" BU_SG_REL_ IC3 SG_ 2147484573 RssInhibStartEngine_rqst 3000;
BA_REL_ "GenSigTimeoutTime" BU_SG_REL_ IC3 SG_ 2147484573 RssInhibStartEngine_rqst 450;
BA_REL_ "GenSigFirstTimeoutTime" BU_SG_REL_ BBM SG_ 2147484573 PositionLightRequest_status 3000;
BA_REL_ "GenSigTimeoutTime" BU_SG_REL_ BBM SG_ 2147484573 PositionLightRequest_status 450;
BA_REL_ "GenSigFirstTimeoutTime" BU_SG_REL_ IC3 SG_ 2147484573 PositionLightRequest_status 3000;
BA_REL_ "GenSigTimeoutTime" BU_SG_REL_ IC3 SG_ 2147484573 PositionLightRequest_status 450;
BA_REL_ "GenSigFirstTimeoutTime" BU_SG_REL_ CIOM SG_ 2147484573 ExtraBBTailLiftStatus_ISig_4 3000;
BA_REL_ "GenSigTimeoutTime" BU_SG_REL_ CIOM SG_ 2147484573 ExtraBBTailLiftStatus_ISig_4 450;
BA_REL_ "GenSigFirstTimeoutTime" BU_SG_REL_ IC3 SG_ 2147484573 MaintenanceNotification_ISig_4 3000;
BA_REL_ "GenSigTimeoutTime" BU_SG_REL_ IC3 SG_ 2147484573 MaintenanceNotification_ISig_4 450;
BA_REL_ "GenSigFirstTimeoutTime" BU_SG_REL_ BBM SG_ 2147484573 ExtraBBSlidable5thWheelStatus 3000;
BA_REL_ "GenSigTimeoutTime" BU_SG_REL_ BBM SG_ 2147484573 ExtraBBSlidable5thWheelStatus 450;
BA_REL_ "GenSigFirstTimeoutTime" BU_SG_REL_ CIOM SG_ 2147484573 ExtraBBSlidable5thWheelStatus 3000;
BA_REL_ "GenSigTimeoutTime" BU_SG_REL_ CIOM SG_ 2147484573 ExtraBBSlidable5thWheelStatus 450;
BA_REL_ "GenSigFirstTimeoutTime" BU_SG_REL_ TECU SG_ 2147484573 ParkBrakeReleasePossible_stat 3000;
BA_REL_ "GenSigTimeoutTime" BU_SG_REL_ TECU SG_ 2147484573 ParkBrakeReleasePossible_stat 450;
BA_REL_ "GenSigFirstTimeoutTime" BU_SG_REL_ IC3 SG_ 2147484573 ParkBrakeReleasePossible_stat 3000;
BA_REL_ "GenSigTimeoutTime" BU_SG_REL_ IC3 SG_ 2147484573 ParkBrakeReleasePossible_stat 450;
BA_REL_ "GenSigFirstTimeoutTime" BU_SG_REL_ CIOM SG_ 2147484573 LoadDistributionALDChangeACK_ISi 3000;
BA_REL_ "GenSigTimeoutTime" BU_SG_REL_ CIOM SG_ 2147484573 LoadDistributionALDChangeACK_ISi 450;
BA_REL_ "GenSigFirstTimeoutTime" BU_SG_REL_ IC3 SG_ 2147484573 LoadDistributionALDChangeACK_ISi 3000;
BA_REL_ "GenSigTimeoutTime" BU_SG_REL_ IC3 SG_ 2147484573 LoadDistributionALDChangeACK_ISi 450;
BA_REL_ "GenSigFirstTimeoutTime" BU_SG_REL_ IC3 SG_ 2147484573 ParkBrakeWorkshopMode_ISig_4 3000;
BA_REL_ "GenSigTimeoutTime" BU_SG_REL_ IC3 SG_ 2147484573 ParkBrakeWorkshopMode_ISig_4 450;
BA_REL_ "GenSigFirstTimeoutTime" BU_SG_REL_ BBM SG_ 2147484573 ExtraBBContainerUnlockStatus 3000;
BA_REL_ "GenSigTimeoutTime" BU_SG_REL_ BBM SG_ 2147484573 ExtraBBContainerUnlockStatus 450;
BA_REL_ "GenSigFirstTimeoutTime" BU_SG_REL_ CIOM SG_ 2147484573 ExtraBBContainerUnlockStatus 3000;
BA_REL_ "GenSigTimeoutTime" BU_SG_REL_ CIOM SG_ 2147484573 ExtraBBContainerUnlockStatus 450;
BA_REL_ "GenSigFirstTimeoutTime" BU_SG_REL_ BBM SG_ 2147484573 MainBeamRequest_status_ISig_4 3000;
BA_REL_ "GenSigTimeoutTime" BU_SG_REL_ BBM SG_ 2147484573 MainBeamRequest_status_ISig_4 450;
BA_REL_ "GenSigFirstTimeoutTime" BU_SG_REL_ DACU SG_ 2147484573 MainBeamRequest_status_ISig_4 3000;
BA_REL_ "GenSigTimeoutTime" BU_SG_REL_ DACU SG_ 2147484573 MainBeamRequest_status_ISig_4 600;
BA_REL_ "GenSigFirstTimeoutTime" BU_SG_REL_ CIOM SG_ 2147484573 ExtraBBCraneStatus_ISig_4 3000;
BA_REL_ "GenSigTimeoutTime" BU_SG_REL_ CIOM SG_ 2147484573 ExtraBBCraneStatus_ISig_4 450;
BA_REL_ "GenSigFirstTimeoutTime" BU_SG_REL_ BBM SG_ 2147484573 ExtraBBCraneStatus_ISig_4 3000;
BA_REL_ "GenSigTimeoutTime" BU_SG_REL_ BBM SG_ 2147484573 ExtraBBCraneStatus_ISig_4 450;
BA_REL_ "GenSigFirstTimeoutTime" BU_SG_REL_ EMS SG_ 2147484573 AirCompressorStatus 3000;
BA_REL_ "GenSigTimeoutTime" BU_SG_REL_ EMS SG_ 2147484573 AirCompressorStatus 450;
BA_REL_ "GenSigFirstTimeoutTime" BU_SG_REL_ BBM SG_ 2147484573 AirCompressorStatus 3000;
BA_REL_ "GenSigTimeoutTime" BU_SG_REL_ BBM SG_ 2147484573 AirCompressorStatus 450;
BA_REL_ "GenSigFirstTimeoutTime" BU_SG_REL_ TECU SG_ 2147484573 TrailerABSStatus_ISig_4 3000;
BA_REL_ "GenSigTimeoutTime" BU_SG_REL_ TECU SG_ 2147484573 TrailerABSStatus_ISig_4 450;
BA_REL_ "GenSigFirstTimeoutTime" BU_SG_REL_ IC3 SG_ 2147484573 TrailerABSStatus_ISig_4 3000;
BA_REL_ "GenSigTimeoutTime" BU_SG_REL_ IC3 SG_ 2147484573 TrailerABSStatus_ISig_4 450;
BA_REL_ "GenSigFirstTimeoutTime" BU_SG_REL_ EMS SG_ 2147484573 TrailerABSStatus_ISig_4 3000;
BA_REL_ "GenSigTimeoutTime" BU_SG_REL_ EMS SG_ 2147484573 TrailerABSStatus_ISig_4 450;
BA_REL_ "GenSigFirstTimeoutTime" BU_SG_REL_ DACU SG_ 2147484573 TrailerABSStatus_ISig_4 3000;
BA_REL_ "GenSigTimeoutTime" BU_SG_REL_ DACU SG_ 2147484573 TrailerABSStatus_ISig_4 500;
BA_REL_ "GenSigFirstTimeoutTime" BU_SG_REL_ EMS SG_ 2147484573 RegenInhibitVehicleHeight_ISig_4 3000;
BA_REL_ "GenSigTimeoutTime" BU_SG_REL_ EMS SG_ 2147484573 RegenInhibitVehicleHeight_ISig_4 450;
BA_REL_ "GenSigFirstTimeoutTime" BU_SG_REL_ BBM SG_ 2147484573 PoorAirPressureInfo 3000;
BA_REL_ "GenSigTimeoutTime" BU_SG_REL_ BBM SG_ 2147484573 PoorAirPressureInfo 450;
BA_REL_ "GenSigFirstTimeoutTime" BU_SG_REL_ IC3 SG_ 2147484573 PoorAirPressureInfo 3000;
BA_REL_ "GenSigTimeoutTime" BU_SG_REL_ IC3 SG_ 2147484573 PoorAirPressureInfo 500;
BA_REL_ "GenSigFirstTimeoutTime" BU_SG_REL_ BBM SG_ 2147484573 FogLightRearRequest_stat 3000;
BA_REL_ "GenSigTimeoutTime" BU_SG_REL_ BBM SG_ 2147484573 FogLightRearRequest_stat 450;
BA_REL_ "GenSigFirstTimeoutTime" BU_SG_REL_ BBM SG_ 2147484573 MainBeam_cmd_ISig_4 3000;
BA_REL_ "GenSigTimeoutTime" BU_SG_REL_ BBM SG_ 2147484573 MainBeam_cmd_ISig_4 600;
BA_REL_ "GenSigFirstTimeoutTime" BU_SG_REL_ IC3 SG_ 2147484573 FrontParkBrakeOverrideInd_ISig_4 3000;
BA_REL_ "GenSigTimeoutTime" BU_SG_REL_ IC3 SG_ 2147484573 FrontParkBrakeOverrideInd_ISig_4 450;
BA_REL_ "GenSigFirstTimeoutTime" BU_SG_REL_ BBM SG_ 2147484497 AuxSwitchBbLoad4_cmd 3000;
BA_REL_ "GenSigTimeoutTime" BU_SG_REL_ BBM SG_ 2147484497 AuxSwitchBbLoad4_cmd 300;
BA_REL_ "GenSigFirstTimeoutTime" BU_SG_REL_ CIOM SG_ 2147484497 AuxSwitchBbLoad1_Status_ISig_4 3000;
BA_REL_ "GenSigTimeoutTime" BU_SG_REL_ CIOM SG_ 2147484497 AuxSwitchBbLoad1_Status_ISig_4 300;
BA_REL_ "GenSigFirstTimeoutTime" BU_SG_REL_ BBM SG_ 2147484497 AuxSwitchBbLoad1_Status_ISig_4 3000;
BA_REL_ "GenSigTimeoutTime" BU_SG_REL_ BBM SG_ 2147484497 AuxSwitchBbLoad1_Status_ISig_4 300;
BA_REL_ "GenSigFirstTimeoutTime" BU_SG_REL_ BBM SG_ 2147484497 AuxSwitchBbLoad3_cmd 3000;
BA_REL_ "GenSigTimeoutTime" BU_SG_REL_ BBM SG_ 2147484497 AuxSwitchBbLoad3_cmd 300;
BA_REL_ "GenSigFirstTimeoutTime" BU_SG_REL_ IC3 SG_ 2147484497 MainBeam_rqst 3000;
BA_REL_ "GenSigTimeoutTime" BU_SG_REL_ IC3 SG_ 2147484497 MainBeam_rqst 300;
BA_REL_ "GenSigFirstTimeoutTime" BU_SG_REL_ IC3 SG_ 2147484497 BatterySOCTrustLevel_ISig_4 3000;
BA_REL_ "GenSigTimeoutTime" BU_SG_REL_ IC3 SG_ 2147484497 BatterySOCTrustLevel_ISig_4 300;
BA_REL_ "GenSigFirstTimeoutTime" BU_SG_REL_ CIOM SG_ 2147484497 AuxSwitchBbLoad4_Status_ISig_4 3000;
BA_REL_ "GenSigTimeoutTime" BU_SG_REL_ CIOM SG_ 2147484497 AuxSwitchBbLoad4_Status_ISig_4 300;
BA_REL_ "GenSigFirstTimeoutTime" BU_SG_REL_ BBM SG_ 2147484497 AuxSwitchBbLoad4_Status_ISig_4 3000;
BA_REL_ "GenSigTimeoutTime" BU_SG_REL_ BBM SG_ 2147484497 AuxSwitchBbLoad4_Status_ISig_4 300;
BA_REL_ "GenSigFirstTimeoutTime" BU_SG_REL_ BBM SG_ 2147484497 BrakeLightConvoy_rqst_ISig_4 3000;
BA_REL_ "GenSigTimeoutTime" BU_SG_REL_ BBM SG_ 2147484497 BrakeLightConvoy_rqst_ISig_4 500;
BA_REL_ "GenSigFirstTimeoutTime" BU_SG_REL_ CIOM SG_ 2147484497 DoorWarningLight_cmd_ISig_4 3000;
BA_REL_ "GenSigTimeoutTime" BU_SG_REL_ CIOM SG_ 2147484497 DoorWarningLight_cmd_ISig_4 300;
BA_REL_ "GenSigFirstTimeoutTime" BU_SG_REL_ IC3 SG_ 2147484497 BlackOutandConvoyMode_rqst_ISig_ 3000;
BA_REL_ "GenSigTimeoutTime" BU_SG_REL_ IC3 SG_ 2147484497 BlackOutandConvoyMode_rqst_ISig_ 300;
BA_REL_ "GenSigFirstTimeoutTime" BU_SG_REL_ DACU SG_ 2147484497 BlackOutandConvoyMode_rqst_ISig_ 3000;
BA_REL_ "GenSigTimeoutTime" BU_SG_REL_ DACU SG_ 2147484497 BlackOutandConvoyMode_rqst_ISig_ 300;
BA_REL_ "GenSigFirstTimeoutTime" BU_SG_REL_ BBM SG_ 2147484497 BlackOutandConvoyMode_rqst_ISig_ 3000;
BA_REL_ "GenSigTimeoutTime" BU_SG_REL_ BBM SG_ 2147484497 BlackOutandConvoyMode_rqst_ISig_ 300;
BA_REL_ "GenSigFirstTimeoutTime" BU_SG_REL_ BBM SG_ 2147484497 DirIndicatorRqstLights_stat 3000;
BA_REL_ "GenSigTimeoutTime" BU_SG_REL_ BBM SG_ 2147484497 DirIndicatorRqstLights_stat 300;
BA_REL_ "GenSigFirstTimeoutTime" BU_SG_REL_ BBM SG_ 2147484497 DippedBeamRequest_status 3000;
BA_REL_ "GenSigTimeoutTime" BU_SG_REL_ BBM SG_ 2147484497 DippedBeamRequest_status 300;
BA_REL_ "GenSigFirstTimeoutTime" BU_SG_REL_ CIOM SG_ 2147484497 AuxSwitchBbLoad3_Status_ISig_4 3000;
BA_REL_ "GenSigTimeoutTime" BU_SG_REL_ CIOM SG_ 2147484497 AuxSwitchBbLoad3_Status_ISig_4 300;
BA_REL_ "GenSigFirstTimeoutTime" BU_SG_REL_ BBM SG_ 2147484497 AuxSwitchBbLoad3_Status_ISig_4 3000;
BA_REL_ "GenSigTimeoutTime" BU_SG_REL_ BBM SG_ 2147484497 AuxSwitchBbLoad3_Status_ISig_4 300;
BA_REL_ "GenSigFirstTimeoutTime" BU_SG_REL_ CIOM SG_ 2147484497 DoorInstepLight_cmd_ISig_4 3000;
BA_REL_ "GenSigTimeoutTime" BU_SG_REL_ CIOM SG_ 2147484497 DoorInstepLight_cmd_ISig_4 300;
BA_REL_ "GenSigFirstTimeoutTime" BU_SG_REL_ BBM SG_ 2147484497 DRLRequest_status 3000;
BA_REL_ "GenSigTimeoutTime" BU_SG_REL_ BBM SG_ 2147484497 DRLRequest_status 300;
BA_REL_ "GenSigFirstTimeoutTime" BU_SG_REL_ BBM SG_ 2147484497 AuxSwitchBbLoad6_Status_ISig_4 3000;
BA_REL_ "GenSigTimeoutTime" BU_SG_REL_ BBM SG_ 2147484497 AuxSwitchBbLoad6_Status_ISig_4 300;
BA_REL_ "GenSigFirstTimeoutTime" BU_SG_REL_ CIOM SG_ 2147484497 AuxSwitchBbLoad6_Status_ISig_4 3000;
BA_REL_ "GenSigTimeoutTime" BU_SG_REL_ CIOM SG_ 2147484497 AuxSwitchBbLoad6_Status_ISig_4 300;
BA_REL_ "GenSigFirstTimeoutTime" BU_SG_REL_ CIOM SG_ 2147484497 AuxSwitchBbLoad2_Status_ISig_4 3000;
BA_REL_ "GenSigTimeoutTime" BU_SG_REL_ CIOM SG_ 2147484497 AuxSwitchBbLoad2_Status_ISig_4 300;
BA_REL_ "GenSigFirstTimeoutTime" BU_SG_REL_ BBM SG_ 2147484497 AuxSwitchBbLoad2_Status_ISig_4 3000;
BA_REL_ "GenSigTimeoutTime" BU_SG_REL_ BBM SG_ 2147484497 AuxSwitchBbLoad2_Status_ISig_4 300;
BA_REL_ "GenSigFirstTimeoutTime" BU_SG_REL_ BBM SG_ 2147484497 AuxSwitchBbLoad5_cmd 3000;
BA_REL_ "GenSigTimeoutTime" BU_SG_REL_ BBM SG_ 2147484497 AuxSwitchBbLoad5_cmd 300;
BA_REL_ "GenSigFirstTimeoutTime" BU_SG_REL_ BBM SG_ 2147484497 PBReleaseInhibit_EPBState_ISig_4 3000;
BA_REL_ "GenSigTimeoutTime" BU_SG_REL_ BBM SG_ 2147484497 PBReleaseInhibit_EPBState_ISig_4 300;
BA_REL_ "GenSigFirstTimeoutTime" BU_SG_REL_ IC3 SG_ 2147484497 ExtStaticTrailerBrake_Stat_ISig_ 3000;
BA_REL_ "GenSigTimeoutTime" BU_SG_REL_ IC3 SG_ 2147484497 ExtStaticTrailerBrake_Stat_ISig_ 300;
BA_REL_ "GenSigFirstTimeoutTime" BU_SG_REL_ BBM SG_ 2147484497 ExtStaticTrailerBrake_Stat_ISig_ 3000;
BA_REL_ "GenSigTimeoutTime" BU_SG_REL_ BBM SG_ 2147484497 ExtStaticTrailerBrake_Stat_ISig_ 300;
BA_REL_ "GenSigFirstTimeoutTime" BU_SG_REL_ CIOM SG_ 2147484497 AuxSwitchBbLoad5_Status_ISig_4 3000;
BA_REL_ "GenSigTimeoutTime" BU_SG_REL_ CIOM SG_ 2147484497 AuxSwitchBbLoad5_Status_ISig_4 300;
BA_REL_ "GenSigFirstTimeoutTime" BU_SG_REL_ BBM SG_ 2147484497 AuxSwitchBbLoad5_Status_ISig_4 3000;
BA_REL_ "GenSigTimeoutTime" BU_SG_REL_ BBM SG_ 2147484497 AuxSwitchBbLoad5_Status_ISig_4 300;
BA_REL_ "GenSigFirstTimeoutTime" BU_SG_REL_ IC3 SG_ 2147484497 DoubleFrontAxleSteeringWarning_I 3000;
BA_REL_ "GenSigTimeoutTime" BU_SG_REL_ IC3 SG_ 2147484497 DoubleFrontAxleSteeringWarning_I 300;
BA_REL_ "GenSigFirstTimeoutTime" BU_SG_REL_ BBM SG_ 2147484497 AuxSwitchBbLoad6_cmd 3000;
BA_REL_ "GenSigTimeoutTime" BU_SG_REL_ BBM SG_ 2147484497 AuxSwitchBbLoad6_cmd 300;
BA_REL_ "GenSigFirstTimeoutTime" BU_SG_REL_ IC3 SG_ 2147484497 AcceleratorPedalTestStatus 3000;
BA_REL_ "GenSigTimeoutTime" BU_SG_REL_ IC3 SG_ 2147484497 AcceleratorPedalTestStatus 300;
VAL_ 2147484719 Alcolock_stat_ISig_4 3 "Alcolock_stat_NotAvailable" 2 "Alcolock_stat_Error" 1 "Alcolock_stat_MovementAuthorized" 0 "Alcolock_stat_MovementForbidden" ;
VAL_ 2147484719 CTA_PBReleaseInhibit_ind 7 "PBReleaseInhibit_ind_NotAvailable" 6 "PBReleaseInhibit_ind_Error" 5 "PBReleaseInhibit_ind_Spare" 4 "PBReleaseInhibit_ind_AutoReleaseBeingInhibited" 3 "PBReleaseInhibit_ind_XPRReleaseCommandBeingInhibited" 2 "PBReleaseInhibit_ind_ManualReleaseCommandBeingInhibited" 1 "PBReleaseInhibit_ind_Active" 0 "PBReleaseInhibit_ind_NotActive" ;
VAL_ 2147484719 EngOvrrideCtrlStat_FireTruckMode 3 "FireTruckMode_Spare4" 2 "FireTruckMode_Spare3" 1 "FireTruckMode_Spare2" 0 "FireTruckMode_Spare1" ;
VAL_ 2147484719 EngOvrrideCtrlStat_StartOvrrMode 3 "InactiveActive_NotAvailable" 2 "InactiveActive_Error" 1 "InactiveActive_Active" 0 "InactiveActive_Inactive" ;
VAL_ 2147484719 EngOvrrideCtrlStat_ProtOvrrMode 3 "InactiveActive_NotAvailable" 2 "InactiveActive_Error" 1 "InactiveActive_Active" 0 "InactiveActive_Inactive" ;
VAL_ 2147484683 BatteryTempAlert_rqst_ISig_4 7 "BatteryTempAlert_rqst_NotAvailable" 6 "BatteryTempAlert_rqst_Error" 5 "BatteryTempAlert_rqst_Spare3" 4 "BatteryTempAlert_rqst_Spare2" 3 "BatteryTempAlert_rqst_Spare1" 2 "BatteryTempAlert_rqst_CriticalAlertLowTemp" 1 "BatteryTempAlert_rqst_PreAlertLowTemp" 0 "BatteryTempAlert_rqst_NoAlertRequested" ;
VAL_ 2147484683 APM_TrailerCircPressureStatus_IS 3 "TrailerCircuitPressureStatus_NotAvailable" 2 "TrailerCircuitPressureStatus_Error" 1 "TrailerCircuitPressureStatus_EnabledLowPressureAlert" 0 "TrailerCircuitPressureStatus_DisabledLowPressureAlert" ;
VAL_ 2147484683 BatteryCapacity_ISig_4 15 "BatteryType_NotAvailable" 14 "BatteryType_Error" 13 "BatteryType_NoSelectionMade" 12 "BatteryType_OtherBatteryType" 11 "BatteryType_BatteryType11" 10 "BatteryType_BatteryType10" 9 "BatteryType_BatteryType9" 8 "BatteryType_BatteryType8" 7 "BatteryType_BatteryType7" 6 "BatteryType_BatteryType6" 5 "BatteryType_BatteryType5" 4 "BatteryType_BatteryType4" 3 "BatteryType_BatteryType3" 2 "BatteryType_BatteryType2" 1 "BatteryType_BatteryType1" 0 "BatteryType_BatteryType0" ;
VAL_ 2147484683 Hazard_rqst_ISig_4 3 "InactiveActive_NotAvailable" 2 "InactiveActive_Error" 1 "InactiveActive_Active" 0 "InactiveActive_Inactive" ;
VAL_ 2147484683 Trailer1TPMLostCom_ISig_4 3 "NoYes_NotAvailable" 2 "NoYes_Error" 1 "NoYes_Yes" 0 "NoYes_No" ;
VAL_ 2147484683 BatteryTempAlertRawData_rqst_ISi 7 "BatteryTempAlert_rqst_NotAvailable" 6 "BatteryTempAlert_rqst_Error" 5 "BatteryTempAlert_rqst_Spare3" 4 "BatteryTempAlert_rqst_Spare2" 3 "BatteryTempAlert_rqst_Spare1" 2 "BatteryTempAlert_rqst_CriticalAlertLowTemp" 1 "BatteryTempAlert_rqst_PreAlertLowTemp" 0 "BatteryTempAlert_rqst_NoAlertRequested" ;
VAL_ 2147484683 FPBRMMIStat_FPBRChangeAck_ISig_4 3 "Ack2Bit_NotAvailable" 2 "Ack2Bit_Error" 1 "Ack2Bit_ChangeAcknowledged" 0 "Ack2Bit_NoAction" ;
VAL_ 2147484683 LivBatteryCharging_stat_ISig_4 3 "NotConfirmedConfirmed_NotAvailable" 2 "NotConfirmedConfirmed_Error" 1 "NotConfirmedConfirmed_Confirmed" 0 "NotConfirmedConfirmed_NotConfirmed" ;
VAL_ 2147484683 FPBRMMIStat_FPBRStatusInd_ISig_4 3 "FPBRStatusInd_NotAvailable" 2 "FPBRStatusInd_Changing" 1 "FPBRStatusInd_On" 0 "FPBRStatusInd_Off" ;
VAL_ 2147484683 Trailer2TPMLostCom_ISig_4 3 "NoYes_NotAvailable" 2 "NoYes_Error" 1 "NoYes_Yes" 0 "NoYes_No" ;
VAL_ 2147484680 TPMMateTrailerResp_ISig_4 7 "TPMMateTrailerResp_NotAvailable" 6 "TPMMateTrailerResp_Error" 5 "TPMMateTrailerResp_Spare2" 4 "TPMMateTrailerResp_Spare1" 3 "TPMMateTrailerResp_MatedOK" 2 "TPMMateTrailerResp_Timeout" 1 "TPMMateTrailerResp_Progressing" 0 "TPMMateTrailerResp_NotActive" ;
VAL_ 2147484680 Trailer2TPMLeakageWarning_ISig_4 7 "TPMTireLeakageWarn_NotAvailable" 6 "TPMTireLeakageWarn_Error" 5 "TPMTireLeakageWarn_Spare3" 4 "TPMTireLeakageWarn_Spare2" 3 "TPMTireLeakageWarn_Spare1" 2 "TPMTireLeakageWarn_FastLeakageDetected" 1 "TPMTireLeakageWarn_SlowLeakageDetected" 0 "TPMTireLeakageWarn_NoLeakageDetected" ;
VAL_ 2147484680 TPMAutomaticMating_ISig_4 3 "ActiveStatus_NotAvailable" 2 "ActiveStatus_Error" 1 "ActiveStatus_Active" 0 "ActiveStatus_NotActive" ;
VAL_ 2147484680 Trailer2TPMMatedStatus_ISig_4 3 "NoMatedMated_NotAvailable" 2 "NoMatedMated_Error" 1 "NoMatedMated_Mated" 0 "NoMatedMated_NoMated" ;
VAL_ 2147484680 Trailer1TPMMatedStatus_ISig_4 3 "NoMatedMated_NotAvailable" 2 "NoMatedMated_Error" 1 "NoMatedMated_Mated" 0 "NoMatedMated_NoMated" ;
VAL_ 2147484680 TruckTPMLeakageWarning_ISig_4 7 "TPMTireLeakageWarn_NotAvailable" 6 "TPMTireLeakageWarn_Error" 5 "TPMTireLeakageWarn_Spare3" 4 "TPMTireLeakageWarn_Spare2" 3 "TPMTireLeakageWarn_Spare1" 2 "TPMTireLeakageWarn_FastLeakageDetected" 1 "TPMTireLeakageWarn_SlowLeakageDetected" 0 "TPMTireLeakageWarn_NoLeakageDetected" ;
VAL_ 2147484680 ExtraSideMarkers_FunctStat 3 "InactiveActive_NotAvailable" 2 "InactiveActive_Error" 1 "InactiveActive_Active" 0 "InactiveActive_Inactive" ;
VAL_ 2147484680 Trailer2TPMPressureWarning_ISig_ 7 "TPMPressureWarning_NotAvailable" 6 "TPMPressureWarning_Error" 5 "TPMPressureWarning_Spare" 4 "TPMPressureWarning_ExtremeUnderPressure" 3 "TPMPressureWarning_UnderPressure" 2 "TPMPressureWarning_NoWarningPressure" 1 "TPMPressureWarning_OverPressure" 0 "TPMPressureWarning_ExtremeOverPressure" ;
VAL_ 2147484680 Trailer1TPMPressureWarning_ISig_ 7 "TPMPressureWarning_NotAvailable" 6 "TPMPressureWarning_Error" 5 "TPMPressureWarning_Spare" 4 "TPMPressureWarning_ExtremeUnderPressure" 3 "TPMPressureWarning_UnderPressure" 2 "TPMPressureWarning_NoWarningPressure" 1 "TPMPressureWarning_OverPressure" 0 "TPMPressureWarning_ExtremeOverPressure" ;
VAL_ 2147484680 Trailer1TPMLeakageWarning_ISig_4 7 "TPMTireLeakageWarn_NotAvailable" 6 "TPMTireLeakageWarn_Error" 5 "TPMTireLeakageWarn_Spare3" 4 "TPMTireLeakageWarn_Spare2" 3 "TPMTireLeakageWarn_Spare1" 2 "TPMTireLeakageWarn_FastLeakageDetected" 1 "TPMTireLeakageWarn_SlowLeakageDetected" 0 "TPMTireLeakageWarn_NoLeakageDetected" ;
VAL_ 2147484680 LiftAxle1RequestResponse 15 "LiftAxleRequestResponse_NotAvailable" 14 "LiftAxleRequestResponse_Error" 13 "LiftAxleRequestResponse_Spare8" 12 "LiftAxleRequestResponse_Spare7" 11 "LiftAxleRequestResponse_Spare6" 10 "LiftAxleRequestResponse_Spare5" 9 "LiftAxleRequestResponse_Spare4" 8 "LiftAxleRequestResponse_Spare3" 7 "LiftAxleRequestResponse_Spare2" 6 "LiftAxleRequestResponse_Spare1" 5 "LiftAxleRequestResponse_LowerDeniedRASEC" 4 "LiftAxleRequestResponse_LiftDeniedVersatile" 3 "LiftAxleRequestResponse_LiftDeniedInterAxleClutchEngaged" 2 "LiftAxleRequestResponse_LiftDeniedRearOverload" 1 "LiftAxleRequestResponse_LiftDeniedFrontOverload" 0 "LiftAxleRequestResponse_NoIndication" ;
VAL_ 2147484680 TruckTPMPressureWarning_ISig_4 7 "TPMPressureWarning_NotAvailable" 6 "TPMPressureWarning_Error" 5 "TPMPressureWarning_Spare" 4 "TPMPressureWarning_ExtremeUnderPressure" 3 "TPMPressureWarning_UnderPressure" 2 "TPMPressureWarning_NoWarningPressure" 1 "TPMPressureWarning_OverPressure" 0 "TPMPressureWarning_ExtremeOverPressure" ;
VAL_ 2147484885 Trailer2TPMFailure_ISig_4 3 "InactiveActive_NotAvailable" 2 "InactiveActive_Error" 1 "InactiveActive_Active" 0 "InactiveActive_Inactive" ;
VAL_ 2147484885 TruckTPMTireInfo_Active_ISig_4 3 "TPMTireActive_NotAvailable" 2 "TPMTireActive_Error" 1 "TPMTireActive_TireActivePositioned" 0 "TPMTireActive_TireNotActive" ;
VAL_ 2147484885 TruckTPMFailure_ISig_4 3 "InactiveActive_NotAvailable" 2 "InactiveActive_Error" 1 "InactiveActive_Active" 0 "InactiveActive_Inactive" ;
VAL_ 2147484885 TruckTPMTireInfo_Battery_ISig_4 7 "TPMBatteryStatus_NotAvailable" 6 "TPMBatteryStatus_Error" 5 "TPMBatteryStatus_Spare3" 4 "TPMBatteryStatus_Spare2" 3 "TPMBatteryStatus_Spare1" 2 "TPMBatteryStatus_BatteryVeryLow" 1 "TPMBatteryStatus_BatteryLow" 0 "TPMBatteryStatus_BatteryOK" ;
VAL_ 2147484885 TPMTrailerPositionStat_ISig_4 3 "TrailerPositionsConfirmed_NotAvailable" 2 "TrailerPositionsConfirmed_Error" 1 "TPMTrailerPositionStat_TrailerPositionsConfirmed" 0 "TPMTrailerPositionStat_TrailerPositionsNotConfirmed" ;
VAL_ 2147484885 Trailer1TPMFailure_ISig_4 3 "InactiveActive_NotAvailable" 2 "InactiveActive_Error" 1 "InactiveActive_Active" 0 "InactiveActive_Inactive" ;
VAL_ 2147484885 TruckTPMTireInfo_PresWarn_ISig_4 7 "TPMPressureWarning_NotAvailable" 6 "TPMPressureWarning_Error" 5 "TPMPressureWarning_Spare" 4 "TPMPressureWarning_ExtremeUnderPressure" 3 "TPMPressureWarning_UnderPressure" 2 "TPMPressureWarning_NoWarningPressure" 1 "TPMPressureWarning_OverPressure" 0 "TPMPressureWarning_ExtremeOverPressure" ;
VAL_ 2147484885 TruckTPMTireInfo_LeakageWarn_ISi 7 "TPMTireLeakageWarn_NotAvailable" 6 "TPMTireLeakageWarn_Error" 5 "TPMTireLeakageWarn_Spare3" 4 "TPMTireLeakageWarn_Spare2" 3 "TPMTireLeakageWarn_Spare1" 2 "TPMTireLeakageWarn_FastLeakageDetected" 1 "TPMTireLeakageWarn_SlowLeakageDetected" 0 "TPMTireLeakageWarn_NoLeakageDetected" ;
VAL_ 2147484882 Trailer2TPMTireInfo_LeakageWarn_ 7 "TPMTireLeakageWarn_NotAvailable" 6 "TPMTireLeakageWarn_Error" 5 "TPMTireLeakageWarn_Spare3" 4 "TPMTireLeakageWarn_Spare2" 3 "TPMTireLeakageWarn_Spare1" 2 "TPMTireLeakageWarn_FastLeakageDetected" 1 "TPMTireLeakageWarn_SlowLeakageDetected" 0 "TPMTireLeakageWarn_NoLeakageDetected" ;
VAL_ 2147484882 Trailer2TPMTireInfo_PresWarn_ISi 7 "TPMPressureWarning_NotAvailable" 6 "TPMPressureWarning_Error" 5 "TPMPressureWarning_Spare" 4 "TPMPressureWarning_ExtremeUnderPressure" 3 "TPMPressureWarning_UnderPressure" 2 "TPMPressureWarning_NoWarningPressure" 1 "TPMPressureWarning_OverPressure" 0 "TPMPressureWarning_ExtremeOverPressure" ;
VAL_ 2147484882 Trailer2TPMTireInfo_Battery_ISig 7 "TPMBatteryStatus_NotAvailable" 6 "TPMBatteryStatus_Error" 5 "TPMBatteryStatus_Spare3" 4 "TPMBatteryStatus_Spare2" 3 "TPMBatteryStatus_Spare1" 2 "TPMBatteryStatus_BatteryVeryLow" 1 "TPMBatteryStatus_BatteryLow" 0 "TPMBatteryStatus_BatteryOK" ;
VAL_ 2147484882 Trailer2TPMTireInfo_Active_ISig_ 3 "TPMTireActive_NotAvailable" 2 "TPMTireActive_Error" 1 "TPMTireActive_TireActivePositioned" 0 "TPMTireActive_TireNotActive" ;
VAL_ 2147484879 Trailer1TPMTireInfo_Battery_ISig 7 "TPMBatteryStatus_NotAvailable" 6 "TPMBatteryStatus_Error" 5 "TPMBatteryStatus_Spare3" 4 "TPMBatteryStatus_Spare2" 3 "TPMBatteryStatus_Spare1" 2 "TPMBatteryStatus_BatteryVeryLow" 1 "TPMBatteryStatus_BatteryLow" 0 "TPMBatteryStatus_BatteryOK" ;
VAL_ 2147484879 Trailer1TPMTireInfo_PresWarn_ISi 7 "TPMPressureWarning_NotAvailable" 6 "TPMPressureWarning_Error" 5 "TPMPressureWarning_Spare" 4 "TPMPressureWarning_ExtremeUnderPressure" 3 "TPMPressureWarning_UnderPressure" 2 "TPMPressureWarning_NoWarningPressure" 1 "TPMPressureWarning_OverPressure" 0 "TPMPressureWarning_ExtremeOverPressure" ;
VAL_ 2147484879 Trailer1TPMTireInfo_LeakageWarn_ 7 "TPMTireLeakageWarn_NotAvailable" 6 "TPMTireLeakageWarn_Error" 5 "TPMTireLeakageWarn_Spare3" 4 "TPMTireLeakageWarn_Spare2" 3 "TPMTireLeakageWarn_Spare1" 2 "TPMTireLeakageWarn_FastLeakageDetected" 1 "TPMTireLeakageWarn_SlowLeakageDetected" 0 "TPMTireLeakageWarn_NoLeakageDetected" ;
VAL_ 2147484879 TPMPosOfWMResp_VehiclePos_ISig_4 7 "TPMVehiclePos_NotAvailable" 6 "TPMVehiclePos_Error" 5 "TPMVehiclePos_Trailer5Vehicle" 4 "TPMVehiclePos_Trailer4Vehicle" 3 "TPMVehiclePos_Trailer3Vehicle" 2 "TPMVehiclePos_Trailer2Vehicle" 1 "TPMVehiclePos_Trailer1Vehicle" 0 "TPMVehiclePos_TruckVehicle" ;
VAL_ 2147484879 Trailer1TPMTireInfo_Active_ISig_ 3 "TPMTireActive_NotAvailable" 2 "TPMTireActive_Error" 1 "TPMTireActive_TireActivePositioned" 0 "TPMTireActive_TireNotActive" ;
VAL_ 2147484879 TPMPosOfWMResp_Status_ISig_4 7 "TPMPosStatusResp_NotAvailable" 6 "TPMPosStatusResp_Error" 5 "TPMPosStatusResp_Spare2" 4 "TPMPosStatusResp_Spare1" 3 "TPMPosStatusResp_PositionedOK" 2 "TPMPosStatusResp_Timeout" 1 "TPMPosStatusResp_Progressing" 0 "TPMPosStatusResp_NotActive" ;
VAL_ 2147485051 TruckTPMAxlTireCfg_Axle2_ISig_4 7 "TPMAxleConfig_NotAvailable" 6 "TPMAxleConfig_Error" 5 "TPMAxleConfig_Spare" 4 "TPMAxleConfig_RearAxleWith4Tires" 3 "TPMAxleConfig_RearAxleWith2Tires" 2 "TPMAxleConfig_FrontAxleWith4Tires" 1 "TPMAxleConfig_FrontAxleWith2Tires" 0 "TPMAxleConfig_NotPresent" ;
VAL_ 2147485051 TruckTPMAxlTireCfg_Axle1_ISig_4 7 "TPMAxleConfig_NotAvailable" 6 "TPMAxleConfig_Error" 5 "TPMAxleConfig_Spare" 4 "TPMAxleConfig_RearAxleWith4Tires" 3 "TPMAxleConfig_RearAxleWith2Tires" 2 "TPMAxleConfig_FrontAxleWith4Tires" 1 "TPMAxleConfig_FrontAxleWith2Tires" 0 "TPMAxleConfig_NotPresent" ;
VAL_ 2147485051 TruckTPMAxlTireCfg_Axle5_ISig_4 7 "TPMAxleConfig_NotAvailable" 6 "TPMAxleConfig_Error" 5 "TPMAxleConfig_Spare" 4 "TPMAxleConfig_RearAxleWith4Tires" 3 "TPMAxleConfig_RearAxleWith2Tires" 2 "TPMAxleConfig_FrontAxleWith4Tires" 1 "TPMAxleConfig_FrontAxleWith2Tires" 0 "TPMAxleConfig_NotPresent" ;
VAL_ 2147485051 TruckTPMAxlTireCfg_Axle4_ISig_4 7 "TPMAxleConfig_NotAvailable" 6 "TPMAxleConfig_Error" 5 "TPMAxleConfig_Spare" 4 "TPMAxleConfig_RearAxleWith4Tires" 3 "TPMAxleConfig_RearAxleWith2Tires" 2 "TPMAxleConfig_FrontAxleWith4Tires" 1 "TPMAxleConfig_FrontAxleWith2Tires" 0 "TPMAxleConfig_NotPresent" ;
VAL_ 2147485051 TruckTPMThresCfg_AxleNr_ISig_4 7 "TPMAxleNr_NotAvailable" 6 "TPMAxleNr_Error" 5 "TPMAxleNr_Axle5" 4 "TPMAxleNr_Axle4" 3 "TPMAxleNr_Axle3" 2 "TPMAxleNr_Axle2" 1 "TPMAxleNr_Axle1" 0 "TPMAxleNr_NoRequest" ;
VAL_ 2147485051 TruckTPMAxlTireCfg_Axle3_ISig_4 7 "TPMAxleConfig_NotAvailable" 6 "TPMAxleConfig_Error" 5 "TPMAxleConfig_Spare" 4 "TPMAxleConfig_RearAxleWith4Tires" 3 "TPMAxleConfig_RearAxleWith2Tires" 2 "TPMAxleConfig_FrontAxleWith4Tires" 1 "TPMAxleConfig_FrontAxleWith2Tires" 0 "TPMAxleConfig_NotPresent" ;
VAL_ 2147485050 Trailer2TPMType_ISig_4 3 "TPMTrailerType_NotAvailable" 2 "TPMTrailerType_Error" 1 "TPMTrailerType_ISO11992Trailer" 0 "TPMTrailerType_SKFWirelessTrailer" ;
VAL_ 2147485050 Trailer2TPMAxlTireCfg_Axle1_ISig 7 "TPMAxleConfig_NotAvailable" 6 "TPMAxleConfig_Error" 5 "TPMAxleConfig_Spare" 4 "TPMAxleConfig_RearAxleWith4Tires" 3 "TPMAxleConfig_RearAxleWith2Tires" 2 "TPMAxleConfig_FrontAxleWith4Tires" 1 "TPMAxleConfig_FrontAxleWith2Tires" 0 "TPMAxleConfig_NotPresent" ;
VAL_ 2147485050 Trailer2TPMAxlTireCfg_Axle3_ISig 7 "TPMAxleConfig_NotAvailable" 6 "TPMAxleConfig_Error" 5 "TPMAxleConfig_Spare" 4 "TPMAxleConfig_RearAxleWith4Tires" 3 "TPMAxleConfig_RearAxleWith2Tires" 2 "TPMAxleConfig_FrontAxleWith4Tires" 1 "TPMAxleConfig_FrontAxleWith2Tires" 0 "TPMAxleConfig_NotPresent" ;
VAL_ 2147485050 Trailer2TPMAxlTireCfg_Axle2_ISig 7 "TPMAxleConfig_NotAvailable" 6 "TPMAxleConfig_Error" 5 "TPMAxleConfig_Spare" 4 "TPMAxleConfig_RearAxleWith4Tires" 3 "TPMAxleConfig_RearAxleWith2Tires" 2 "TPMAxleConfig_FrontAxleWith4Tires" 1 "TPMAxleConfig_FrontAxleWith2Tires" 0 "TPMAxleConfig_NotPresent" ;
VAL_ 2147485050 Trailer2TPMAxlTireCfg_Axle5_ISig 7 "TPMAxleConfig_NotAvailable" 6 "TPMAxleConfig_Error" 5 "TPMAxleConfig_Spare" 4 "TPMAxleConfig_RearAxleWith4Tires" 3 "TPMAxleConfig_RearAxleWith2Tires" 2 "TPMAxleConfig_FrontAxleWith4Tires" 1 "TPMAxleConfig_FrontAxleWith2Tires" 0 "TPMAxleConfig_NotPresent" ;
VAL_ 2147485050 Trailer2TPMAxlTireCfg_Axle4_ISig 7 "TPMAxleConfig_NotAvailable" 6 "TPMAxleConfig_Error" 5 "TPMAxleConfig_Spare" 4 "TPMAxleConfig_RearAxleWith4Tires" 3 "TPMAxleConfig_RearAxleWith2Tires" 2 "TPMAxleConfig_FrontAxleWith4Tires" 1 "TPMAxleConfig_FrontAxleWith2Tires" 0 "TPMAxleConfig_NotPresent" ;
VAL_ 2147485050 Trailer2TPMThresCfg_AxleNr_ISig_ 7 "TPMAxleNr_NotAvailable" 6 "TPMAxleNr_Error" 5 "TPMAxleNr_Axle5" 4 "TPMAxleNr_Axle4" 3 "TPMAxleNr_Axle3" 2 "TPMAxleNr_Axle2" 1 "TPMAxleNr_Axle1" 0 "TPMAxleNr_NoRequest" ;
VAL_ 2147485049 Trailer1TPMAxlTireCfg_Axle1_ISig 7 "TPMAxleConfig_NotAvailable" 6 "TPMAxleConfig_Error" 5 "TPMAxleConfig_Spare" 4 "TPMAxleConfig_RearAxleWith4Tires" 3 "TPMAxleConfig_RearAxleWith2Tires" 2 "TPMAxleConfig_FrontAxleWith4Tires" 1 "TPMAxleConfig_FrontAxleWith2Tires" 0 "TPMAxleConfig_NotPresent" ;
VAL_ 2147485049 Trailer1TPMAxlTireCfg_Axle2_ISig 7 "TPMAxleConfig_NotAvailable" 6 "TPMAxleConfig_Error" 5 "TPMAxleConfig_Spare" 4 "TPMAxleConfig_RearAxleWith4Tires" 3 "TPMAxleConfig_RearAxleWith2Tires" 2 "TPMAxleConfig_FrontAxleWith4Tires" 1 "TPMAxleConfig_FrontAxleWith2Tires" 0 "TPMAxleConfig_NotPresent" ;
VAL_ 2147485049 Trailer1TPMAxlTireCfg_Axle5_ISig 7 "TPMAxleConfig_NotAvailable" 6 "TPMAxleConfig_Error" 5 "TPMAxleConfig_Spare" 4 "TPMAxleConfig_RearAxleWith4Tires" 3 "TPMAxleConfig_RearAxleWith2Tires" 2 "TPMAxleConfig_FrontAxleWith4Tires" 1 "TPMAxleConfig_FrontAxleWith2Tires" 0 "TPMAxleConfig_NotPresent" ;
VAL_ 2147485049 Trailer1TPMType_ISig_4 3 "TPMTrailerType_NotAvailable" 2 "TPMTrailerType_Error" 1 "TPMTrailerType_ISO11992Trailer" 0 "TPMTrailerType_SKFWirelessTrailer" ;
VAL_ 2147485049 MaintResetFailureCause 31 "MaintResetFailCause_NotAvailable" 30 "MaintResetFailCause_Error" 29 "MaintResetFailCause_Cond_29_Specific19" 28 "MaintResetFailCause_Cond_28_Specific18" 27 "MaintResetFailCause_Cond_27_Specific17" 26 "MaintResetFailCause_Cond_26_Specific16" 25 "MaintResetFailCause_Cond_25_Specific15" 24 "MaintResetFailCause_Cond_24_Specific14" 23 "MaintResetFailCause_Cond_23_Specific13" 22 "MaintResetFailCause_Cond_22_Specific12" 21 "MaintResetFailCause_Cond_21_Specific11" 20 "MaintResetFailCause_Cond_20_Specific10" 19 "MaintResetFailCause_Cond_19_Specific9" 18 "MaintResetFailCause_Cond_18_Specific8" 17 "MaintResetFailCause_Cond_17_Specific7" 16 "MaintResetFailCause_Cond_16_Specific6" 15 "MaintResetFailCause_Cond_15_Specific5" 14 "MaintResetFailCause_Cond_14_Specific4" 13 "MaintResetFailCause_Cond_13_Specific3" 12 "MaintResetFailCause_Cond_12_Specific2" 11 "MaintResetFailCause_Cond_11_Specific1" 10 "MaintResetFailCause_Cond_10_Specific0" 9 "MaintResetFailCause_Cond_09_spare4" 8 "MaintResetFailCause_Cond_08_spare3" 7 "MaintResetFailCause_Cond_07_spare2" 6 "MaintResetFailCause_Cond_06_spare1" 5 "MaintResetFailCause_Cond_05_InvalidSelection" 4 "MaintResetFailCause_Cond_04_ComponentResetTime_Out" 3 "MaintResetFailCause_Cond_03_RejectedByComponent" 2 "MaintResetFailCause_Cond_02_InvalidDate_Time" 1 "MaintResetFailCause_Cond_01_InvalidEngineTime" 0 "MaintResetFailCause_Cond_00_InvalidVehicleDistance" ;
VAL_ 2147485049 Trailer1TPMThresCfg_AxleNr_ISig_ 7 "TPMAxleNr_NotAvailable" 6 "TPMAxleNr_Error" 5 "TPMAxleNr_Axle5" 4 "TPMAxleNr_Axle4" 3 "TPMAxleNr_Axle3" 2 "TPMAxleNr_Axle2" 1 "TPMAxleNr_Axle1" 0 "TPMAxleNr_NoRequest" ;
VAL_ 2147485049 Trailer1TPMAxlTireCfg_Axle4_ISig 7 "TPMAxleConfig_NotAvailable" 6 "TPMAxleConfig_Error" 5 "TPMAxleConfig_Spare" 4 "TPMAxleConfig_RearAxleWith4Tires" 3 "TPMAxleConfig_RearAxleWith2Tires" 2 "TPMAxleConfig_FrontAxleWith4Tires" 1 "TPMAxleConfig_FrontAxleWith2Tires" 0 "TPMAxleConfig_NotPresent" ;
VAL_ 2147485049 Trailer1TPMAxlTireCfg_Axle3_ISig 7 "TPMAxleConfig_NotAvailable" 6 "TPMAxleConfig_Error" 5 "TPMAxleConfig_Spare" 4 "TPMAxleConfig_RearAxleWith4Tires" 3 "TPMAxleConfig_RearAxleWith2Tires" 2 "TPMAxleConfig_FrontAxleWith4Tires" 1 "TPMAxleConfig_FrontAxleWith2Tires" 0 "TPMAxleConfig_NotPresent" ;
VAL_ 2147484894 FogLight_Front_cmd_ISig_4 3 "InactiveActive_NotAvailable" 2 "InactiveActive_Error" 1 "InactiveActive_Active" 0 "InactiveActive_Inactive" ;
VAL_ 2147484891 SelfStartAssistSwitch_Input_ISig 3 "Request_NotAvailable" 2 "Request_Error" 1 "Request_RequestActive" 0 "Request_NotRequested" ;
VAL_ 2147484891 BatterySOCAlertRawData_rqst_ISig 7 "BatterySOCAlert_rqst_NotAvailable" 6 "BatterySOCAlert_rqst_ErrorIndicator" 5 "BatterySOCAlert_rqst_SpareValue_02" 4 "BatterySOCAlert_rqst_SpareValue_01" 3 "BatterySOCAlert_rqst_SpareValue" 2 "BatterySOCAlert_rqst_CriticalAlert" 1 "BatterySOCAlert_rqst_PreAlert" 0 "BatterySOCAlert_rqst_NoAlertRequested" ;
VAL_ 2147484891 LivBatDisconnectDetectStat_ISig_ 3 "LivBatDisconnectDetectStat_Not_Available" 2 "LivBatDisconnectDetectStat_Error" 1 "LivBatDisconnectDetectStat_Battery_Disconnected" 0 "LivBatDisconnectDetectStat_Battery_NotDisconnected" ;
VAL_ 2147484891 SelfStartAssist_stat_ISig_4 3 "Request_NotAvailable" 2 "Request_Error" 1 "Request_RequestActive" 0 "Request_NotRequested" ;
VAL_ 2147484891 JumpChargeAlert_stat_ISig_4 7 "JumpChargeAlert_stat_NotAvailable" 6 "JumpChargeAlert_stat_Error" 5 "JumpChargeAlert_stat_Spare3" 4 "JumpChargeAlert_stat_Spare2" 3 "JumpChargeAlert_stat_Spare1" 2 "JumpChargeAlert_stat_InternalFailure" 1 "JumpChargeAlert_stat_JumpVoltage_tooHigh" 0 "JumpChargeAlert_stat_NoAlert" ;
VAL_ 2147484891 GChargerStatus_ISig_4 7 "GridCharger_stat_NotAvailable" 6 "GridCharger_stat_Error" 5 "GridCharger_stat_Spare3" 4 "GridCharger_stat_GridChargerFailure" 3 "GridCharger_stat_MaintenanceCharging" 2 "GridCharger_stat_Charging" 1 "GridCharger_stat_Connected" 0 "GridCharger_stat_NotConnected" ;
VAL_ 2147484891 ShortStopHeater_status_ISig_4 7 "ShortStopHeaterStatus_NotAvailable" 6 "ShortStopHeaterStatus_Error" 5 "ShortStopHeaterStatus_Spare3" 4 "ShortStopHeaterStatus_Spare2" 3 "ShortStopHeaterStatus_Spare1" 2 "ShortStopHeaterStatus_ActivatedAndPumpNotEngaged" 1 "ShortStopHeaterStatus_ActivatedAndPumpEngaged" 0 "ShortStopHeaterStatus_NotActivated" ;
VAL_ 2147484891 StartBatteryDisplay_stat_ISig_4 7 "StartBatteryDisplay_NotAvailable" 6 "StartBatteryDisplay_Error" 5 "StartBatteryDisplay_StartBattery_ShortCircuit" 4 "StartBatteryDisplay_StartBattery_OverVoltage" 3 "StartBatteryDisplay_StartBattery_OpenCircuit" 2 "StartBatteryDisplay_StartBattery_Issue" 1 "StartBatteryDisplay_StartBattery_Charged" 0 "StartBatteryDisplay_StartBattery_Charging" ;
VAL_ 2147484707 ReducedLoadMode_stat_ISig_4 3 "ReducedLoadMode_stat_NotAvailable" 2 "ReducedLoadMode_stat_Error" 1 "ReducedLoadMode_stat_ReducedLoadMode" 0 "ReducedLoadMode_stat_NormalMode" ;
VAL_ 2147484707 BatterySOCAlert_rqst_ISig_4 7 "BatterySOCAlert_rqst_NotAvailable" 6 "BatterySOCAlert_rqst_ErrorIndicator" 5 "BatterySOCAlert_rqst_SpareValue_02" 4 "BatterySOCAlert_rqst_SpareValue_01" 3 "BatterySOCAlert_rqst_SpareValue" 2 "BatterySOCAlert_rqst_CriticalAlert" 1 "BatterySOCAlert_rqst_PreAlert" 0 "BatterySOCAlert_rqst_NoAlertRequested" ;
VAL_ 2147484573 MaintOilQuality 7 "OilQuality_NotAvailable" 6 "OilQuality_Error" 5 "OilQuality_NoSelectionMade" 4 "OilQuality_VDS4" 3 "OilQuality_VDS3" 2 "OilQuality_VDS2" 1 "OilQuality_VDSVDS3WithFixedInterval" 0 "OilQuality_NonVDS_VDS4WithFixedInterval" ;
VAL_ 2147484573 ECSLimpHomeNotification_ISig_4 7 "ECSLimpHomeNotification_NotAvailable" 6 "ECSLimpHomeNotification_Error" 5 "ECSLimpHomeNotification_LimpHomeMode5" 4 "ECSLimpHomeNotification_LimpHomeMode4" 3 "ECSLimpHomeNotification_LimpHomeMode3" 2 "ECSLimpHomeNotification_LimpHomeMode2" 1 "ECSLimpHomeNotification_LimpHomeMode1" 0 "ECSLimpHomeNotification_NoLimpHomeMode" ;
VAL_ 2147484573 MaintenanceResetStatus 7 "MaintenanceResetStatus_NotAvailable" 6 "MaintenanceResetStatus_Error" 5 "MaintenanceResetStatus_ResetFailed" 4 "MaintenanceResetStatus_ResetSuccessful" 3 "MaintenanceResetStatus_ResetOngoing" 2 "MaintenanceResetStatus_Spare_02" 1 "MaintenanceResetStatus_Spare_01" 0 "MaintenanceResetStatus_NoResetRequested" ;
VAL_ 2147484573 FirstAxleLowerPrioSelected_ISig_ 7 "FirstAxleLowerPrio_NotAvailable" 6 "FirstAxleLowerPrio_Error" 5 "FirstAxleLowerPrio_Reserved_03" 4 "FirstAxleLowerPrio_Reserved_02" 3 "FirstAxleLowerPrio_Reserved_01" 2 "FirstAxleLowerPrio_Reserved" 1 "FirstAxleLowerPrio_LowerPusher" 0 "FirstAxleLowerPrio_LowerTag" ;
VAL_ 2147484573 MaintOilReset 3 "Request_NotAvailable" 2 "Request_Error" 1 "Request_RequestActive" 0 "Request_NotRequested" ;
VAL_ 2147484573 RssInhibStartEngine_rqst 3 "OffOn_NotAvailable" 2 "OffOn_Error" 1 "OffOn_On" 0 "OffOn_Off" ;
VAL_ 2147484573 PositionLightRequest_status 3 "OffOn_NotAvailable" 2 "OffOn_Error" 1 "OffOn_On" 0 "OffOn_Off" ;
VAL_ 2147484573 ExtraBBTailLiftStatus_ISig_4 3 "InactiveActive_NotAvailable" 2 "InactiveActive_Error" 1 "InactiveActive_Active" 0 "InactiveActive_Inactive" ;
VAL_ 2147484573 MaintenanceNotification_ISig_4 7 "MaintenanceNotification_NotAvailable" 6 "MaintenanceNotification_Error" 5 "MaintenanceNotification_Spare_02" 4 "MaintenanceNotification_Spare_01" 3 "MaintenanceNotification_Spare" 2 "MaintenanceNotification_WarningNotification" 1 "MaintenanceNotification_PreWarningNotification" 0 "MaintenanceNotification_NoNotification" ;
VAL_ 2147484573 ExtraBBSlidable5thWheelStatus 3 "InactiveActive_NotAvailable" 2 "InactiveActive_Error" 1 "InactiveActive_Active" 0 "InactiveActive_Inactive" ;
VAL_ 2147484573 ParkBrakeReleasePossible_stat 3 "ParkBrakeReleasePossible_stat_NotAvailable" 2 "ParkBrakeReleasePossible_stat_Error" 1 "ParkBrakeReleasePossible_stat_Possible_PressureOK" 0 "ParkBrakeReleasePossible_stat_NotPossible_LowerPressure" ;
VAL_ 2147484573 LoadDistributionALDChangeACK_ISi 7 "LoadDistributionALDChangeACK_NotAvailable" 6 "LoadDistributionALDChangeACK_Error" 5 "LoadDistributionALDChangeACK_SystemDeniedVersatile" 4 "LoadDistributionALDChangeACK_Spare_01" 3 "LoadDistributionALDChangeACK_Spare" 2 "LoadDistributionALDChangeACK_LoadShiftDeniedOverspeed" 1 "LoadDistributionALDChangeACK_ChangeAcknowledged" 0 "LoadDistributionALDChangeACK_NoAction" ;
VAL_ 2147484573 ParkBrakeWorkshopMode_ISig_4 3 "ParkBrakeWorkshopMode_NotAvailable" 2 "ParkBrakeWorkshopMode_Error" 1 "ParkBrakeWorkshopMode_WorkshopMode" 0 "ParkBrakeWorkshopMode_NormalMode" ;
VAL_ 2147484573 ExtraBBContainerUnlockStatus 3 "InactiveActive_NotAvailable" 2 "InactiveActive_Error" 1 "InactiveActive_Active" 0 "InactiveActive_Inactive" ;
VAL_ 2147484573 MainBeamRequest_status_ISig_4 3 "OffOn_NotAvailable" 2 "OffOn_Error" 1 "OffOn_On" 0 "OffOn_Off" ;
VAL_ 2147484573 ExtraBBCraneStatus_ISig_4 7 "ExtraBBCraneStatus_NotAvailable" 6 "ExtraBBCraneStatus_Error" 5 "ExtraBBCraneStatus_Spare_02" 4 "ExtraBBCraneStatus_Spare_01" 3 "ExtraBBCraneStatus_Spare" 2 "ExtraBBCraneStatus_Active" 1 "ExtraBBCraneStatus_Enable" 0 "ExtraBBCraneStatus_Disable" ;
VAL_ 2147484573 AirCompressorStatus 3 "InactiveActive_NotAvailable" 2 "InactiveActive_Error" 1 "InactiveActive_Active" 0 "InactiveActive_Inactive" ;
VAL_ 2147484573 TrailerABSStatus_ISig_4 3 "TrailerABSStatus_NotAvailable" 2 "TrailerABSStatus_ErrorIndicator" 1 "TrailerABSStatus_OK" 0 "TrailerABSStatus_Error" ;
VAL_ 2147484573 RegenInhibitVehicleHeight_ISig_4 3 "ActiveStatus_NotAvailable" 2 "ActiveStatus_Error" 1 "ActiveStatus_Active" 0 "ActiveStatus_NotActive" ;
VAL_ 2147484573 PoorAirPressureInfo 3 "PoorAirPressureInfo_NotAvailable" 2 "PoorAirPressureInfo_Error" 1 "PoorAirPressureInfo_PoorAirPressure" 0 "PoorAirPressureInfo_NormalPressure" ;
VAL_ 2147484573 FogLightRearRequest_stat 3 "InactiveActive_NotAvailable" 2 "InactiveActive_Error" 1 "InactiveActive_Active" 0 "InactiveActive_Inactive" ;
VAL_ 2147484573 MainBeam_cmd_ISig_4 7 "MainBeam_cmd_NotAvailable" 6 "MainBeam_cmd_SpareValue_03" 5 "MainBeam_cmd_SpareValue_02" 4 "MainBeam_cmd_SpareValue_01" 3 "MainBeam_cmd_SpareValue" 2 "MainBeam_cmd_MainBeamFlashOn" 1 "MainBeam_cmd_MainBeamOn" 0 "MainBeam_cmd_MainBeamOff" ;
VAL_ 2147484573 FrontParkBrakeOverrideInd_ISig_4 3 "FrontParkBrakeOverrideInd_NotAvailable" 2 "FrontParkBrakeOverrideInd_Error" 1 "FrontParkBrakeOverrideInd_FailedToOverride" 0 "FrontParkBrakeOverrideInd_OK" ;
VAL_ 2147484497 AuxSwitchBbLoad4_cmd 3 "NotDriven_Driven_NotAvailable" 2 "NotDriven_Driven_Error" 1 "NotDriven_Driven_Driven" 0 "NotDriven_Driven_NotDriven" ;
VAL_ 2147484497 AuxSwitchBbLoad1_Status_ISig_4 3 "InactiveActive_NotAvailable" 2 "InactiveActive_Error" 1 "InactiveActive_Active" 0 "InactiveActive_Inactive" ;
VAL_ 2147484497 AuxSwitchBbLoad3_cmd 3 "NotDriven_Driven_NotAvailable" 2 "NotDriven_Driven_Error" 1 "NotDriven_Driven_Driven" 0 "NotDriven_Driven_NotDriven" ;
VAL_ 2147484497 MainBeam_rqst 7 "MainBeam_rqst_NotAvailable" 6 "MainBeam_rqst_Error" 5 "MainBeam_rqst_SpareValue3" 4 "MainBeam_rqst_SpareValue2" 3 "MainBeam_rqst_SpareValue1" 2 "MainBeam_rqst_FlashToPassRequest" 1 "MainBeam_rqst_MainBeamRequest" 0 "MainBeam_rqst_DippedBeamRequest" ;
VAL_ 2147484497 AuxSwitchBbLoad4_Status_ISig_4 3 "InactiveActive_NotAvailable" 2 "InactiveActive_Error" 1 "InactiveActive_Active" 0 "InactiveActive_Inactive" ;
VAL_ 2147484497 BrakeLightConvoy_rqst_ISig_4 3 "OffOn_NotAvailable" 2 "OffOn_Error" 1 "OffOn_On" 0 "OffOn_Off" ;
VAL_ 2147484497 DoorWarningLight_cmd_ISig_4 3 "OffOn_NotAvailable" 2 "OffOn_Error" 1 "OffOn_On" 0 "OffOn_Off" ;
VAL_ 2147484497 BlackOutandConvoyMode_rqst_ISig_ 7 "BlackOutandConvoyMode_rqst_NotAvailable" 6 "BlackOutandConvoyMode_rqst_Error" 5 "BlackOutandConvoyMode_rqst_SpareValue_02" 4 "BlackOutandConvoyMode_rqst_SpareValue_01" 3 "BlackOutandConvoyMode_rqst_SpareValue" 2 "BlackOutandConvoyMode_rqst_ConvoyMode" 1 "BlackOutandConvoyMode_rqst_BlackOutMode" 0 "BlackOutandConvoyMode_rqst_NormalMode" ;
VAL_ 2147484497 DirIndicatorRqstLights_stat 7 "DirIndicatorRqstLights_stat_NotAvailable" 6 "DirIndicatorRqstLights_stat_Error" 5 "DirIndicatorRqstLights_stat_SpareValue_01" 4 "DirIndicatorRqstLights_stat_SpareValue" 3 "DirIndicatorRqstLights_stat_RightAndLeftON_Hazard" 2 "DirIndicatorRqstLights_stat_RightDirectionIndicatorON" 1 "DirIndicatorRqstLights_stat_LeftDirectionIndicatorON" 0 "DirIndicatorRqstLights_stat_DirectionIndicatorsOFF" ;
VAL_ 2147484497 DippedBeamRequest_status 3 "OffOn_NotAvailable" 2 "OffOn_Error" 1 "OffOn_On" 0 "OffOn_Off" ;
VAL_ 2147484497 AuxSwitchBbLoad3_Status_ISig_4 3 "InactiveActive_NotAvailable" 2 "InactiveActive_Error" 1 "InactiveActive_Active" 0 "InactiveActive_Inactive" ;
VAL_ 2147484497 DoorInstepLight_cmd_ISig_4 3 "OffOn_NotAvailable" 2 "OffOn_Error" 1 "OffOn_On" 0 "OffOn_Off" ;
VAL_ 2147484497 DRLRequest_status 3 "OffOn_NotAvailable" 2 "OffOn_Error" 1 "OffOn_On" 0 "OffOn_Off" ;
VAL_ 2147484497 AuxSwitchBbLoad6_Status_ISig_4 3 "InactiveActive_NotAvailable" 2 "InactiveActive_Error" 1 "InactiveActive_Active" 0 "InactiveActive_Inactive" ;
VAL_ 2147484497 AuxSwitchBbLoad2_Status_ISig_4 3 "InactiveActive_NotAvailable" 2 "InactiveActive_Error" 1 "InactiveActive_Active" 0 "InactiveActive_Inactive" ;
VAL_ 2147484497 AuxSwitchBbLoad5_cmd 3 "NotDriven_Driven_NotAvailable" 2 "NotDriven_Driven_Error" 1 "NotDriven_Driven_Driven" 0 "NotDriven_Driven_NotDriven" ;
VAL_ 2147484497 PBReleaseInhibit_EPBState_ISig_4 7 "PBReleaseInhibit_State_NotAvailable" 6 "PBReleaseInhibit_State_Error" 5 "PBReleaseInhibit_State_AutoReleaseCommandBeingInhibited" 4 "PBReleaseInhibit_State_XPRReleaseCommandBeingInhibited" 3 "PBReleaseInhibit_State_ManualReleaseCommandBeingInhibited" 2 "PBReleaseInhibit_State_Active" 1 "PBReleaseInhibit_State_FullyOperationalNotActive" 0 "PBReleaseInhibit_State_NotOperational" ;
VAL_ 2147484497 ExtStaticTrailerBrake_Stat_ISig_ 3 "InactiveActive_NotAvailable" 2 "InactiveActive_Error" 1 "InactiveActive_Active" 0 "InactiveActive_Inactive" ;
VAL_ 2147484497 AuxSwitchBbLoad5_Status_ISig_4 3 "InactiveActive_NotAvailable" 2 "InactiveActive_Error" 1 "InactiveActive_Active" 0 "InactiveActive_Inactive" ;
VAL_ 2147484497 DoubleFrontAxleSteeringWarning_I 3 "DoubleFrontAxleSteeringWarning_NotAvailiable" 2 "DoubleFrontAxleSteeringWarning_Error" 1 "DoubleFrontAxleSteeringWarning_DoubleFrAxleSteeringBackupMode" 0 "DoubleFrontAxleSteeringWarning_NoRequest" ;
VAL_ 2147484497 AuxSwitchBbLoad6_cmd 3 "NotDriven_Driven_NotAvailable" 2 "NotDriven_Driven_Error" 1 "NotDriven_Driven_Driven" 0 "NotDriven_Driven_NotDriven" ;
VAL_ 2147484497 AcceleratorPedalTestStatus 7 "AcceleratorPedalTestStatus_NotAvailable" 6 "AcceleratorPedalTestStatus_Error" 5 "AcceleratorPedalTestStatus_TestFailed" 4 "AcceleratorPedalTestStatus_TestFinished" 3 "AcceleratorPedalTestStatus_Step3" 2 "AcceleratorPedalTestStatus_Step2" 1 "AcceleratorPedalTestStatus_Step1" 0 "AcceleratorPedalTestStatus_Inactive" ;
SIG_GROUP_ 2147484719 EngOvrrideCtrlStat_sg 1 : EngOvrrideCtrlStat_FireTruckMode EngOvrrideCtrlStat_StartOvrrMode EngOvrrideCtrlStat_ProtOvrrMode;
SIG_GROUP_ 2147484683 FPBRMMIStat_sg_ISig_4 1 : FPBRMMIStat_FPBRChangeAck_ISig_4 FPBRMMIStat_FPBRStatusInd_ISig_4;
SIG_GROUP_ 2147484885 TruckTPMTireInfo_sg_ISig_4 1 : TruckTPMTireInfo_Active_ISig_4 TruckTPMTireInfo_TireId_ISig_4 TruckTPMTireInfo_Battery_ISig_4 TruckTPMTireInfo_Temperature_ISi TruckTPMTireInfo_RefPres_ISig_4 TruckTPMTireInfo_Pressure_ISig_4 TruckTPMTireInfo_PresWarn_ISig_4 TruckTPMTireInfo_LeakageWarn_ISi;
SIG_GROUP_ 2147484882 Trailer2TPMTireInfo_sg_ISig_4 1 : Trailer2TPMTireInfo_LeakageWarn_ Trailer2TPMTireInfo_RefPres_ISig Trailer2TPMTireInfo_PresWarn_ISi Trailer2TPMTireInfo_Pressure_ISi Trailer2TPMTireInfo_Temperature_ Trailer2TPMTireInfo_TireId_ISig_ Trailer2TPMTireInfo_Battery_ISig Trailer2TPMTireInfo_Active_ISig_;
SIG_GROUP_ 2147484879 TPMPosOfWMResp_sg_ISig_4 1 : TPMPosOfWMResp_VehiclePos_ISig_4 TPMPosOfWMResp_Status_ISig_4 TPMPosOfWMResp_TireId_ISig_4;
SIG_GROUP_ 2147484879 Trailer1TPMTireInfo_sg_ISig_4 1 : Trailer1TPMTireInfo_Battery_ISig Trailer1TPMTireInfo_Pressure_ISi Trailer1TPMTireInfo_PresWarn_ISi Trailer1TPMTireInfo_LeakageWarn_ Trailer1TPMTireInfo_TireId_ISig_ Trailer1TPMTireInfo_RefPres_ISig Trailer1TPMTireInfo_Temperature_ Trailer1TPMTireInfo_Active_ISig_;
SIG_GROUP_ 2147485051 TruckTPMAxlTireCfg_sg_ISig_4 1 : TruckTPMAxlTireCfg_Axle2_ISig_4 TruckTPMAxlTireCfg_Axle1_ISig_4 TruckTPMAxlTireCfg_Axle5_ISig_4 TruckTPMAxlTireCfg_Axle4_ISig_4 TruckTPMAxlTireCfg_Axle3_ISig_4;
SIG_GROUP_ 2147485051 TruckTPMThresCfg_sg_ISig_4 1 : TruckTPMThresCfg_OverPres_ISig_4 TruckTPMThresCfg_ExtUnderPres_IS TruckTPMThresCfg_AxleNr_ISig_4 TruckTPMThresCfg_UnderPres_ISig_ TruckTPMThresCfg_ExtOverPres_ISi;
SIG_GROUP_ 2147485050 Trailer2TPMAxlTireCfg_sg_ISig_4 1 : Trailer2TPMAxlTireCfg_Axle1_ISig Trailer2TPMAxlTireCfg_Axle3_ISig Trailer2TPMAxlTireCfg_Axle2_ISig Trailer2TPMAxlTireCfg_Axle5_ISig Trailer2TPMAxlTireCfg_Axle4_ISig;
SIG_GROUP_ 2147485050 Trailer2TPMThresCfg_sg_ISig_4 1 : Trailer2TPMThresCfg_OverPres_ISi Trailer2TPMThresCfg_AxleNr_ISig_ Trailer2TPMThresCfg_ExtOverPres_ Trailer2TPMThresCfg_UnderPres_IS Trailer2TPMThresCfg_ExtUnderPres;
SIG_GROUP_ 2147485049 Trailer1TPMAxlTireCfg_sg_ISig_4 1 : Trailer1TPMAxlTireCfg_Axle1_ISig Trailer1TPMAxlTireCfg_Axle2_ISig Trailer1TPMAxlTireCfg_Axle5_ISig Trailer1TPMAxlTireCfg_Axle4_ISig Trailer1TPMAxlTireCfg_Axle3_ISig;
SIG_GROUP_ 2147485049 Trailer1TPMThresCfg_sg_ISig_4 1 : Trailer1TPMThresCfg_ExtOverPres_ Trailer1TPMThresCfg_OverPres_ISi Trailer1TPMThresCfg_UnderPres_IS Trailer1TPMThresCfg_ExtUnderPres Trailer1TPMThresCfg_AxleNr_ISig_;
SIG_GROUP_ 2147485056 MaintService_sg_ISig_4_580 1 : MaintService_ServiceCalendarTime MaintService_EngTimeID_ISig_4_58 MaintService_DistID_ISig_4_580 MaintService_ServiceDistance_ISi MaintService_ServiceEngineTime_I MaintService_CalDateID_ISig_4_58;
SIG_GROUP_ 2147485046 MaintService_sg_ISig_4_576 1 : MaintService_ServiceEngineT_0000 MaintService_EngTimeID_ISig_4_57 MaintService_DistID_ISig_4_576 MaintService_ServiceDistanc_0000 MaintService_CalDateID_ISig_4_57 MaintService_ServiceCalenda_0000;
